[part 3 of 3: packages /AR_GEE_SWC to /AR_IHM_SWC]
AUTOSAR XML (schema 3.1.1)
package /AR_GEE_SWC
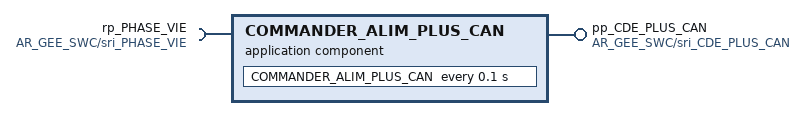
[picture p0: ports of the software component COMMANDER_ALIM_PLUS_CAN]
  application software component type COMMANDER_ALIM_PLUS_CAN
    require port rp_PHASE_VIE: unqueued-receiver-com-spec{data-element=sri_PHASE_VIE/PHASE_VIE, handle-invalid=KEEP, init-value=cst_UInt8_init/uint8_init, resync-time=0.0}, required-interface=AR_GEE_SWC/sri_PHASE_VIE
    provide port pp_CDE_PLUS_CAN: unqueued-sender-com-spec{data-element=sri_CDE_PLUS_CAN/CDE_PLUS_CAN, init-value=cst_Boolean_init/boolean_init}, provided-interface=AR_GEE_SWC/sri_CDE_PLUS_CAN
  composition type GEE_SEE
    require port rp_PHASE_VIE: unqueued-receiver-com-spec{data-element=sri_PHASE_VIE/PHASE_VIE, handle-invalid=KEEP, init-value=cst_UInt8_init/uint8_init, resync-time=0.0}, required-interface=AR_GEE_SWC/sri_PHASE_VIE
    provide port pp_CDE_PLUS_CAN: unqueued-sender-com-spec{data-element=sri_CDE_PLUS_CAN/CDE_PLUS_CAN, init-value=cst_Boolean_init/boolean_init}, provided-interface=AR_GEE_SWC/sri_CDE_PLUS_CAN
    require port rp_CAN_BACKBONE_ACTIVITY: unqueued-receiver-com-spec{data-element=sri_CAN_BACKBONE_ACTIVITY/CAN_BACKBONE_ACTIVITY, handle-invalid=KEEP, init-value=cst_Boolean_init/boolean_init, resync-time=0.0}, required-interface=AR_GEE_SWC/sri_CAN_BACKBONE_ACTIVITY
    provide port pp_CDE_LOGIC_ECM_FRONT: unqueued-sender-com-spec{data-element=sri_CDE_LOGIC_ECM_FRONT/CDE_LOGIC_ECM_FRONT, init-value=cst_Boolean_init/boolean_init}, provided-interface=AR_GEE_SWC/sri_CDE_LOGIC_ECM_FRONT
    require port rp_ETAT_MT: unqueued-receiver-com-spec{data-element=ETAT_MT, handle-invalid=KEEP, init-value=cst_UInt8_init/uint8_init, resync-time=0.0}, required-interface=sri_ETAT_MT
    provide port pp_INFO_GMP: unqueued-sender-com-spec{data-element=sri_INFO_GMP/INFO_GMP, init-value=cst_UInt8_init/uint8_init}, provided-interface=AR_GEE_SWC/sri_INFO_GMP
    provide port pp_ETAT_GMP: unqueued-sender-com-spec{data-element=ETAT_GMP, init-value=cst_UInt8_init/uint8_init}, provided-interface=sri_ETAT_GMP
    require port rp_E_APC: unqueued-receiver-com-spec{data-element=E_APC, handle-invalid=KEEP, init-value=cst_UInt8_init/uint8_init, resync-time=0.0}, required-interface=sri_E_APC
    require port rp_E_DEM: unqueued-receiver-com-spec{data-element=E_DEM, handle-invalid=KEEP, init-value=cst_UInt8_init/uint8_init, resync-time=0.0}, required-interface=sri_E_DEM
    provide port pp_ETAT_PRINCIP_SEV: unqueued-sender-com-spec{data-element=sri_ETAT_PRINCIP_SEV/ETAT_PRINCIP_SEV, init-value=cst_UInt8_init/uint8_init}, provided-interface=AR_GEE_SWC/sri_ETAT_PRINCIP_SEV
    provide port pp_CDE_APC: unqueued-sender-com-spec{data-element=sri_CDE_APC/CDE_APC, init-value=cst_Boolean_init/boolean_init}, provided-interface=AR_GEE_SWC/sri_CDE_APC
    require port rp_ETAT_RESEAU_ELECTRIQUE: unqueued-receiver-com-spec{data-element=sri_ETAT_RESEAU_ELECTRIQUE/ETAT_RESEAU_ELECTRIQUE, handle-invalid=KEEP, init-value=cst_UInt8_init/uint8_init, resync-time=0.0}, required-interface=AR_GEE_SWC/sri_ETAT_RESEAU_ELECTRIQUE
    provide port pp_CDE_ACC: unqueued-sender-com-spec{data-element=CDE_ACC, init-value=cst_Boolean_init/boolean_init}, provided-interface=sri_CDE_ACC
    6 x component:
      COMMANDER_ALIM_PLUS_CAN: type=COMMANDER_ALIM_PLUS_CAN
      COMMANDER_ALIM_LOGIC_ECM_FRONT: type=COMMANDER_ALIM_LOGIC_ECM_FRONT
      DETERMINER_INFO_GMP: type=DETERMINER_INFO_GMP
      DETERMINER_ETAT_PRINCIP_SEV: type=DETERMINER_ETAT_PRINCIP_SEV
      COMMANDER_ALIM_APC: type=COMMANDER_ALIM_APC
      COMMANDER_ALIM_ACC: type=COMMANDER_ALIM_ACC
    connect DETERMINER_ETAT_PRINCIP_SEV.pp_ETAT_PRINCIP_SEV -> COMMANDER_ALIM_APC.rp_ETAT_PRINCIP_SEV
    connect DETERMINER_ETAT_PRINCIP_SEV.pp_ETAT_PRINCIP_SEV -> COMMANDER_ALIM_ACC.rp_ETAT_PRINCIP_SEV
    delegate COMMANDER_ALIM_PLUS_CAN.rp_PHASE_VIE <-> outer port GEE_SEE/rp_PHASE_VIE
    delegate COMMANDER_ALIM_PLUS_CAN.pp_CDE_PLUS_CAN <-> outer port GEE_SEE/pp_CDE_PLUS_CAN
    delegate COMMANDER_ALIM_LOGIC_ECM_FRONT.rp_CAN_BACKBONE_ACTIVITY <-> outer port GEE_SEE/rp_CAN_BACKBONE_ACTIVITY
    delegate COMMANDER_ALIM_LOGIC_ECM_FRONT.pp_CDE_LOGIC_ECM_FRONT <-> outer port GEE_SEE/pp_CDE_LOGIC_ECM_FRONT
    delegate DETERMINER_INFO_GMP.rp_ETAT_MT <-> outer port GEE_SEE/rp_ETAT_MT
    delegate DETERMINER_INFO_GMP.pp_INFO_GMP <-> outer port GEE_SEE/pp_INFO_GMP
    delegate DETERMINER_INFO_GMP.pp_ETAT_GMP <-> outer port GEE_SEE/pp_ETAT_GMP
    delegate DETERMINER_ETAT_PRINCIP_SEV.rp_E_APC <-> outer port GEE_SEE/rp_E_APC
    delegate DETERMINER_ETAT_PRINCIP_SEV.rp_E_DEM <-> outer port GEE_SEE/rp_E_DEM
    delegate DETERMINER_ETAT_PRINCIP_SEV.pp_ETAT_PRINCIP_SEV <-> outer port GEE_SEE/pp_ETAT_PRINCIP_SEV
    delegate COMMANDER_ALIM_APC.pp_CDE_APC <-> outer port GEE_SEE/pp_CDE_APC
    delegate COMMANDER_ALIM_ACC.rp_ETAT_RESEAU_ELECTRIQUE <-> outer port GEE_SEE/rp_ETAT_RESEAU_ELECTRIQUE
    delegate COMMANDER_ALIM_ACC.pp_CDE_ACC <-> outer port GEE_SEE/pp_CDE_ACC
  composition type GEE
    provide port pp_ETAT_PRINCIP_SEV: unqueued-sender-com-spec{data-element=sri_ETAT_PRINCIP_SEV/ETAT_PRINCIP_SEV, init-value=cst_UInt8_init/uint8_init}, provided-interface=AR_GEE_SWC/sri_ETAT_PRINCIP_SEV
    provide port pp_ETAT_RESEAU_ELECTRIQUE: unqueued-sender-com-spec{data-element=sri_ETAT_RESEAU_ELECTRIQUE/ETAT_RESEAU_ELECTRIQUE, init-value=cst_UInt8_init/uint8_init}, provided-interface=AR_GEE_SWC/sri_ETAT_RESEAU_ELECTRIQUE
    provide port pp_CDE_APC: unqueued-sender-com-spec{data-element=sri_CDE_APC/CDE_APC, init-value=cst_Boolean_init/boolean_init}, provided-interface=AR_GEE_SWC/sri_CDE_APC
    require port rp_PHASE_VIE: unqueued-receiver-com-spec{data-element=sri_PHASE_VIE/PHASE_VIE, handle-invalid=KEEP, init-value=cst_UInt8_init/uint8_init, resync-time=0.0}, required-interface=AR_GEE_SWC/sri_PHASE_VIE
    provide port pp_CDE_PLUS_CAN: unqueued-sender-com-spec{data-element=sri_CDE_PLUS_CAN/CDE_PLUS_CAN, init-value=cst_Boolean_init/boolean_init}, provided-interface=AR_GEE_SWC/sri_CDE_PLUS_CAN
    require port rp_TENSION_BATTERIE_UCFREIN: unqueued-receiver-com-spec{data-element=TENSION_BATTERIE_UCFREIN, handle-invalid=KEEP, init-value=cst_UInt8_init/uint8_init, resync-time=0.0}, required-interface=sri_TENSION_BATTERIE_UCFREIN
    require port rp_CAN_BACKBONE_ACTIVITY: unqueued-receiver-com-spec{data-element=sri_CAN_BACKBONE_ACTIVITY/CAN_BACKBONE_ACTIVITY, handle-invalid=KEEP, init-value=cst_Boolean_init/boolean_init, resync-time=0.0}, required-interface=AR_GEE_SWC/sri_CAN_BACKBONE_ACTIVITY
    provide port pp_CDE_LOGIC_ECM_FRONT: unqueued-sender-com-spec{data-element=sri_CDE_LOGIC_ECM_FRONT/CDE_LOGIC_ECM_FRONT, init-value=cst_Boolean_init/boolean_init}, provided-interface=AR_GEE_SWC/sri_CDE_LOGIC_ECM_FRONT
    provide port pp_ETAT_GEN: unqueued-sender-com-spec{data-element=ETAT_GEN, init-value=cst_Boolean_init/boolean_init}, provided-interface=sri_ETAT_GEN
    require port rp_VITESSE_LONGITUDINALE: unqueued-receiver-com-spec{data-element=sri_VITESSE_LONGITUDINALE/VITESSE_LONGITUDINALE, handle-invalid=KEEP, init-value=cst_UInt16_init/uint16_init, resync-time=0.0}, required-interface=AR_GEE_SWC/sri_VITESSE_LONGITUDINALE
    provide port pp_MODE_ECO: unqueued-sender-com-spec{data-element=MODE_ECO, init-value=cst_Boolean_init/boolean_init}, provided-interface=sri_MODE_ECO
    require port rp_ETAT_MT: unqueued-receiver-com-spec{data-element=ETAT_MT, handle-invalid=KEEP, init-value=cst_UInt8_init/uint8_init, resync-time=0.0}, required-interface=sri_ETAT_MT
    provide port pp_ETAT_GMP: unqueued-sender-com-spec{data-element=ETAT_GMP, init-value=cst_UInt8_init/uint8_init}, provided-interface=sri_ETAT_GMP
    provide port pp_INFO_GMP: unqueued-sender-com-spec{data-element=sri_INFO_GMP/INFO_GMP, init-value=cst_UInt8_init/uint8_init}, provided-interface=AR_GEE_SWC/sri_INFO_GMP
    require port rp_E_APC: unqueued-receiver-com-spec{data-element=E_APC, handle-invalid=KEEP, init-value=cst_UInt8_init/uint8_init, resync-time=0.0}, required-interface=sri_E_APC
    require port rp_E_DEM: unqueued-receiver-com-spec{data-element=E_DEM, handle-invalid=KEEP, init-value=cst_UInt8_init/uint8_init, resync-time=0.0}, required-interface=sri_E_DEM
    provide port pp_CDE_ACC: unqueued-sender-com-spec{data-element=CDE_ACC, init-value=cst_Boolean_init/boolean_init}, provided-interface=sri_CDE_ACC
    require port rp_U_BAT: unqueued-receiver-com-spec{data-element=U_BAT, handle-invalid=KEEP, init-value=cst_UInt16_init/uint16_init, resync-time=0.0}, required-interface=sri_U_BAT
    component MDL_GEE: type=MDL_GEE
    delegate MDL_GEE.rp_PHASE_VIE <-> outer port GEE/rp_PHASE_VIE
    delegate MDL_GEE.pp_CDE_PLUS_CAN <-> outer port GEE/pp_CDE_PLUS_CAN
    delegate MDL_GEE.rp_TENSION_BATTERIE_UCFREIN <-> outer port GEE/rp_TENSION_BATTERIE_UCFREIN
    delegate MDL_GEE.rp_CAN_BACKBONE_ACTIVITY <-> outer port GEE/rp_CAN_BACKBONE_ACTIVITY
    delegate MDL_GEE.pp_CDE_LOGIC_ECM_FRONT <-> outer port GEE/pp_CDE_LOGIC_ECM_FRONT
    delegate MDL_GEE.pp_ETAT_GEN <-> outer port GEE/pp_ETAT_GEN
    delegate MDL_GEE.rp_VITESSE_LONGITUDINALE <-> outer port GEE/rp_VITESSE_LONGITUDINALE
    delegate MDL_GEE.pp_ETAT_RESEAU_ELECTRIQUE <-> outer port GEE/pp_ETAT_RESEAU_ELECTRIQUE
    delegate MDL_GEE.pp_MODE_ECO <-> outer port GEE/pp_MODE_ECO
    delegate MDL_GEE.rp_ETAT_MT <-> outer port GEE/rp_ETAT_MT
    delegate MDL_GEE.pp_ETAT_GMP <-> outer port GEE/pp_ETAT_GMP
    delegate MDL_GEE.pp_INFO_GMP <-> outer port GEE/pp_INFO_GMP
    delegate MDL_GEE.rp_E_APC <-> outer port GEE/rp_E_APC
    delegate MDL_GEE.rp_E_DEM <-> outer port GEE/rp_E_DEM
    delegate MDL_GEE.pp_ETAT_PRINCIP_SEV <-> outer port GEE/pp_ETAT_PRINCIP_SEV
    delegate MDL_GEE.pp_CDE_APC <-> outer port GEE/pp_CDE_APC
    delegate MDL_GEE.pp_CDE_ACC <-> outer port GEE/pp_CDE_ACC
    delegate MDL_GEE.rp_U_BAT <-> outer port GEE/rp_U_BAT
  composition type MDL_GEE
    require port rp_PHASE_VIE: unqueued-receiver-com-spec{data-element=sri_PHASE_VIE/PHASE_VIE, handle-invalid=KEEP, init-value=cst_UInt8_init/uint8_init, resync-time=0.0}, required-interface=AR_GEE_SWC/sri_PHASE_VIE
    provide port pp_CDE_PLUS_CAN: unqueued-sender-com-spec{data-element=sri_CDE_PLUS_CAN/CDE_PLUS_CAN, init-value=cst_Boolean_init/boolean_init}, provided-interface=AR_GEE_SWC/sri_CDE_PLUS_CAN
    require port rp_TENSION_BATTERIE_UCFREIN: unqueued-receiver-com-spec{data-element=TENSION_BATTERIE_UCFREIN, handle-invalid=KEEP, init-value=cst_UInt8_init/uint8_init, resync-time=0.0}, required-interface=sri_TENSION_BATTERIE_UCFREIN
    require port rp_CAN_BACKBONE_ACTIVITY: unqueued-receiver-com-spec{data-element=sri_CAN_BACKBONE_ACTIVITY/CAN_BACKBONE_ACTIVITY, handle-invalid=KEEP, init-value=cst_Boolean_init/boolean_init, resync-time=0.0}, required-interface=AR_GEE_SWC/sri_CAN_BACKBONE_ACTIVITY
    provide port pp_CDE_LOGIC_ECM_FRONT: unqueued-sender-com-spec{data-element=sri_CDE_LOGIC_ECM_FRONT/CDE_LOGIC_ECM_FRONT, init-value=cst_Boolean_init/boolean_init}, provided-interface=AR_GEE_SWC/sri_CDE_LOGIC_ECM_FRONT
    provide port pp_ETAT_GEN: unqueued-sender-com-spec{data-element=ETAT_GEN, init-value=cst_Boolean_init/boolean_init}, provided-interface=sri_ETAT_GEN
    require port rp_VITESSE_LONGITUDINALE: unqueued-receiver-com-spec{data-element=sri_VITESSE_LONGITUDINALE/VITESSE_LONGITUDINALE, handle-invalid=KEEP, init-value=cst_UInt16_init/uint16_init, resync-time=0.0}, required-interface=AR_GEE_SWC/sri_VITESSE_LONGITUDINALE
    provide port pp_ETAT_RESEAU_ELECTRIQUE: unqueued-sender-com-spec{data-element=sri_ETAT_RESEAU_ELECTRIQUE/ETAT_RESEAU_ELECTRIQUE, init-value=cst_UInt8_init/uint8_init}, provided-interface=AR_GEE_SWC/sri_ETAT_RESEAU_ELECTRIQUE
    provide port pp_MODE_ECO: unqueued-sender-com-spec{data-element=MODE_ECO, init-value=cst_Boolean_init/boolean_init}, provided-interface=sri_MODE_ECO
    require port rp_ETAT_MT: unqueued-receiver-com-spec{data-element=ETAT_MT, handle-invalid=KEEP, init-value=cst_UInt8_init/uint8_init, resync-time=0.0}, required-interface=sri_ETAT_MT
    provide port pp_ETAT_GMP: unqueued-sender-com-spec{data-element=ETAT_GMP, init-value=cst_UInt8_init/uint8_init}, provided-interface=sri_ETAT_GMP
    provide port pp_INFO_GMP: unqueued-sender-com-spec{data-element=sri_INFO_GMP/INFO_GMP, init-value=cst_UInt8_init/uint8_init}, provided-interface=AR_GEE_SWC/sri_INFO_GMP
    require port rp_E_APC: unqueued-receiver-com-spec{data-element=E_APC, handle-invalid=KEEP, init-value=cst_UInt8_init/uint8_init, resync-time=0.0}, required-interface=sri_E_APC
    require port rp_E_DEM: unqueued-receiver-com-spec{data-element=E_DEM, handle-invalid=KEEP, init-value=cst_UInt8_init/uint8_init, resync-time=0.0}, required-interface=sri_E_DEM
    provide port pp_ETAT_PRINCIP_SEV: unqueued-sender-com-spec{data-element=sri_ETAT_PRINCIP_SEV/ETAT_PRINCIP_SEV, init-value=cst_UInt8_init/uint8_init}, provided-interface=AR_GEE_SWC/sri_ETAT_PRINCIP_SEV
    provide port pp_CDE_APC: unqueued-sender-com-spec{data-element=sri_CDE_APC/CDE_APC, init-value=cst_Boolean_init/boolean_init}, provided-interface=AR_GEE_SWC/sri_CDE_APC
    provide port pp_CDE_ACC: unqueued-sender-com-spec{data-element=CDE_ACC, init-value=cst_Boolean_init/boolean_init}, provided-interface=sri_CDE_ACC
    require port rp_U_BAT: unqueued-receiver-com-spec{data-element=U_BAT, handle-invalid=KEEP, init-value=cst_UInt16_init/uint16_init, resync-time=0.0}, required-interface=sri_U_BAT
    component GEE_SEE: type=GEE_SEE
    component GEE_AQEB: type=GEE_AQEB
    component GEE_PEE: type=GEE_PEE
    delegate GEE_SEE.rp_PHASE_VIE <-> outer port MDL_GEE/rp_PHASE_VIE
    delegate GEE_SEE.pp_CDE_PLUS_CAN <-> outer port MDL_GEE/pp_CDE_PLUS_CAN
    delegate GEE_AQEB.rp_TENSION_BATTERIE_UCFREIN <-> outer port MDL_GEE/rp_TENSION_BATTERIE_UCFREIN
    delegate GEE_SEE.rp_CAN_BACKBONE_ACTIVITY <-> outer port MDL_GEE/rp_CAN_BACKBONE_ACTIVITY
    delegate GEE_SEE.pp_CDE_LOGIC_ECM_FRONT <-> outer port MDL_GEE/pp_CDE_LOGIC_ECM_FRONT
    delegate GEE_PEE.pp_ETAT_GEN <-> outer port MDL_GEE/pp_ETAT_GEN
    delegate GEE_AQEB.rp_VITESSE_LONGITUDINALE <-> outer port MDL_GEE/rp_VITESSE_LONGITUDINALE
    delegate GEE_AQEB.pp_ETAT_RESEAU_ELECTRIQUE <-> outer port MDL_GEE/pp_ETAT_RESEAU_ELECTRIQUE
    delegate GEE_AQEB.pp_MODE_ECO <-> outer port MDL_GEE/pp_MODE_ECO
    delegate GEE_SEE.rp_ETAT_MT <-> outer port MDL_GEE/rp_ETAT_MT
    delegate GEE_SEE.pp_ETAT_GMP <-> outer port MDL_GEE/pp_ETAT_GMP
    delegate GEE_SEE.pp_INFO_GMP <-> outer port MDL_GEE/pp_INFO_GMP
    delegate GEE_SEE.rp_E_APC <-> outer port MDL_GEE/rp_E_APC
    delegate GEE_SEE.rp_E_DEM <-> outer port MDL_GEE/rp_E_DEM
    delegate GEE_SEE.pp_ETAT_PRINCIP_SEV <-> outer port MDL_GEE/pp_ETAT_PRINCIP_SEV
    delegate GEE_SEE.pp_CDE_APC <-> outer port MDL_GEE/pp_CDE_APC
    delegate GEE_SEE.pp_CDE_ACC <-> outer port MDL_GEE/pp_CDE_ACC
    delegate GEE_AQEB.rp_U_BAT <-> outer port MDL_GEE/rp_U_BAT
    connect GEE_AQEB.pp_ETAT_RESEAU_ELECTRIQUE -> GEE_SEE.rp_ETAT_RESEAU_ELECTRIQUE
    connect GEE_SEE.pp_INFO_GMP -> GEE_AQEB.rp_INFO_GMP
    connect GEE_SEE.pp_INFO_GMP -> GEE_PEE.rp_INFO_GMP
    connect GEE_PEE.pp_ETAT_PRODUCTION -> GEE_AQEB.rp_ETAT_PRODUCTION
  internal behavior ib_COMMANDER_ALIM_PLUS_CAN: component=COMMANDER_ALIM_PLUS_CAN
    timing event evt_COMMANDER_ALIM_PLUS_CAN: start-on-event=COMMANDER_ALIM_PLUS_CAN, period=0.1
    runnable COMMANDER_ALIM_PLUS_CAN
      data read access dra_PHASE_VIE: data-element=rp_PHASE_VIE.PHASE_VIE
      data write access dwa_CDE_PLUS_CAN: data-element=pp_CDE_PLUS_CAN.CDE_PLUS_CAN
  sender receiver interface sri_PHASE_VIE
    data PHASE_VIE: type=AR_GEE_SWC/UInt8
  constant specification cst_UInt8_init
    value:
      integer literal uint8_init: type=AR_GEE_SWC/UInt8, value=0
  sender receiver interface sri_CDE_PLUS_CAN
    data CDE_PLUS_CAN: type=AR_GEE_SWC/Boolean
  constant specification cst_Boolean_init
    value:
      boolean literal boolean_init: type=AR_GEE_SWC/Boolean, value=false
  swc implementation implem_COMMANDER_ALIM_PLUS_CAN: programming-language=C, behavior=ib_COMMANDER_ALIM_PLUS_CAN
    code-descriptors:
      code implem_COMMANDER_ALIM_PLUS_CAN: type=SRC
        xfile COMMANDER_ALIM_PLUS_CAN.c: url=Src_C/COMMANDER_ALIM_PLUS_CAN.c
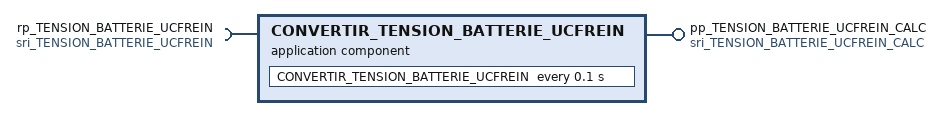
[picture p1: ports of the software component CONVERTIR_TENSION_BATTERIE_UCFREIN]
  application software component type CONVERTIR_TENSION_BATTERIE_UCFREIN
    require port rp_TENSION_BATTERIE_UCFREIN: unqueued-receiver-com-spec{data-element=TENSION_BATTERIE_UCFREIN, handle-invalid=KEEP, init-value=cst_UInt8_init/uint8_init, resync-time=0.0}, required-interface=sri_TENSION_BATTERIE_UCFREIN
    provide port pp_TENSION_BATTERIE_UCFREIN_CALC: unqueued-sender-com-spec{data-element=TENSION_BATTERIE_UCFREIN_CALC, init-value=double_init}, provided-interface=sri_TENSION_BATTERIE_UCFREIN_CALC
  composition type GEE_AQEB
    require port rp_TENSION_BATTERIE_UCFREIN: unqueued-receiver-com-spec{data-element=TENSION_BATTERIE_UCFREIN, handle-invalid=KEEP, init-value=cst_UInt8_init/uint8_init, resync-time=0.0}, required-interface=sri_TENSION_BATTERIE_UCFREIN
    require port rp_INFO_GMP: unqueued-receiver-com-spec{data-element=sri_INFO_GMP/INFO_GMP, handle-invalid=KEEP, init-value=cst_UInt8_init/uint8_init, resync-time=0.0}, required-interface=AR_GEE_SWC/sri_INFO_GMP
    require port rp_VITESSE_LONGITUDINALE: unqueued-receiver-com-spec{data-element=sri_VITESSE_LONGITUDINALE/VITESSE_LONGITUDINALE, handle-invalid=KEEP, init-value=cst_UInt16_init/uint16_init, resync-time=0.0}, required-interface=AR_GEE_SWC/sri_VITESSE_LONGITUDINALE
    provide port pp_ETAT_RESEAU_ELECTRIQUE: unqueued-sender-com-spec{data-element=sri_ETAT_RESEAU_ELECTRIQUE/ETAT_RESEAU_ELECTRIQUE, init-value=cst_UInt8_init/uint8_init}, provided-interface=AR_GEE_SWC/sri_ETAT_RESEAU_ELECTRIQUE
    provide port pp_MODE_ECO: unqueued-sender-com-spec{data-element=MODE_ECO, init-value=cst_Boolean_init/boolean_init}, provided-interface=sri_MODE_ECO
    require port rp_U_BAT: unqueued-receiver-com-spec{data-element=U_BAT, handle-invalid=KEEP, init-value=cst_UInt16_init/uint16_init, resync-time=0.0}, required-interface=sri_U_BAT
    require port rp_ETAT_PRODUCTION: unqueued-receiver-com-spec{data-element=ETAT_PRODUCTION, handle-invalid=KEEP, init-value=cst_Boolean_init/boolean_init, resync-time=0.0}, required-interface=sri_ETAT_PRODUCTION
    7 x component:
      CONVERTIR_TENSION_BATTERIE_UCFREIN: type=CONVERTIR_TENSION_BATTERIE_UCFREIN
      DETERMINER_ETAT_RESEAU_ELECTRIQUE_TA: type=DETERMINER_ETAT_RESEAU_ELECTRIQUE_TA
      DETERMINER_ETAT_RESEAU_ELECTRIQUE_TI: type=DETERMINER_ETAT_RESEAU_ELECTRIQUE_TI
      DETERMINER_ETAT_RESEAU_ELECTRIQUE_TI_TA: type=DETERMINER_ETAT_RESEAU_ELECTRIQUE_TI_TA
      DETERMINER_COHERENCE_TENSION_BATTERIE: type=DETERMINER_COHERENCE_TENSION_BATTERIE
      DETERMINER_CREDIT_TEMPS_TI_NOMINAL: type=DETERMINER_CREDIT_TEMPS_TI_NOMINAL
      DETERMINER_TENSION_BATTERIE_PAR_TENSION_BSI: type=DETERMINER_TENSION_BATTERIE_PAR_TENSION_BSI
    connect CONVERTIR_TENSION_BATTERIE_UCFREIN.pp_TENSION_BATTERIE_UCFREIN_CALC -> DETERMINER_COHERENCE_TENSION_BATTERIE.rp_TENSION_BATTERIE_UCFREIN_CALC
    connect DETERMINER_ETAT_RESEAU_ELECTRIQUE_TA.pp_ETAT_RESEAU_ELEC_TA -> DETERMINER_ETAT_RESEAU_ELECTRIQUE_TI_TA.rp_ETAT_RESEAU_ELEC_TA
    connect DETERMINER_COHERENCE_TENSION_BATTERIE.pp_U_BATT_SECU -> DETERMINER_ETAT_RESEAU_ELECTRIQUE_TA.rp_U_BATT_SECU
    connect DETERMINER_ETAT_RESEAU_ELECTRIQUE_TI.pp_ETAT_RESEAU_ELEC_TI -> DETERMINER_ETAT_RESEAU_ELECTRIQUE_TI_TA.rp_ETAT_RESEAU_ELEC_TI
    connect DETERMINER_CREDIT_TEMPS_TI_NOMINAL.pp_CREDIT_TPS_TI_NOMINAL_ON -> DETERMINER_ETAT_RESEAU_ELECTRIQUE_TI_TA.rp_CREDIT_TPS_TI_NOMINAL_ON
    connect DETERMINER_TENSION_BATTERIE_PAR_TENSION_BSI.pp_U_BSI_FILTREE -> DETERMINER_COHERENCE_TENSION_BATTERIE.rp_U_BSI_FILTREE
    delegate CONVERTIR_TENSION_BATTERIE_UCFREIN.rp_TENSION_BATTERIE_UCFREIN <-> outer port GEE_AQEB/rp_TENSION_BATTERIE_UCFREIN
    delegate DETERMINER_ETAT_RESEAU_ELECTRIQUE_TI_TA.rp_INFO_GMP <-> outer port GEE_AQEB/rp_INFO_GMP
    delegate DETERMINER_ETAT_RESEAU_ELECTRIQUE_TI_TA.rp_VITESSE_LONGITUDINALE <-> outer port GEE_AQEB/rp_VITESSE_LONGITUDINALE
    delegate DETERMINER_ETAT_RESEAU_ELECTRIQUE_TI_TA.pp_ETAT_RESEAU_ELECTRIQUE <-> outer port GEE_AQEB/pp_ETAT_RESEAU_ELECTRIQUE
    delegate DETERMINER_ETAT_RESEAU_ELECTRIQUE_TI_TA.pp_MODE_ECO <-> outer port GEE_AQEB/pp_MODE_ECO
    delegate DETERMINER_TENSION_BATTERIE_PAR_TENSION_BSI.rp_U_BAT <-> outer port GEE_AQEB/rp_U_BAT
    delegate DETERMINER_ETAT_RESEAU_ELECTRIQUE_TA.rp_ETAT_PRODUCTION <-> outer port GEE_AQEB/rp_ETAT_PRODUCTION
    delegate DETERMINER_COHERENCE_TENSION_BATTERIE.rp_INFO_GMP <-> outer port GEE_AQEB/rp_INFO_GMP
    delegate DETERMINER_CREDIT_TEMPS_TI_NOMINAL.rp_INFO_GMP <-> outer port GEE_AQEB/rp_INFO_GMP
  internal behavior ib_CONVERTIR_TENSION_BATTERIE_UCFREIN: component=CONVERTIR_TENSION_BATTERIE_UCFREIN
    timing event evt_CONVERTIR_TENSION_BATTERIE_UCFREIN: start-on-event=CONVERTIR_TENSION_BATTERIE_UCFREIN, period=0.1
    runnable CONVERTIR_TENSION_BATTERIE_UCFREIN
      data read access dra_TENSION_BATTERIE_UCFREIN: data-element=rp_TENSION_BATTERIE_UCFREIN.TENSION_BATTERIE_UCFREIN
      data write access dwa_TENSION_BATTERIE_UCFREIN_CALC: data-element=pp_TENSION_BATTERIE_UCFREIN_CALC.TENSION_BATTERIE_UCFREIN_CALC
  sender receiver interface sri_TENSION_BATTERIE_UCFREIN
    data TENSION_BATTERIE_UCFREIN: type=AR_GEE_SWC/UInt8
  sender receiver interface sri_TENSION_BATTERIE_UCFREIN_CALC
    data TENSION_BATTERIE_UCFREIN_CALC: type=double_type
  real type double_type: encoding=SINGLE
  constant specification cst_double_type_init
    value:
      real literal double_init: type=double_type, value=0.0
  swc implementation implem_CONVERTIR_TENSION_BATTERIE_UCFREIN: programming-language=C, behavior=ib_CONVERTIR_TENSION_BATTERIE_UCFREIN
    code-descriptors:
      code implem_CONVERTIR_TENSION_BATTERIE_UCFREIN: type=SRC
        xfile CONVERTIR_TENSION_BATTERIE_UCFREIN.c: url=Src_C/CONVERTIR_TENSION_BATTERIE_UCFREIN.c
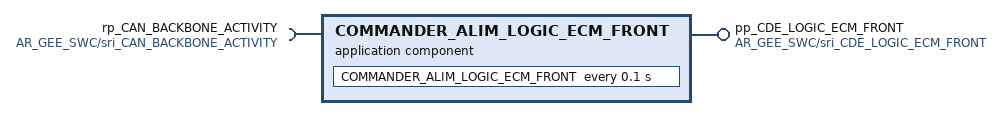
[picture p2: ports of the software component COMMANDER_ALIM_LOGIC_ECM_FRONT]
  application software component type COMMANDER_ALIM_LOGIC_ECM_FRONT
    require port rp_CAN_BACKBONE_ACTIVITY: unqueued-receiver-com-spec{data-element=sri_CAN_BACKBONE_ACTIVITY/CAN_BACKBONE_ACTIVITY, handle-invalid=KEEP, init-value=cst_Boolean_init/boolean_init, resync-time=0.0}, required-interface=AR_GEE_SWC/sri_CAN_BACKBONE_ACTIVITY
    provide port pp_CDE_LOGIC_ECM_FRONT: unqueued-sender-com-spec{data-element=sri_CDE_LOGIC_ECM_FRONT/CDE_LOGIC_ECM_FRONT, init-value=cst_Boolean_init/boolean_init}, provided-interface=AR_GEE_SWC/sri_CDE_LOGIC_ECM_FRONT
  internal behavior ib_COMMANDER_ALIM_LOGIC_ECM_FRONT: component=COMMANDER_ALIM_LOGIC_ECM_FRONT
    timing event evt_COMMANDER_ALIM_LOGIC_ECM_FRONT: start-on-event=COMMANDER_ALIM_LOGIC_ECM_FRONT, period=0.1
    runnable COMMANDER_ALIM_LOGIC_ECM_FRONT
      data read access dra_CAN_BACKBONE_ACTIVITY: data-element=rp_CAN_BACKBONE_ACTIVITY.CAN_BACKBONE_ACTIVITY
      data write access dwa_CDE_LOGIC_ECM_FRONT: data-element=pp_CDE_LOGIC_ECM_FRONT.CDE_LOGIC_ECM_FRONT
  sender receiver interface sri_CAN_BACKBONE_ACTIVITY
    data CAN_BACKBONE_ACTIVITY: type=AR_GEE_SWC/Boolean
  sender receiver interface sri_CDE_LOGIC_ECM_FRONT
    data CDE_LOGIC_ECM_FRONT: type=AR_GEE_SWC/Boolean
  swc implementation implem_COMMANDER_ALIM_LOGIC_ECM_FRONT: programming-language=C, behavior=ib_COMMANDER_ALIM_LOGIC_ECM_FRONT
    code-descriptors:
      code implem_COMMANDER_ALIM_LOGIC_ECM_FRONT: type=SRC
        xfile COMMANDER_ALIM_LOGIC_ECM_FRONT.c: url=Src_C/COMMANDER_ALIM_LOGIC_ECM_FRONT.c
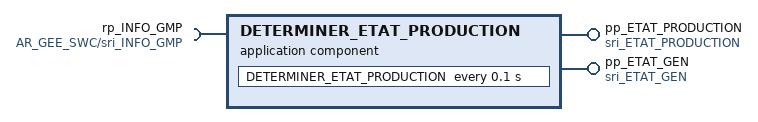
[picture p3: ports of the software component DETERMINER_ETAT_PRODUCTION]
  application software component type DETERMINER_ETAT_PRODUCTION
    require port rp_INFO_GMP: unqueued-receiver-com-spec{data-element=sri_INFO_GMP/INFO_GMP, handle-invalid=KEEP, init-value=cst_UInt8_init/uint8_init, resync-time=0.0}, required-interface=AR_GEE_SWC/sri_INFO_GMP
    provide port pp_ETAT_PRODUCTION: unqueued-sender-com-spec{data-element=ETAT_PRODUCTION, init-value=cst_Boolean_init/boolean_init}, provided-interface=sri_ETAT_PRODUCTION
    provide port pp_ETAT_GEN: unqueued-sender-com-spec{data-element=ETAT_GEN, init-value=cst_Boolean_init/boolean_init}, provided-interface=sri_ETAT_GEN
  composition type GEE_PEE
    require port rp_INFO_GMP: unqueued-receiver-com-spec{data-element=sri_INFO_GMP/INFO_GMP, handle-invalid=KEEP, init-value=cst_UInt8_init/uint8_init, resync-time=0.0}, required-interface=AR_GEE_SWC/sri_INFO_GMP
    provide port pp_ETAT_PRODUCTION: unqueued-sender-com-spec{data-element=ETAT_PRODUCTION, init-value=cst_Boolean_init/boolean_init}, provided-interface=sri_ETAT_PRODUCTION
    provide port pp_ETAT_GEN: unqueued-sender-com-spec{data-element=ETAT_GEN, init-value=cst_Boolean_init/boolean_init}, provided-interface=sri_ETAT_GEN
    component DETERMINER_ETAT_PRODUCTION: type=DETERMINER_ETAT_PRODUCTION
    delegate DETERMINER_ETAT_PRODUCTION.rp_INFO_GMP <-> outer port GEE_PEE/rp_INFO_GMP
    delegate DETERMINER_ETAT_PRODUCTION.pp_ETAT_PRODUCTION <-> outer port GEE_PEE/pp_ETAT_PRODUCTION
    delegate DETERMINER_ETAT_PRODUCTION.pp_ETAT_GEN <-> outer port GEE_PEE/pp_ETAT_GEN
  internal behavior ib_DETERMINER_ETAT_PRODUCTION: component=DETERMINER_ETAT_PRODUCTION
    timing event evt_DETERMINER_ETAT_PRODUCTION: start-on-event=DETERMINER_ETAT_PRODUCTION, period=0.1
    runnable DETERMINER_ETAT_PRODUCTION
      data read access dra_INFO_GMP: data-element=rp_INFO_GMP.INFO_GMP
      data write access dwa_ETAT_PRODUCTION: data-element=pp_ETAT_PRODUCTION.ETAT_PRODUCTION
      data write access dwa_ETAT_GEN: data-element=pp_ETAT_GEN.ETAT_GEN
  sender receiver interface sri_INFO_GMP
    data INFO_GMP: type=AR_GEE_SWC/UInt8
  sender receiver interface sri_ETAT_PRODUCTION
    data ETAT_PRODUCTION: type=AR_GEE_SWC/Boolean
  sender receiver interface sri_ETAT_GEN
    data ETAT_GEN: type=AR_GEE_SWC/Boolean
  swc implementation implem_DETERMINER_ETAT_PRODUCTION: programming-language=C, behavior=ib_DETERMINER_ETAT_PRODUCTION
    code-descriptors:
      code implem_DETERMINER_ETAT_PRODUCTION: type=SRC
        xfile DETERMINER_ETAT_PRODUCTION.c: url=Src_C/DETERMINER_ETAT_PRODUCTION.c
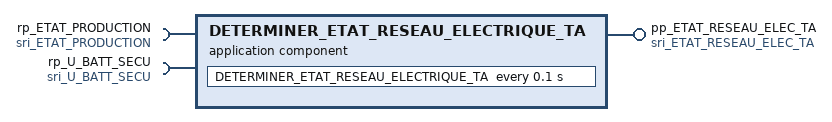
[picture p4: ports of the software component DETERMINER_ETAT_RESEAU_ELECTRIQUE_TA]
  application software component type DETERMINER_ETAT_RESEAU_ELECTRIQUE_TA
    require port rp_ETAT_PRODUCTION: unqueued-receiver-com-spec{data-element=ETAT_PRODUCTION, handle-invalid=KEEP, init-value=cst_Boolean_init/boolean_init, resync-time=0.0}, required-interface=sri_ETAT_PRODUCTION
    require port rp_U_BATT_SECU: unqueued-receiver-com-spec{data-element=U_BATT_SECU, handle-invalid=KEEP, init-value=double_init, resync-time=0.0}, required-interface=sri_U_BATT_SECU
    provide port pp_ETAT_RESEAU_ELEC_TA: unqueued-sender-com-spec{data-element=ETAT_RESEAU_ELEC_TA, init-value=cst_UInt8_init/uint8_init}, provided-interface=sri_ETAT_RESEAU_ELEC_TA
  internal behavior ib_DETERMINER_ETAT_RESEAU_ELECTRIQUE_TA: component=DETERMINER_ETAT_RESEAU_ELECTRIQUE_TA
    timing event evt_DETERMINER_ETAT_RESEAU_ELECTRIQUE_TA: start-on-event=DETERMINER_ETAT_RESEAU_ELECTRIQUE_TA, period=0.1
    runnable DETERMINER_ETAT_RESEAU_ELECTRIQUE_TA
      data read access dra_ETAT_PRODUCTION: data-element=rp_ETAT_PRODUCTION.ETAT_PRODUCTION
      data read access dra_U_BATT_SECU: data-element=rp_U_BATT_SECU.U_BATT_SECU
      data write access dwa_ETAT_RESEAU_ELEC_TA: data-element=pp_ETAT_RESEAU_ELEC_TA.ETAT_RESEAU_ELEC_TA
  sender receiver interface sri_U_BATT_SECU
    data U_BATT_SECU: type=double_type
  sender receiver interface sri_ETAT_RESEAU_ELEC_TA
    data ETAT_RESEAU_ELEC_TA: type=AR_GEE_SWC/UInt8
  swc implementation implem_DETERMINER_ETAT_RESEAU_ELECTRIQUE_TA: programming-language=C, behavior=ib_DETERMINER_ETAT_RESEAU_ELECTRIQUE_TA
    code-descriptors:
      code implem_DETERMINER_ETAT_RESEAU_ELECTRIQUE_TA: type=SRC
        xfile DETERMINER_ETAT_RESEAU_ELECTRIQUE_TA.c: url=Src_C/DETERMINER_ETAT_RESEAU_ELECTRIQUE_TA.c
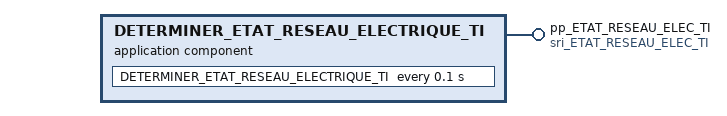
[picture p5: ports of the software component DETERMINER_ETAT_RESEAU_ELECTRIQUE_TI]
  application software component type DETERMINER_ETAT_RESEAU_ELECTRIQUE_TI
    provide port pp_ETAT_RESEAU_ELEC_TI: unqueued-sender-com-spec{data-element=ETAT_RESEAU_ELEC_TI, init-value=cst_UInt8_init/uint8_init}, provided-interface=sri_ETAT_RESEAU_ELEC_TI
  internal behavior ib_DETERMINER_ETAT_RESEAU_ELECTRIQUE_TI: component=DETERMINER_ETAT_RESEAU_ELECTRIQUE_TI
    timing event evt_DETERMINER_ETAT_RESEAU_ELECTRIQUE_TI: start-on-event=DETERMINER_ETAT_RESEAU_ELECTRIQUE_TI, period=0.1
    runnable DETERMINER_ETAT_RESEAU_ELECTRIQUE_TI
      data write access dwa_ETAT_RESEAU_ELEC_TI: data-element=pp_ETAT_RESEAU_ELEC_TI.ETAT_RESEAU_ELEC_TI
  sender receiver interface sri_ETAT_RESEAU_ELEC_TI
    data ETAT_RESEAU_ELEC_TI: type=AR_GEE_SWC/UInt8
  swc implementation implem_DETERMINER_ETAT_RESEAU_ELECTRIQUE_TI: programming-language=C, behavior=ib_DETERMINER_ETAT_RESEAU_ELECTRIQUE_TI
    code-descriptors:
      code implem_DETERMINER_ETAT_RESEAU_ELECTRIQUE_TI: type=SRC
        xfile DETERMINER_ETAT_RESEAU_ELECTRIQUE_TI.c: url=Src_C/DETERMINER_ETAT_RESEAU_ELECTRIQUE_TI.c
  sender receiver interface sri_E_APC
    data E_APC: type=AR_GEE_SWC/UInt8
  sender receiver interface sri_U_BAT
    data U_BAT: type=AR_GEE_SWC/UInt16
  constant specification cst_UInt16_init
    value:
      integer literal uint16_init: type=AR_GEE_SWC/UInt16, value=0
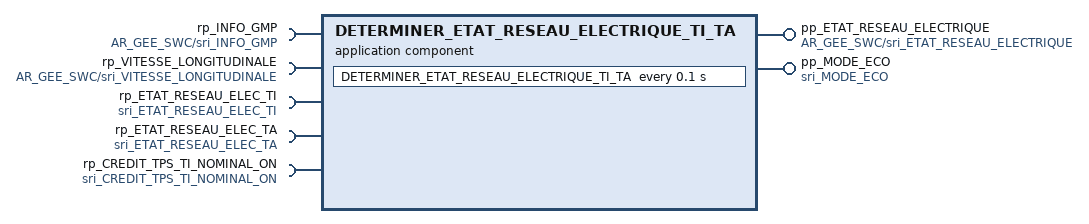
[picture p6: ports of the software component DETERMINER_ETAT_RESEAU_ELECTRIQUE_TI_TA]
  application software component type DETERMINER_ETAT_RESEAU_ELECTRIQUE_TI_TA
    5 x require port:
      rp_INFO_GMP: unqueued-receiver-com-spec{data-element=sri_INFO_GMP/INFO_GMP, handle-invalid=KEEP, init-value=cst_UInt8_init/uint8_init, resync-time=0.0}, required-interface=AR_GEE_SWC/sri_INFO_GMP
      rp_VITESSE_LONGITUDINALE: unqueued-receiver-com-spec{data-element=sri_VITESSE_LONGITUDINALE/VITESSE_LONGITUDINALE, handle-invalid=KEEP, init-value=cst_UInt16_init/uint16_init, resync-time=0.0}, required-interface=AR_GEE_SWC/sri_VITESSE_LONGITUDINALE
      rp_ETAT_RESEAU_ELEC_TI: unqueued-receiver-com-spec{data-element=ETAT_RESEAU_ELEC_TI, handle-invalid=KEEP, init-value=cst_UInt8_init/uint8_init, resync-time=0.0}, required-interface=sri_ETAT_RESEAU_ELEC_TI
      rp_ETAT_RESEAU_ELEC_TA: unqueued-receiver-com-spec{data-element=ETAT_RESEAU_ELEC_TA, handle-invalid=KEEP, init-value=cst_UInt8_init/uint8_init, resync-time=0.0}, required-interface=sri_ETAT_RESEAU_ELEC_TA
      rp_CREDIT_TPS_TI_NOMINAL_ON: unqueued-receiver-com-spec{data-element=ON, handle-invalid=KEEP, init-value=cst_Boolean_init/boolean_init, resync-time=0.0}, required-interface=sri_CREDIT_TPS_TI_NOMINAL_ON
    provide port pp_ETAT_RESEAU_ELECTRIQUE: unqueued-sender-com-spec{data-element=sri_ETAT_RESEAU_ELECTRIQUE/ETAT_RESEAU_ELECTRIQUE, init-value=cst_UInt8_init/uint8_init}, provided-interface=AR_GEE_SWC/sri_ETAT_RESEAU_ELECTRIQUE
    provide port pp_MODE_ECO: unqueued-sender-com-spec{data-element=MODE_ECO, init-value=cst_Boolean_init/boolean_init}, provided-interface=sri_MODE_ECO
  internal behavior ib_DETERMINER_ETAT_RESEAU_ELECTRIQUE_TI_TA: component=DETERMINER_ETAT_RESEAU_ELECTRIQUE_TI_TA
    timing event evt_DETERMINER_ETAT_RESEAU_ELECTRIQUE_TI_TA: start-on-event=DETERMINER_ETAT_RESEAU_ELECTRIQUE_TI_TA, period=0.1
    runnable DETERMINER_ETAT_RESEAU_ELECTRIQUE_TI_TA
      5 x data read access:
        dra_INFO_GMP: data-element=rp_INFO_GMP.INFO_GMP
        dra_VITESSE_LONGITUDINALE: data-element=rp_VITESSE_LONGITUDINALE.VITESSE_LONGITUDINALE
        dra_ETAT_RESEAU_ELEC_TI: data-element=rp_ETAT_RESEAU_ELEC_TI.ETAT_RESEAU_ELEC_TI
        dra_ETAT_RESEAU_ELEC_TA: data-element=rp_ETAT_RESEAU_ELEC_TA.ETAT_RESEAU_ELEC_TA
        dra_ON: data-element=rp_CREDIT_TPS_TI_NOMINAL_ON.ON
      data write access dwa_ETAT_RESEAU_ELECTRIQUE: data-element=pp_ETAT_RESEAU_ELECTRIQUE.ETAT_RESEAU_ELECTRIQUE
      data write access dwa_MODE_ECO: data-element=pp_MODE_ECO.MODE_ECO
  4 x sender receiver interface:
    sri_VITESSE_LONGITUDINALE
      data VITESSE_LONGITUDINALE: type=AR_GEE_SWC/UInt16
    sri_CREDIT_TPS_TI_NOMINAL_ON
      data ON: type=AR_GEE_SWC/Boolean
    sri_ETAT_RESEAU_ELECTRIQUE
      data ETAT_RESEAU_ELECTRIQUE: type=AR_GEE_SWC/UInt8
    sri_MODE_ECO
      data MODE_ECO: type=AR_GEE_SWC/Boolean
  swc implementation implem_DETERMINER_ETAT_RESEAU_ELECTRIQUE_TI_TA: programming-language=C, behavior=ib_DETERMINER_ETAT_RESEAU_ELECTRIQUE_TI_TA
    code-descriptors:
      code implem_DETERMINER_ETAT_RESEAU_ELECTRIQUE_TI_TA: type=SRC
        xfile DETERMINER_ETAT_RESEAU_ELECTRIQUE_TI_TA.c: url=Src_C/DETERMINER_ETAT_RESEAU_ELECTRIQUE_TI_TA.c
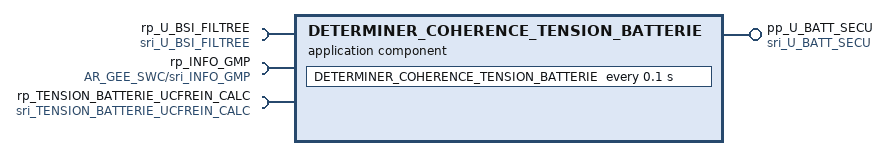
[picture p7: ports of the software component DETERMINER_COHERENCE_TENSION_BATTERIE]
  application software component type DETERMINER_COHERENCE_TENSION_BATTERIE
    require port rp_U_BSI_FILTREE: unqueued-receiver-com-spec{data-element=U_BSI_FILTREE, handle-invalid=KEEP, init-value=double_init, resync-time=0.0}, required-interface=sri_U_BSI_FILTREE
    require port rp_INFO_GMP: unqueued-receiver-com-spec{data-element=sri_INFO_GMP/INFO_GMP, handle-invalid=KEEP, init-value=cst_UInt8_init/uint8_init, resync-time=0.0}, required-interface=AR_GEE_SWC/sri_INFO_GMP
    require port rp_TENSION_BATTERIE_UCFREIN_CALC: unqueued-receiver-com-spec{data-element=TENSION_BATTERIE_UCFREIN_CALC, handle-invalid=KEEP, init-value=double_init, resync-time=0.0}, required-interface=sri_TENSION_BATTERIE_UCFREIN_CALC
    provide port pp_U_BATT_SECU: unqueued-sender-com-spec{data-element=U_BATT_SECU, init-value=double_init}, provided-interface=sri_U_BATT_SECU
  internal behavior ib_DETERMINER_COHERENCE_TENSION_BATTERIE: component=DETERMINER_COHERENCE_TENSION_BATTERIE
    timing event evt_DETERMINER_COHERENCE_TENSION_BATTERIE: start-on-event=DETERMINER_COHERENCE_TENSION_BATTERIE, period=0.1
    runnable DETERMINER_COHERENCE_TENSION_BATTERIE
      data read access dra_U_BSI_FILTREE: data-element=rp_U_BSI_FILTREE.U_BSI_FILTREE
      data read access dra_INFO_GMP: data-element=rp_INFO_GMP.INFO_GMP
      data read access dra_TENSION_BATTERIE_UCFREIN_CALC: data-element=rp_TENSION_BATTERIE_UCFREIN_CALC.TENSION_BATTERIE_UCFREIN_CALC
      data write access dwa_U_BATT_SECU: data-element=pp_U_BATT_SECU.U_BATT_SECU
  sender receiver interface sri_U_BSI_FILTREE
    data U_BSI_FILTREE: type=double_type
  swc implementation implem_DETERMINER_COHERENCE_TENSION_BATTERIE: programming-language=C, behavior=ib_DETERMINER_COHERENCE_TENSION_BATTERIE
    code-descriptors:
      code implem_DETERMINER_COHERENCE_TENSION_BATTERIE: type=SRC
        xfile DETERMINER_COHERENCE_TENSION_BATTERIE.c: url=Src_C/DETERMINER_COHERENCE_TENSION_BATTERIE.c
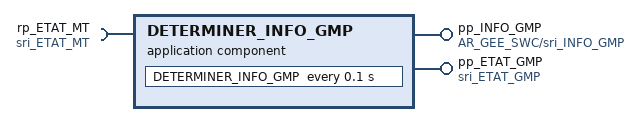
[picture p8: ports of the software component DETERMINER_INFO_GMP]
  application software component type DETERMINER_INFO_GMP
    require port rp_ETAT_MT: unqueued-receiver-com-spec{data-element=ETAT_MT, handle-invalid=KEEP, init-value=cst_UInt8_init/uint8_init, resync-time=0.0}, required-interface=sri_ETAT_MT
    provide port pp_INFO_GMP: unqueued-sender-com-spec{data-element=sri_INFO_GMP/INFO_GMP, init-value=cst_UInt8_init/uint8_init}, provided-interface=AR_GEE_SWC/sri_INFO_GMP
    provide port pp_ETAT_GMP: unqueued-sender-com-spec{data-element=ETAT_GMP, init-value=cst_UInt8_init/uint8_init}, provided-interface=sri_ETAT_GMP
  internal behavior ib_DETERMINER_INFO_GMP: component=DETERMINER_INFO_GMP
    timing event evt_DETERMINER_INFO_GMP: start-on-event=DETERMINER_INFO_GMP, period=0.1
    runnable DETERMINER_INFO_GMP
      data read access dra_ETAT_MT: data-element=rp_ETAT_MT.ETAT_MT
      data write access dwa_INFO_GMP: data-element=pp_INFO_GMP.INFO_GMP
      data write access dwa_ETAT_GMP: data-element=pp_ETAT_GMP.ETAT_GMP
  sender receiver interface sri_ETAT_MT
    data ETAT_MT: type=AR_GEE_SWC/UInt8
  sender receiver interface sri_ETAT_GMP
    data ETAT_GMP: type=AR_GEE_SWC/UInt8
  swc implementation implem_DETERMINER_INFO_GMP: programming-language=C, behavior=ib_DETERMINER_INFO_GMP
    code-descriptors:
      code implem_DETERMINER_INFO_GMP: type=SRC
        xfile DETERMINER_INFO_GMP.c: url=Src_C/DETERMINER_INFO_GMP.c
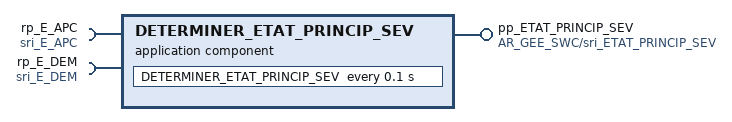
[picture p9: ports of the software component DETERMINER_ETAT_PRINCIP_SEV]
  application software component type DETERMINER_ETAT_PRINCIP_SEV
    require port rp_E_APC: unqueued-receiver-com-spec{data-element=E_APC, handle-invalid=KEEP, init-value=cst_UInt8_init/uint8_init, resync-time=0.0}, required-interface=sri_E_APC
    require port rp_E_DEM: unqueued-receiver-com-spec{data-element=E_DEM, handle-invalid=KEEP, init-value=cst_UInt8_init/uint8_init, resync-time=0.0}, required-interface=sri_E_DEM
    provide port pp_ETAT_PRINCIP_SEV: unqueued-sender-com-spec{data-element=sri_ETAT_PRINCIP_SEV/ETAT_PRINCIP_SEV, init-value=cst_UInt8_init/uint8_init}, provided-interface=AR_GEE_SWC/sri_ETAT_PRINCIP_SEV
  internal behavior ib_DETERMINER_ETAT_PRINCIP_SEV: component=DETERMINER_ETAT_PRINCIP_SEV
    timing event evt_DETERMINER_ETAT_PRINCIP_SEV: start-on-event=DETERMINER_ETAT_PRINCIP_SEV, period=0.1
    runnable DETERMINER_ETAT_PRINCIP_SEV
      data read access dra_E_APC: data-element=rp_E_APC.E_APC
      data read access dra_E_DEM: data-element=rp_E_DEM.E_DEM
      data write access dwa_ETAT_PRINCIP_SEV: data-element=pp_ETAT_PRINCIP_SEV.ETAT_PRINCIP_SEV
  sender receiver interface sri_E_DEM
    data E_DEM: type=AR_GEE_SWC/UInt8
  sender receiver interface sri_ETAT_PRINCIP_SEV
    data ETAT_PRINCIP_SEV: type=AR_GEE_SWC/UInt8
  swc implementation implem_DETERMINER_ETAT_PRINCIP_SEV: programming-language=C, behavior=ib_DETERMINER_ETAT_PRINCIP_SEV
    code-descriptors:
      code implem_DETERMINER_ETAT_PRINCIP_SEV: type=SRC
        xfile DETERMINER_ETAT_PRINCIP_SEV.c: url=Src_C/DETERMINER_ETAT_PRINCIP_SEV.c
  application software component type DETERMINER_CREDIT_TEMPS_TI_NOMINAL
    require port rp_INFO_GMP: unqueued-receiver-com-spec{data-element=sri_INFO_GMP/INFO_GMP, handle-invalid=KEEP, init-value=cst_UInt8_init/uint8_init, resync-time=0.0}, required-interface=AR_GEE_SWC/sri_INFO_GMP
    provide port pp_CREDIT_TPS_TI_NOMINAL: unqueued-sender-com-spec{data-element=Cpt_Time, init-value=cst_UInt32_init/uint32_init}, provided-interface=sri_CREDIT_TPS_TI_NOMINAL
    provide port pp_CREDIT_TPS_TI_NOMINAL_ON: unqueued-sender-com-spec{data-element=ON, init-value=cst_Boolean_init/boolean_init}, provided-interface=sri_CREDIT_TPS_TI_NOMINAL_ON
  internal behavior ib_DETERMINER_CREDIT_TEMPS_TI_NOMINAL: component=DETERMINER_CREDIT_TEMPS_TI_NOMINAL
    timing event evt_DETERMINER_CREDIT_TEMPS_TI_NOMINAL: start-on-event=DETERMINER_CREDIT_TEMPS_TI_NOMINAL, period=0.1
    runnable DETERMINER_CREDIT_TEMPS_TI_NOMINAL
      data read access dra_INFO_GMP: data-element=rp_INFO_GMP.INFO_GMP
      data write access dwa_Cpt_Time: data-element=pp_CREDIT_TPS_TI_NOMINAL.Cpt_Time
      data write access dwa_ON: data-element=pp_CREDIT_TPS_TI_NOMINAL_ON.ON
  sender receiver interface sri_CREDIT_TPS_TI_NOMINAL
    data Cpt_Time: type=AR_GEE_SWC/UInt32
  constant specification cst_UInt32_init
    value:
      integer literal uint32_init: type=AR_GEE_SWC/UInt32, value=0
  swc implementation implem_DETERMINER_CREDIT_TEMPS_TI_NOMINAL: programming-language=C, behavior=ib_DETERMINER_CREDIT_TEMPS_TI_NOMINAL
    code-descriptors:
      code implem_DETERMINER_CREDIT_TEMPS_TI_NOMINAL: type=SRC
        xfile DETERMINER_CREDIT_TEMPS_TI_NOMINAL.c: url=Src_C/DETERMINER_CREDIT_TEMPS_TI_NOMINAL.c
  application software component type COMMANDER_ALIM_APC
    require port rp_ETAT_PRINCIP_SEV: unqueued-receiver-com-spec{data-element=sri_ETAT_PRINCIP_SEV/ETAT_PRINCIP_SEV, handle-invalid=KEEP, init-value=cst_UInt8_init/uint8_init, resync-time=0.0}, required-interface=AR_GEE_SWC/sri_ETAT_PRINCIP_SEV
    provide port pp_CDE_APC: unqueued-sender-com-spec{data-element=sri_CDE_APC/CDE_APC, init-value=cst_Boolean_init/boolean_init}, provided-interface=AR_GEE_SWC/sri_CDE_APC
  internal behavior ib_COMMANDER_ALIM_APC: component=COMMANDER_ALIM_APC
    timing event evt_COMMANDER_ALIM_APC: start-on-event=COMMANDER_ALIM_APC, period=0.1
    runnable COMMANDER_ALIM_APC
      data read access dra_ETAT_PRINCIP_SEV: data-element=rp_ETAT_PRINCIP_SEV.ETAT_PRINCIP_SEV
      data write access dwa_CDE_APC: data-element=pp_CDE_APC.CDE_APC
  sender receiver interface sri_CDE_APC
    data CDE_APC: type=AR_GEE_SWC/Boolean
  swc implementation implem_COMMANDER_ALIM_APC: programming-language=C, behavior=ib_COMMANDER_ALIM_APC
    code-descriptors:
      code implem_COMMANDER_ALIM_APC: type=SRC
        xfile COMMANDER_ALIM_APC.c: url=Src_C/COMMANDER_ALIM_APC.c
  application software component type COMMANDER_ALIM_ACC
    require port rp_ETAT_PRINCIP_SEV: unqueued-receiver-com-spec{data-element=sri_ETAT_PRINCIP_SEV/ETAT_PRINCIP_SEV, handle-invalid=KEEP, init-value=cst_UInt8_init/uint8_init, resync-time=0.0}, required-interface=AR_GEE_SWC/sri_ETAT_PRINCIP_SEV
    require port rp_ETAT_RESEAU_ELECTRIQUE: unqueued-receiver-com-spec{data-element=sri_ETAT_RESEAU_ELECTRIQUE/ETAT_RESEAU_ELECTRIQUE, handle-invalid=KEEP, init-value=cst_UInt8_init/uint8_init, resync-time=0.0}, required-interface=AR_GEE_SWC/sri_ETAT_RESEAU_ELECTRIQUE
    provide port pp_CDE_ACC: unqueued-sender-com-spec{data-element=CDE_ACC, init-value=cst_Boolean_init/boolean_init}, provided-interface=sri_CDE_ACC
  internal behavior ib_COMMANDER_ALIM_ACC: component=COMMANDER_ALIM_ACC
    timing event evt_COMMANDER_ALIM_ACC: start-on-event=COMMANDER_ALIM_ACC, period=0.1
    runnable COMMANDER_ALIM_ACC
      data read access dra_ETAT_PRINCIP_SEV: data-element=rp_ETAT_PRINCIP_SEV.ETAT_PRINCIP_SEV
      data read access dra_ETAT_RESEAU_ELECTRIQUE: data-element=rp_ETAT_RESEAU_ELECTRIQUE.ETAT_RESEAU_ELECTRIQUE
      data write access dwa_CDE_ACC: data-element=pp_CDE_ACC.CDE_ACC
  sender receiver interface sri_CDE_ACC
    data CDE_ACC: type=AR_GEE_SWC/Boolean
  swc implementation implem_COMMANDER_ALIM_ACC: programming-language=C, behavior=ib_COMMANDER_ALIM_ACC
    code-descriptors:
      code implem_COMMANDER_ALIM_ACC: type=SRC
        xfile COMMANDER_ALIM_ACC.c: url=Src_C/COMMANDER_ALIM_ACC.c
  application software component type DETERMINER_TENSION_BATTERIE_PAR_TENSION_BSI
    require port rp_U_BAT: unqueued-receiver-com-spec{data-element=U_BAT, handle-invalid=KEEP, init-value=cst_UInt16_init/uint16_init, resync-time=0.0}, required-interface=sri_U_BAT
    provide port pp_U_BSI_FILTREE: unqueued-sender-com-spec{data-element=U_BSI_FILTREE, init-value=double_init}, provided-interface=sri_U_BSI_FILTREE
  internal behavior ib_DETERMINER_TENSION_BATTERIE_PAR_TENSION_BSI: component=DETERMINER_TENSION_BATTERIE_PAR_TENSION_BSI
    timing event evt_DETERMINER_TENSION_BATTERIE_PAR_TENSION_BSI: start-on-event=DETERMINER_TENSION_BATTERIE_PAR_TENSION_BSI, period=0.1
    runnable DETERMINER_TENSION_BATTERIE_PAR_TENSION_BSI
      data read access dra_U_BAT: data-element=rp_U_BAT.U_BAT
      data write access dwa_U_BSI_FILTREE: data-element=pp_U_BSI_FILTREE.U_BSI_FILTREE
  swc implementation implem_DETERMINER_TENSION_BATTERIE_PAR_TENSION_BSI: programming-language=C, behavior=ib_DETERMINER_TENSION_BATTERIE_PAR_TENSION_BSI
    code-descriptors:
      code implem_DETERMINER_TENSION_BATTERIE_PAR_TENSION_BSI: type=SRC
        xfile DETERMINER_TENSION_BATTERIE_PAR_TENSION_BSI.c: url=Src_C/DETERMINER_TENSION_BATTERIE_PAR_TENSION_BSI.c
package /AR_GAV_SWC
  application software component type SECU_ENF
    5 x require port:
      rp_DMD_PUSH_SECU_ENFANT: unqueued-receiver-com-spec{data-element=DMD_PUSH_SECU_ENFANT, handle-invalid=KEEP, init-value=cst_Boolean_init/boolean_init, resync-time=0.0}, required-interface=sri_DMD_PUSH_SECU_ENFANT
      rp_DMD_CHOC_DEVERROUILLAGE: unqueued-receiver-com-spec{data-element=DMD_CHOC_DEVERROUILLAGE, handle-invalid=KEEP, init-value=cst_Boolean_init/boolean_init, resync-time=0.0}, required-interface=sri_DMD_CHOC_DEVERROUILLAGE
      rp_ACTION_SERRURES_EN_COURS: unqueued-receiver-com-spec{data-element=sri_ACTION_SERRURES_EN_COURS/Y, handle-invalid=KEEP, init-value=cst_Boolean_init/boolean_init, resync-time=0.0}, required-interface=sri_ACTION_SERRURES_EN_COURS
      rp_ETAT_CONDA: unqueued-receiver-com-spec{data-element=sri_ETAT_CONDA/ETAT_CONDA, handle-invalid=KEEP, init-value=cst_UInt8_init/uint8_init, resync-time=0.0}, required-interface=AR_GAV_SWC/sri_ETAT_CONDA
      rp_ETAT_PRINCIP_SEV: unqueued-receiver-com-spec{data-element=sri_ETAT_PRINCIP_SEV/ETAT_PRINCIP_SEV, handle-invalid=KEEP, init-value=cst_UInt8_init/uint8_init, resync-time=0.0}, required-interface=AR_GAV_SWC/sri_ETAT_PRINCIP_SEV
    4 x provide port:
      pp_DMD_ACTIVE_SECU_ENFANT: unqueued-sender-com-spec{data-element=DMD_ACTIVE_SECU_ENFANT, init-value=cst_Boolean_init/boolean_init}, provided-interface=sri_DMD_ACTIVE_SECU_ENFANT
      pp_DMD_DESACTIVE_SECU_ENFANT: unqueued-sender-com-spec{data-element=DMD_DESACTIVE_SECU_ENFANT, init-value=cst_Boolean_init/boolean_init}, provided-interface=sri_DMD_DESACTIVE_SECU_ENFANT
      pp_ETAT_SECURITE_ENFANT: unqueued-sender-com-spec{data-element=sri_ETAT_SECURITE_ENFANT/Y, init-value=cst_Boolean_init/boolean_init}, provided-interface=sri_ETAT_SECURITE_ENFANT
      pp_CMD_ALLUME_LED_SECU_ENFANT: unqueued-sender-com-spec{data-element=CMD_ALLUME_LED_SECU_ENFANT, init-value=cst_Boolean_init/boolean_init}, provided-interface=sri_CMD_ALLUME_LED_SECU_ENFANT
  composition type MDL_GAV
    7 x require port:
      rp_ETAT_PRINCIP_SEV: unqueued-receiver-com-spec{data-element=sri_ETAT_PRINCIP_SEV/ETAT_PRINCIP_SEV, handle-invalid=KEEP, init-value=cst_UInt8_init/uint8_init, resync-time=0.0}, required-interface=AR_GAV_SWC/sri_ETAT_PRINCIP_SEV
      rp_INFO_CAV_AVG: unqueued-receiver-com-spec{data-element=INFO_CAV_AVG, handle-invalid=KEEP, init-value=cst_Boolean_init/boolean_init, resync-time=0.0}, required-interface=sri_INFO_CAV_AVG
      rp_INFO_CAV_AVD: unqueued-receiver-com-spec{data-element=INFO_CAV_AVD, handle-invalid=KEEP, init-value=cst_Boolean_init/boolean_init, resync-time=0.0}, required-interface=sri_INFO_CAV_AVD
      rp_INFO_CPO_ARD: unqueued-receiver-com-spec{data-element=INFO_CPO_ARD, handle-invalid=KEEP, init-value=cst_Boolean_init/boolean_init, resync-time=0.0}, required-interface=sri_INFO_CPO_ARD
      rp_INFO_CPO_ARG: unqueued-receiver-com-spec{data-element=INFO_CPO_ARG, handle-invalid=KEEP, init-value=cst_Boolean_init/boolean_init, resync-time=0.0}, required-interface=sri_INFO_CPO_ARG
      rp_INFO_CPO_AVD: unqueued-receiver-com-spec{data-element=INFO_CPO_AVD, handle-invalid=KEEP, init-value=cst_Boolean_init/boolean_init, resync-time=0.0}, required-interface=sri_INFO_CPO_AVD
      rp_INFO_CPO_AVG: unqueued-receiver-com-spec{data-element=INFO_CPO_AVG, handle-invalid=KEEP, init-value=cst_Boolean_init/boolean_init, resync-time=0.0}, required-interface=sri_INFO_CPO_AVG
    7 x provide port:
      pp_ETAT_CPO_PASS: unqueued-sender-com-spec{data-element=ETAT_CPO_PASS, init-value=cst_Boolean_init/boolean_init}, provided-interface=sri_ETAT_CPO_PASS
      pp_ETAT_CPO_COND: unqueued-sender-com-spec{data-element=sri_ETAT_CPO_COND/ETAT_CPO_COND, init-value=cst_Boolean_init/boolean_init}, provided-interface=AR_GAV_SWC/sri_ETAT_CPO_COND
      pp_ETAT_CPO_ARG: unqueued-sender-com-spec{data-element=ETAT_CPO_ARG, init-value=cst_Boolean_init/boolean_init}, provided-interface=sri_ETAT_CPO_ARG
      pp_ETAT_CPO_ARD: unqueued-sender-com-spec{data-element=ETAT_CPO_ARD, init-value=cst_Boolean_init/boolean_init}, provided-interface=sri_ETAT_CPO_ARD
      pp_P_LED_GAV_ETAT_VERR_CENT: unqueued-sender-com-spec{data-element=P_LED_GAV_ETAT_VERR_CENT, init-value=cst_Boolean_init/boolean_init}, provided-interface=sri_P_LED_GAV_ETAT_VERR_CENT
      pp_P_LED_GAV_ETAT_VERR_ZONE_CH: unqueued-sender-com-spec{data-element=P_LED_GAV_ETAT_VERR_ZONE_CH, init-value=cst_Boolean_init/boolean_init}, provided-interface=sri_P_LED_GAV_ETAT_VERR_ZONE_CH
      pp_P_LED_GAV_ETAT_SECU_ENF: unqueued-sender-com-spec{data-element=P_LED_GAV_ETAT_SECU_ENF, init-value=cst_Boolean_init/boolean_init}, provided-interface=sri_P_LED_GAV_ETAT_SECU_ENF
    require port rp_CHOC_DEVERROUILLAGE: unqueued-receiver-com-spec{data-element=CHOC_DEVERROUILLAGE, handle-invalid=KEEP, init-value=cst_Boolean_init/boolean_init, resync-time=0.0}, required-interface=sri_CHOC_DEVERROUILLAGE
    5 x provide port:
      pp_DECONDA_DESACTIVE_ALARME: unqueued-sender-com-spec{data-element=DECONDA_DESACTIVE_ALARME, init-value=cst_Boolean_init/boolean_init}, provided-interface=sri_DECONDA_DESACTIVE_ALARME
      pp_CONDA_ACTIVE_ALARME: unqueued-sender-com-spec{data-element=CONDA_ACTIVE_ALARME, init-value=cst_Boolean_init/boolean_init}, provided-interface=sri_CONDA_ACTIVE_ALARME
      pp_REBOND_ACTIVE_ALARME: unqueued-sender-com-spec{data-element=REBOND_ACTIVE_ALARME, init-value=cst_Boolean_init/boolean_init}, provided-interface=sri_REBOND_ACTIVE_ALARME
      pp_ETAT_CONDA: unqueued-sender-com-spec{data-element=sri_ETAT_CONDA/ETAT_CONDA, init-value=cst_UInt8_init/uint8_init}, provided-interface=AR_GAV_SWC/sri_ETAT_CONDA
      pp_TYPE_CONDA: unqueued-sender-com-spec{data-element=sri_TYPE_CONDA/TYPE_CONDA, init-value=cst_UInt8_init/uint8_init}, provided-interface=AR_GAV_SWC/sri_TYPE_CONDA
    require port rp_VITESSE_LONGITUDINALE: unqueued-receiver-com-spec{data-element=sri_VITESSE_LONGITUDINALE/VITESSE_LONGITUDINALE, handle-invalid=KEEP, init-value=cst_UInt16_init/uint16_init, resync-time=0.0}, required-interface=AR_GAV_SWC/sri_VITESSE_LONGITUDINALE
    require port rp_UTILISATEUR_DS_HAB: unqueued-receiver-com-spec{data-element=UTILISATEUR_DS_HAB, handle-invalid=KEEP, init-value=cst_Boolean_init/boolean_init, resync-time=0.0}, required-interface=sri_UTILISATEUR_DS_HAB
    require port rp_INFO_GMP: unqueued-receiver-com-spec{data-element=sri_INFO_GMP/INFO_GMP, handle-invalid=KEEP, init-value=cst_UInt8_init/uint8_init, resync-time=0.0}, required-interface=AR_GAV_SWC/sri_INFO_GMP
    7 x provide port:
      pp_ACTION_SERRURES_EN_COURS: unqueued-sender-com-spec{data-element=sri_ACTION_SERRURES_EN_COURS/Y, init-value=cst_Boolean_init/boolean_init}, provided-interface=sri_ACTION_SERRURES_EN_COURS
      pp_CMD_SERR_MOT_COMMUN: unqueued-sender-com-spec{data-element=CMD_SERR_MOT_COMMUN, init-value=cst_Boolean_init/boolean_init}, provided-interface=sri_CMD_SERR_MOT_COMMUN
      pp_CMD_SERR_MOT_EXT: unqueued-sender-com-spec{data-element=CMD_SERR_MOT_EXT, init-value=cst_Boolean_init/boolean_init}, provided-interface=sri_CMD_SERR_MOT_EXT
      pp_CMD_SERR_MOT_EXT_SELECT: unqueued-sender-com-spec{data-element=CMD_SERR_MOT_EXT_SELECT, init-value=cst_Boolean_init/boolean_init}, provided-interface=sri_CMD_SERR_MOT_EXT_SELECT
      pp_CMD_SERR_MOT_INT_AR: unqueued-sender-com-spec{data-element=CMD_SERR_MOT_INT_AR, init-value=cst_Boolean_init/boolean_init}, provided-interface=sri_CMD_SERR_MOT_INT_AR
      pp_CMD_SERR_MOT_INT_AV: unqueued-sender-com-spec{data-element=CMD_SERR_MOT_INT_AV, init-value=cst_Boolean_init/boolean_init}, provided-interface=sri_CMD_SERR_MOT_INT_AV
      pp_PROTECTION_THERMIQUE: unqueued-sender-com-spec{data-element=PROTECTION_THERMIQUE, init-value=cst_Boolean_init/boolean_init}, provided-interface=sri_PROTECTION_THERMIQUE
    require port rp_NUM_BOUTON_APPUI_TELECMD: unqueued-receiver-com-spec{data-element=NUM_BOUTON_APPUI_TELECMD, handle-invalid=KEEP, init-value=cst_UInt8_init/uint8_init, resync-time=0.0}, required-interface=sri_NUM_BOUTON_APPUI_TELECMD
    require port rp_TYPE_APPUI_BOUTON_TELECMD: unqueued-receiver-com-spec{data-element=TYPE_APPUI_BOUTON_TELECMD, handle-invalid=KEEP, init-value=cst_Boolean_init/boolean_init, resync-time=0.0}, required-interface=sri_TYPE_APPUI_BOUTON_TELECMD
    require port rp_NUM_IDENTIFIANT_HF_TELECMD: unqueued-receiver-com-spec{data-element=NUM_IDENTIFIANT_HF_TELECMD, handle-invalid=KEEP, init-value=cst_UInt32_init/uint32_init, resync-time=0.0}, required-interface=sri_NUM_IDENTIFIANT_HF_TELECMD
    provide port pp_AUTOR_FONCT_TELECMD: unqueued-sender-com-spec{data-element=AUTOR_FONCT_TELECMD, init-value=cst_Boolean_init/boolean_init}, provided-interface=sri_AUTOR_FONCT_TELECMD
    provide port pp_DMD_LOCAL_TELECMD: unqueued-sender-com-spec{data-element=sri_DMD_LOCAL_TELECMD/DMD_LOCAL_TELECMD, init-value=cst_Boolean_init/boolean_init}, provided-interface=AR_GAV_SWC/sri_DMD_LOCAL_TELECMD
    require port rp_DMDP_GAV_VERR_CENTRALISE: unqueued-receiver-com-spec{data-element=DMDP_GAV_VERR_CENTRALISE, handle-invalid=KEEP, init-value=cst_Boolean_init/boolean_init, resync-time=0.0}, required-interface=sri_DMDP_GAV_VERR_CENTRALISE
    require port rp_DMDP_GAV_SECU_ENFANT: unqueued-receiver-com-spec{data-element=DMDP_GAV_SECU_ENFANT, handle-invalid=KEEP, init-value=cst_Boolean_init/boolean_init, resync-time=0.0}, required-interface=sri_DMDP_GAV_SECU_ENFANT
    8 x component:
      SECU_ENF: type=SECU_ENF
      INFO_SER: type=INFO_SER
      LED: type=LED
      AUTO_VER_DEV: type=AUTO_VER_DEV
      VER_DEV_SPE: type=VER_DEV_SPE
      PILOTER_SER: type=PILOTER_SER
      TELECMD: type=TELECMD
      PUSH: type=PUSH
    connect SECU_ENF.pp_CMD_ALLUME_LED_SECU_ENFANT -> LED.rp_CMD_ALLUME_LED_SECU_ENFANT
    connect SECU_ENF.pp_DMD_ACTIVE_SECU_ENFANT -> AUTO_VER_DEV.rp_DMD_ACTIVE_SECU_ENFANT
    connect SECU_ENF.pp_DMD_DESACTIVE_SECU_ENFANT -> AUTO_VER_DEV.rp_DMD_DESACTIVE_SECU_ENFANT
    connect AUTO_VER_DEV.pp_ETAT_CONDA -> SECU_ENF.rp_ETAT_CONDA
    connect VER_DEV_SPE.pp_DMD_CHOC_DEVERROUILLAGE -> SECU_ENF.rp_DMD_CHOC_DEVERROUILLAGE
    connect SECU_ENF.pp_ETAT_SECURITE_ENFANT -> PILOTER_SER.rp_ETAT_SECURITE_ENFANT
    connect PILOTER_SER.pp_ACTION_SERRURES_EN_COURS -> SECU_ENF.rp_ACTION_SERRURES_EN_COURS
    connect PUSH.pp_DMD_PUSH_SECU_ENFANT -> SECU_ENF.rp_DMD_PUSH_SECU_ENFANT
    connect INFO_SER.pp_ETAT_CPO_PASS -> AUTO_VER_DEV.rp_ETAT_CPO_PASS
    connect INFO_SER.pp_ETAT_CPO_COND -> AUTO_VER_DEV.rp_ETAT_CPO_COND
    connect INFO_SER.pp_ETAT_CPO_ARG -> AUTO_VER_DEV.rp_ETAT_CPO_ARG
    connect INFO_SER.pp_ETAT_CPO_ARD -> AUTO_VER_DEV.rp_ETAT_CPO_ARD
    connect INFO_SER.pp_DMD_DECONDA_VERROU_COND -> AUTO_VER_DEV.rp_DMD_DECONDA_VERROU_COND
    connect INFO_SER.pp_DMD_OVERRIDE_COND -> AUTO_VER_DEV.rp_DMD_OVERRIDE_COND
    connect INFO_SER.pp_DMD_OVERRIDE_PASS -> AUTO_VER_DEV.rp_DMD_OVERRIDE_PASS
    connect INFO_SER.pp_DMD_OVERRIDE_ARG -> AUTO_VER_DEV.rp_DMD_OVERRIDE_ARG
    connect INFO_SER.pp_DMD_OVERRIDE_ARD -> AUTO_VER_DEV.rp_DMD_OVERRIDE_ARD
    connect INFO_SER.pp_DMD_CONDA_VERROU_COND -> AUTO_VER_DEV.rp_DMD_CONDA_VERROU_COND
    connect INFO_SER.pp_DMD_DECONDA_VERROU_COND -> VER_DEV_SPE.rp_DMD_DECONDA_VERROU_COND
    connect INFO_SER.pp_ETAT_CPO_PASS -> VER_DEV_SPE.rp_ETAT_CPO_PASS
    connect INFO_SER.pp_ETAT_CPO_COND -> VER_DEV_SPE.rp_ETAT_CPO_COND
    connect INFO_SER.pp_ETAT_CPO_ARG -> VER_DEV_SPE.rp_ETAT_CPO_ARG
    connect INFO_SER.pp_ETAT_CPO_ARD -> VER_DEV_SPE.rp_ETAT_CPO_ARD
    connect AUTO_VER_DEV.pp_ETAT_CONDA -> LED.rp_ETAT_CONDA
    connect VER_DEV_SPE.pp_DMD_CHOC_DEVERROUILLAGE -> AUTO_VER_DEV.rp_DMD_CHOC_DEVERROUILLAGE
    connect VER_DEV_SPE.pp_DMD_CONDA_AUTO_LATENCE -> AUTO_VER_DEV.rp_DMD_CONDA_AUTO_LATENCE
    connect VER_DEV_SPE.pp_DMD_CONDA_AUTO_ROULAGE -> AUTO_VER_DEV.rp_DMD_CONDA_AUTO_ROULAGE
    connect VER_DEV_SPE.pp_DMD_CONDA_COFFRE_ROULAGE -> AUTO_VER_DEV.rp_DMD_CONDA_COFFRE_ROULAGE
    connect VER_DEV_SPE.pp_DMD_DECONDA_AUTO_ROULAGE -> AUTO_VER_DEV.rp_DMD_DECONDA_AUTO_ROULAGE
    connect VER_DEV_SPE.pp_DMD_DECONDA_INVIOLABILITE -> AUTO_VER_DEV.rp_DMD_DECONDA_INVIOLABILITE
    connect VER_DEV_SPE.pp_DMD_DECONDA_MENU_PERSO -> AUTO_VER_DEV.rp_DMD_DECONDA_MENU_PERSO
    connect VER_DEV_SPE.pp_DMD_DESUPERCONDA_AUTHENT -> AUTO_VER_DEV.rp_DMD_DESUPERCONDA_AUTHENT
    connect AUTO_VER_DEV.pp_ETAT_CONDA -> VER_DEV_SPE.rp_ETAT_CONDA
    connect AUTO_VER_DEV.pp_ETAT_CONDA_AUTO_ROULAGE -> VER_DEV_SPE.rp_ETAT_CONDA_AUTO_ROULAGE
    connect AUTO_VER_DEV.pp_ETAT_CONDA -> PILOTER_SER.rp_ETAT_CONDA
    connect AUTO_VER_DEV.pp_CMD_ACTIVE_SECU_ENFANT -> PILOTER_SER.rp_CMD_ACTIVE_SECU_ENFANT
    connect AUTO_VER_DEV.pp_CMD_CONDA_PORTE_COND -> PILOTER_SER.rp_CMD_CONDA_PORTE_COND
    connect AUTO_VER_DEV.pp_CMD_CONDA_PORTES -> PILOTER_SER.rp_CMD_CONDA_PORTES
    connect AUTO_VER_DEV.pp_CMD_DECONDA_PORTE_COND -> PILOTER_SER.rp_CMD_DECONDA_PORTE_COND
    connect AUTO_VER_DEV.pp_CMD_DECONDA_PORTES -> PILOTER_SER.rp_CMD_DECONDA_PORTES
    connect AUTO_VER_DEV.pp_CMD_DECONDA_PORTES_CHOC -> PILOTER_SER.rp_CMD_DECONDA_PORTES_CHOC
    connect AUTO_VER_DEV.pp_CMD_DESACTIVE_SECU_ENFANT -> PILOTER_SER.rp_CMD_DESACTIVE_SECU_ENFANT
    connect AUTO_VER_DEV.pp_CMD_DESUPERCONDA_PORTES -> PILOTER_SER.rp_CMD_DESUPERCONDA_PORTES
    connect AUTO_VER_DEV.pp_CMD_REBOND_PORTE_COND -> PILOTER_SER.rp_CMD_REBOND_PORTE_COND
    connect AUTO_VER_DEV.pp_CMD_REBOND_PORTES -> PILOTER_SER.rp_CMD_REBOND_PORTES
    connect AUTO_VER_DEV.pp_CMD_SUPERCONDA_PORTES -> PILOTER_SER.rp_CMD_SUPERCONDA_PORTES
    connect PILOTER_SER.pp_ACTION_SERRURES_EN_COURS -> AUTO_VER_DEV.rp_ACTION_SERRURES_EN_COURS
    connect PILOTER_SER.pp_PROTECTION_THERMIQUE -> AUTO_VER_DEV.rp_PROTECTION_THERMIQUE
    connect TELECMD.pp_DMD_DECONDA_TELECMD -> AUTO_VER_DEV.rp_DMD_DECONDA_TELECMD
    connect TELECMD.pp_DMD_CONDA_TELECMD -> AUTO_VER_DEV.rp_DMD_CONDA_TELECMD
    connect TELECMD.pp_DMD_SUPERCONDA_TELECMD -> AUTO_VER_DEV.rp_DMD_SUPERCONDA_TELECMD
    connect AUTO_VER_DEV.pp_ETAT_CONDA -> TELECMD.rp_ETAT_CONDA
    connect PUSH.pp_DMD_PUSH_CONDA_APPUI_COURT -> AUTO_VER_DEV.rp_DMD_PUSH_CONDA_APPUI_COURT
    connect PUSH.pp_DMD_PUSH_CONDA_APPUI_LONG -> AUTO_VER_DEV.rp_DMD_PUSH_CONDA_APPUI_LONG
    connect TELECMD.pp_DMD_DECONDA_TELECMD -> VER_DEV_SPE.rp_DMD_DECONDA_TELECMD
    delegate SECU_ENF.rp_ETAT_PRINCIP_SEV <-> outer port MDL_GAV/rp_ETAT_PRINCIP_SEV
    delegate INFO_SER.rp_INFO_CAV_AVG <-> outer port MDL_GAV/rp_INFO_CAV_AVG
    delegate INFO_SER.rp_INFO_CAV_AVD <-> outer port MDL_GAV/rp_INFO_CAV_AVD
    delegate INFO_SER.rp_INFO_CPO_ARD <-> outer port MDL_GAV/rp_INFO_CPO_ARD
    delegate INFO_SER.rp_INFO_CPO_ARG <-> outer port MDL_GAV/rp_INFO_CPO_ARG
    delegate INFO_SER.rp_INFO_CPO_AVD <-> outer port MDL_GAV/rp_INFO_CPO_AVD
    delegate INFO_SER.rp_INFO_CPO_AVG <-> outer port MDL_GAV/rp_INFO_CPO_AVG
    delegate INFO_SER.pp_ETAT_CPO_PASS <-> outer port MDL_GAV/pp_ETAT_CPO_PASS
    delegate INFO_SER.pp_ETAT_CPO_COND <-> outer port MDL_GAV/pp_ETAT_CPO_COND
    delegate INFO_SER.pp_ETAT_CPO_ARG <-> outer port MDL_GAV/pp_ETAT_CPO_ARG
    delegate INFO_SER.pp_ETAT_CPO_ARD <-> outer port MDL_GAV/pp_ETAT_CPO_ARD
    delegate LED.rp_ETAT_PRINCIP_SEV <-> outer port MDL_GAV/rp_ETAT_PRINCIP_SEV
    delegate LED.pp_P_LED_GAV_ETAT_VERR_CENT <-> outer port MDL_GAV/pp_P_LED_GAV_ETAT_VERR_CENT
    delegate LED.pp_P_LED_GAV_ETAT_VERR_ZONE_CH <-> outer port MDL_GAV/pp_P_LED_GAV_ETAT_VERR_ZONE_CH
    delegate LED.pp_P_LED_GAV_ETAT_SECU_ENF <-> outer port MDL_GAV/pp_P_LED_GAV_ETAT_SECU_ENF
    delegate AUTO_VER_DEV.rp_ETAT_PRINCIP_SEV <-> outer port MDL_GAV/rp_ETAT_PRINCIP_SEV
    delegate AUTO_VER_DEV.rp_CHOC_DEVERROUILLAGE <-> outer port MDL_GAV/rp_CHOC_DEVERROUILLAGE
    delegate AUTO_VER_DEV.pp_DECONDA_DESACTIVE_ALARME <-> outer port MDL_GAV/pp_DECONDA_DESACTIVE_ALARME
    delegate AUTO_VER_DEV.pp_CONDA_ACTIVE_ALARME <-> outer port MDL_GAV/pp_CONDA_ACTIVE_ALARME
    delegate AUTO_VER_DEV.pp_REBOND_ACTIVE_ALARME <-> outer port MDL_GAV/pp_REBOND_ACTIVE_ALARME
    delegate AUTO_VER_DEV.pp_ETAT_CONDA <-> outer port MDL_GAV/pp_ETAT_CONDA
    delegate AUTO_VER_DEV.pp_TYPE_CONDA <-> outer port MDL_GAV/pp_TYPE_CONDA
    delegate VER_DEV_SPE.rp_ETAT_PRINCIP_SEV <-> outer port MDL_GAV/rp_ETAT_PRINCIP_SEV
    delegate VER_DEV_SPE.rp_VITESSE_LONGITUDINALE <-> outer port MDL_GAV/rp_VITESSE_LONGITUDINALE
    delegate VER_DEV_SPE.rp_UTILISATEUR_DS_HAB <-> outer port MDL_GAV/rp_UTILISATEUR_DS_HAB
    delegate VER_DEV_SPE.rp_CHOC_DEVERROUILLAGE <-> outer port MDL_GAV/rp_CHOC_DEVERROUILLAGE
    delegate VER_DEV_SPE.rp_INFO_GMP <-> outer port MDL_GAV/rp_INFO_GMP
    delegate PILOTER_SER.pp_ACTION_SERRURES_EN_COURS <-> outer port MDL_GAV/pp_ACTION_SERRURES_EN_COURS
    delegate PILOTER_SER.pp_CMD_SERR_MOT_COMMUN <-> outer port MDL_GAV/pp_CMD_SERR_MOT_COMMUN
    delegate PILOTER_SER.pp_CMD_SERR_MOT_EXT <-> outer port MDL_GAV/pp_CMD_SERR_MOT_EXT
    delegate PILOTER_SER.pp_CMD_SERR_MOT_EXT_SELECT <-> outer port MDL_GAV/pp_CMD_SERR_MOT_EXT_SELECT
    delegate PILOTER_SER.pp_CMD_SERR_MOT_INT_AR <-> outer port MDL_GAV/pp_CMD_SERR_MOT_INT_AR
    delegate PILOTER_SER.pp_CMD_SERR_MOT_INT_AV <-> outer port MDL_GAV/pp_CMD_SERR_MOT_INT_AV
    delegate PILOTER_SER.pp_PROTECTION_THERMIQUE <-> outer port MDL_GAV/pp_PROTECTION_THERMIQUE
    delegate TELECMD.rp_NUM_BOUTON_APPUI_TELECMD <-> outer port MDL_GAV/rp_NUM_BOUTON_APPUI_TELECMD
    delegate TELECMD.rp_TYPE_APPUI_BOUTON_TELECMD <-> outer port MDL_GAV/rp_TYPE_APPUI_BOUTON_TELECMD
    delegate TELECMD.rp_NUM_IDENTIFIANT_HF_TELECMD <-> outer port MDL_GAV/rp_NUM_IDENTIFIANT_HF_TELECMD
    delegate TELECMD.rp_ETAT_PRINCIP_SEV <-> outer port MDL_GAV/rp_ETAT_PRINCIP_SEV
    delegate TELECMD.rp_UTILISATEUR_DS_HAB <-> outer port MDL_GAV/rp_UTILISATEUR_DS_HAB
    delegate TELECMD.pp_AUTOR_FONCT_TELECMD <-> outer port MDL_GAV/pp_AUTOR_FONCT_TELECMD
    delegate TELECMD.pp_DMD_LOCAL_TELECMD <-> outer port MDL_GAV/pp_DMD_LOCAL_TELECMD
    delegate PUSH.rp_DMDP_GAV_VERR_CENTRALISE <-> outer port MDL_GAV/rp_DMDP_GAV_VERR_CENTRALISE
    delegate PUSH.rp_DMDP_GAV_SECU_ENFANT <-> outer port MDL_GAV/rp_DMDP_GAV_SECU_ENFANT
    delegate PUSH.rp_ETAT_PRINCIP_SEV <-> outer port MDL_GAV/rp_ETAT_PRINCIP_SEV
  composition type GAV
    4 x provide port:
      pp_DMD_LOCAL_TELECMD: unqueued-sender-com-spec{data-element=sri_DMD_LOCAL_TELECMD/DMD_LOCAL_TELECMD, init-value=cst_Boolean_init/boolean_init}, provided-interface=AR_GAV_SWC/sri_DMD_LOCAL_TELECMD
      pp_ETAT_CPO_COND: unqueued-sender-com-spec{data-element=sri_ETAT_CPO_COND/ETAT_CPO_COND, init-value=cst_Boolean_init/boolean_init}, provided-interface=AR_GAV_SWC/sri_ETAT_CPO_COND
      pp_ETAT_CONDA: unqueued-sender-com-spec{data-element=sri_ETAT_CONDA/ETAT_CONDA, init-value=cst_UInt8_init/uint8_init}, provided-interface=AR_GAV_SWC/sri_ETAT_CONDA
      pp_TYPE_CONDA: unqueued-sender-com-spec{data-element=sri_TYPE_CONDA/TYPE_CONDA, init-value=cst_UInt8_init/uint8_init}, provided-interface=AR_GAV_SWC/sri_TYPE_CONDA
    7 x require port:
      rp_ETAT_PRINCIP_SEV: unqueued-receiver-com-spec{data-element=sri_ETAT_PRINCIP_SEV/ETAT_PRINCIP_SEV, handle-invalid=KEEP, init-value=cst_UInt8_init/uint8_init, resync-time=0.0}, required-interface=AR_GAV_SWC/sri_ETAT_PRINCIP_SEV
      rp_INFO_CAV_AVG: unqueued-receiver-com-spec{data-element=INFO_CAV_AVG, handle-invalid=KEEP, init-value=cst_Boolean_init/boolean_init, resync-time=0.0}, required-interface=sri_INFO_CAV_AVG
      rp_INFO_CAV_AVD: unqueued-receiver-com-spec{data-element=INFO_CAV_AVD, handle-invalid=KEEP, init-value=cst_Boolean_init/boolean_init, resync-time=0.0}, required-interface=sri_INFO_CAV_AVD
      rp_INFO_CPO_ARD: unqueued-receiver-com-spec{data-element=INFO_CPO_ARD, handle-invalid=KEEP, init-value=cst_Boolean_init/boolean_init, resync-time=0.0}, required-interface=sri_INFO_CPO_ARD
      rp_INFO_CPO_ARG: unqueued-receiver-com-spec{data-element=INFO_CPO_ARG, handle-invalid=KEEP, init-value=cst_Boolean_init/boolean_init, resync-time=0.0}, required-interface=sri_INFO_CPO_ARG
      rp_INFO_CPO_AVD: unqueued-receiver-com-spec{data-element=INFO_CPO_AVD, handle-invalid=KEEP, init-value=cst_Boolean_init/boolean_init, resync-time=0.0}, required-interface=sri_INFO_CPO_AVD
      rp_INFO_CPO_AVG: unqueued-receiver-com-spec{data-element=INFO_CPO_AVG, handle-invalid=KEEP, init-value=cst_Boolean_init/boolean_init, resync-time=0.0}, required-interface=sri_INFO_CPO_AVG
    6 x provide port:
      pp_ETAT_CPO_PASS: unqueued-sender-com-spec{data-element=ETAT_CPO_PASS, init-value=cst_Boolean_init/boolean_init}, provided-interface=sri_ETAT_CPO_PASS
      pp_ETAT_CPO_ARG: unqueued-sender-com-spec{data-element=ETAT_CPO_ARG, init-value=cst_Boolean_init/boolean_init}, provided-interface=sri_ETAT_CPO_ARG
      pp_ETAT_CPO_ARD: unqueued-sender-com-spec{data-element=ETAT_CPO_ARD, init-value=cst_Boolean_init/boolean_init}, provided-interface=sri_ETAT_CPO_ARD
      pp_P_LED_GAV_ETAT_VERR_CENT: unqueued-sender-com-spec{data-element=P_LED_GAV_ETAT_VERR_CENT, init-value=cst_Boolean_init/boolean_init}, provided-interface=sri_P_LED_GAV_ETAT_VERR_CENT
      pp_P_LED_GAV_ETAT_VERR_ZONE_CH: unqueued-sender-com-spec{data-element=P_LED_GAV_ETAT_VERR_ZONE_CH, init-value=cst_Boolean_init/boolean_init}, provided-interface=sri_P_LED_GAV_ETAT_VERR_ZONE_CH
      pp_P_LED_GAV_ETAT_SECU_ENF: unqueued-sender-com-spec{data-element=P_LED_GAV_ETAT_SECU_ENF, init-value=cst_Boolean_init/boolean_init}, provided-interface=sri_P_LED_GAV_ETAT_SECU_ENF
    require port rp_CHOC_DEVERROUILLAGE: unqueued-receiver-com-spec{data-element=CHOC_DEVERROUILLAGE, handle-invalid=KEEP, init-value=cst_Boolean_init/boolean_init, resync-time=0.0}, required-interface=sri_CHOC_DEVERROUILLAGE
    provide port pp_DECONDA_DESACTIVE_ALARME: unqueued-sender-com-spec{data-element=DECONDA_DESACTIVE_ALARME, init-value=cst_Boolean_init/boolean_init}, provided-interface=sri_DECONDA_DESACTIVE_ALARME
    provide port pp_CONDA_ACTIVE_ALARME: unqueued-sender-com-spec{data-element=CONDA_ACTIVE_ALARME, init-value=cst_Boolean_init/boolean_init}, provided-interface=sri_CONDA_ACTIVE_ALARME
    provide port pp_REBOND_ACTIVE_ALARME: unqueued-sender-com-spec{data-element=REBOND_ACTIVE_ALARME, init-value=cst_Boolean_init/boolean_init}, provided-interface=sri_REBOND_ACTIVE_ALARME
    require port rp_VITESSE_LONGITUDINALE: unqueued-receiver-com-spec{data-element=sri_VITESSE_LONGITUDINALE/VITESSE_LONGITUDINALE, handle-invalid=KEEP, init-value=cst_UInt16_init/uint16_init, resync-time=0.0}, required-interface=AR_GAV_SWC/sri_VITESSE_LONGITUDINALE
    require port rp_UTILISATEUR_DS_HAB: unqueued-receiver-com-spec{data-element=UTILISATEUR_DS_HAB, handle-invalid=KEEP, init-value=cst_Boolean_init/boolean_init, resync-time=0.0}, required-interface=sri_UTILISATEUR_DS_HAB
    require port rp_INFO_GMP: unqueued-receiver-com-spec{data-element=sri_INFO_GMP/INFO_GMP, handle-invalid=KEEP, init-value=cst_UInt8_init/uint8_init, resync-time=0.0}, required-interface=AR_GAV_SWC/sri_INFO_GMP
    7 x provide port:
      pp_ACTION_SERRURES_EN_COURS: unqueued-sender-com-spec{data-element=sri_ACTION_SERRURES_EN_COURS/Y, init-value=cst_Boolean_init/boolean_init}, provided-interface=sri_ACTION_SERRURES_EN_COURS
      pp_CMD_SERR_MOT_COMMUN: unqueued-sender-com-spec{data-element=CMD_SERR_MOT_COMMUN, init-value=cst_Boolean_init/boolean_init}, provided-interface=sri_CMD_SERR_MOT_COMMUN
      pp_CMD_SERR_MOT_EXT: unqueued-sender-com-spec{data-element=CMD_SERR_MOT_EXT, init-value=cst_Boolean_init/boolean_init}, provided-interface=sri_CMD_SERR_MOT_EXT
      pp_CMD_SERR_MOT_EXT_SELECT: unqueued-sender-com-spec{data-element=CMD_SERR_MOT_EXT_SELECT, init-value=cst_Boolean_init/boolean_init}, provided-interface=sri_CMD_SERR_MOT_EXT_SELECT
      pp_CMD_SERR_MOT_INT_AR: unqueued-sender-com-spec{data-element=CMD_SERR_MOT_INT_AR, init-value=cst_Boolean_init/boolean_init}, provided-interface=sri_CMD_SERR_MOT_INT_AR
      pp_CMD_SERR_MOT_INT_AV: unqueued-sender-com-spec{data-element=CMD_SERR_MOT_INT_AV, init-value=cst_Boolean_init/boolean_init}, provided-interface=sri_CMD_SERR_MOT_INT_AV
      pp_PROTECTION_THERMIQUE: unqueued-sender-com-spec{data-element=PROTECTION_THERMIQUE, init-value=cst_Boolean_init/boolean_init}, provided-interface=sri_PROTECTION_THERMIQUE
    require port rp_NUM_BOUTON_APPUI_TELECMD: unqueued-receiver-com-spec{data-element=NUM_BOUTON_APPUI_TELECMD, handle-invalid=KEEP, init-value=cst_UInt8_init/uint8_init, resync-time=0.0}, required-interface=sri_NUM_BOUTON_APPUI_TELECMD
    require port rp_TYPE_APPUI_BOUTON_TELECMD: unqueued-receiver-com-spec{data-element=TYPE_APPUI_BOUTON_TELECMD, handle-invalid=KEEP, init-value=cst_Boolean_init/boolean_init, resync-time=0.0}, required-interface=sri_TYPE_APPUI_BOUTON_TELECMD
    require port rp_NUM_IDENTIFIANT_HF_TELECMD: unqueued-receiver-com-spec{data-element=NUM_IDENTIFIANT_HF_TELECMD, handle-invalid=KEEP, init-value=cst_UInt32_init/uint32_init, resync-time=0.0}, required-interface=sri_NUM_IDENTIFIANT_HF_TELECMD
    provide port pp_AUTOR_FONCT_TELECMD: unqueued-sender-com-spec{data-element=AUTOR_FONCT_TELECMD, init-value=cst_Boolean_init/boolean_init}, provided-interface=sri_AUTOR_FONCT_TELECMD
    require port rp_DMDP_GAV_VERR_CENTRALISE: unqueued-receiver-com-spec{data-element=DMDP_GAV_VERR_CENTRALISE, handle-invalid=KEEP, init-value=cst_Boolean_init/boolean_init, resync-time=0.0}, required-interface=sri_DMDP_GAV_VERR_CENTRALISE
    require port rp_DMDP_GAV_SECU_ENFANT: unqueued-receiver-com-spec{data-element=DMDP_GAV_SECU_ENFANT, handle-invalid=KEEP, init-value=cst_Boolean_init/boolean_init, resync-time=0.0}, required-interface=sri_DMDP_GAV_SECU_ENFANT
    component MDL_GAV: type=MDL_GAV
    delegate MDL_GAV.rp_ETAT_PRINCIP_SEV <-> outer port GAV/rp_ETAT_PRINCIP_SEV
    delegate MDL_GAV.rp_INFO_CAV_AVG <-> outer port GAV/rp_INFO_CAV_AVG
    delegate MDL_GAV.rp_INFO_CAV_AVD <-> outer port GAV/rp_INFO_CAV_AVD
    delegate MDL_GAV.rp_INFO_CPO_ARD <-> outer port GAV/rp_INFO_CPO_ARD
    delegate MDL_GAV.rp_INFO_CPO_ARG <-> outer port GAV/rp_INFO_CPO_ARG
    delegate MDL_GAV.rp_INFO_CPO_AVD <-> outer port GAV/rp_INFO_CPO_AVD
    delegate MDL_GAV.rp_INFO_CPO_AVG <-> outer port GAV/rp_INFO_CPO_AVG
    delegate MDL_GAV.pp_ETAT_CPO_PASS <-> outer port GAV/pp_ETAT_CPO_PASS
    delegate MDL_GAV.pp_ETAT_CPO_COND <-> outer port GAV/pp_ETAT_CPO_COND
    delegate MDL_GAV.pp_ETAT_CPO_ARG <-> outer port GAV/pp_ETAT_CPO_ARG
    delegate MDL_GAV.pp_ETAT_CPO_ARD <-> outer port GAV/pp_ETAT_CPO_ARD
    delegate MDL_GAV.pp_P_LED_GAV_ETAT_VERR_CENT <-> outer port GAV/pp_P_LED_GAV_ETAT_VERR_CENT
    delegate MDL_GAV.pp_P_LED_GAV_ETAT_VERR_ZONE_CH <-> outer port GAV/pp_P_LED_GAV_ETAT_VERR_ZONE_CH
    delegate MDL_GAV.pp_P_LED_GAV_ETAT_SECU_ENF <-> outer port GAV/pp_P_LED_GAV_ETAT_SECU_ENF
    delegate MDL_GAV.rp_CHOC_DEVERROUILLAGE <-> outer port GAV/rp_CHOC_DEVERROUILLAGE
    delegate MDL_GAV.pp_DECONDA_DESACTIVE_ALARME <-> outer port GAV/pp_DECONDA_DESACTIVE_ALARME
    delegate MDL_GAV.pp_CONDA_ACTIVE_ALARME <-> outer port GAV/pp_CONDA_ACTIVE_ALARME
    delegate MDL_GAV.pp_REBOND_ACTIVE_ALARME <-> outer port GAV/pp_REBOND_ACTIVE_ALARME
    delegate MDL_GAV.pp_ETAT_CONDA <-> outer port GAV/pp_ETAT_CONDA
    delegate MDL_GAV.pp_TYPE_CONDA <-> outer port GAV/pp_TYPE_CONDA
    delegate MDL_GAV.rp_VITESSE_LONGITUDINALE <-> outer port GAV/rp_VITESSE_LONGITUDINALE
    delegate MDL_GAV.rp_UTILISATEUR_DS_HAB <-> outer port GAV/rp_UTILISATEUR_DS_HAB
    delegate MDL_GAV.rp_INFO_GMP <-> outer port GAV/rp_INFO_GMP
    delegate MDL_GAV.pp_ACTION_SERRURES_EN_COURS <-> outer port GAV/pp_ACTION_SERRURES_EN_COURS
    delegate MDL_GAV.pp_CMD_SERR_MOT_COMMUN <-> outer port GAV/pp_CMD_SERR_MOT_COMMUN
    delegate MDL_GAV.pp_CMD_SERR_MOT_EXT <-> outer port GAV/pp_CMD_SERR_MOT_EXT
    delegate MDL_GAV.pp_CMD_SERR_MOT_EXT_SELECT <-> outer port GAV/pp_CMD_SERR_MOT_EXT_SELECT
    delegate MDL_GAV.pp_CMD_SERR_MOT_INT_AR <-> outer port GAV/pp_CMD_SERR_MOT_INT_AR
    delegate MDL_GAV.pp_CMD_SERR_MOT_INT_AV <-> outer port GAV/pp_CMD_SERR_MOT_INT_AV
    delegate MDL_GAV.pp_PROTECTION_THERMIQUE <-> outer port GAV/pp_PROTECTION_THERMIQUE
    delegate MDL_GAV.rp_NUM_BOUTON_APPUI_TELECMD <-> outer port GAV/rp_NUM_BOUTON_APPUI_TELECMD
    delegate MDL_GAV.rp_TYPE_APPUI_BOUTON_TELECMD <-> outer port GAV/rp_TYPE_APPUI_BOUTON_TELECMD
    delegate MDL_GAV.rp_NUM_IDENTIFIANT_HF_TELECMD <-> outer port GAV/rp_NUM_IDENTIFIANT_HF_TELECMD
    delegate MDL_GAV.pp_AUTOR_FONCT_TELECMD <-> outer port GAV/pp_AUTOR_FONCT_TELECMD
    delegate MDL_GAV.pp_DMD_LOCAL_TELECMD <-> outer port GAV/pp_DMD_LOCAL_TELECMD
    delegate MDL_GAV.rp_DMDP_GAV_VERR_CENTRALISE <-> outer port GAV/rp_DMDP_GAV_VERR_CENTRALISE
    delegate MDL_GAV.rp_DMDP_GAV_SECU_ENFANT <-> outer port GAV/rp_DMDP_GAV_SECU_ENFANT
  internal behavior ib_SECU_ENF: component=SECU_ENF
    timing event evt_SECU_ENF: start-on-event=SECU_ENF, period=0.1
    runnable SECU_ENF
      5 x data read access:
        dra_DMD_PUSH_SECU_ENFANT: data-element=rp_DMD_PUSH_SECU_ENFANT.DMD_PUSH_SECU_ENFANT
        dra_DMD_CHOC_DEVERROUILLAGE: data-element=rp_DMD_CHOC_DEVERROUILLAGE.DMD_CHOC_DEVERROUILLAGE
        dra_Y: data-element=rp_ACTION_SERRURES_EN_COURS.Y
        dra_ETAT_CONDA: data-element=rp_ETAT_CONDA.ETAT_CONDA
        dra_ETAT_PRINCIP_SEV: data-element=rp_ETAT_PRINCIP_SEV.ETAT_PRINCIP_SEV
      4 x data write access:
        dwa_DMD_ACTIVE_SECU_ENFANT: data-element=pp_DMD_ACTIVE_SECU_ENFANT.DMD_ACTIVE_SECU_ENFANT
        dwa_DMD_DESACTIVE_SECU_ENFANT: data-element=pp_DMD_DESACTIVE_SECU_ENFANT.DMD_DESACTIVE_SECU_ENFANT
        dwa_Y: data-element=pp_ETAT_SECURITE_ENFANT.Y
        dwa_CMD_ALLUME_LED_SECU_ENFANT: data-element=pp_CMD_ALLUME_LED_SECU_ENFANT.CMD_ALLUME_LED_SECU_ENFANT
  sender receiver interface sri_DMD_PUSH_SECU_ENFANT
    data DMD_PUSH_SECU_ENFANT: type=AR_GAV_SWC/Boolean
  constant specification cst_Boolean_init
    value:
      boolean literal boolean_init: type=AR_GAV_SWC/Boolean, value=false
  sender receiver interface sri_DMD_CHOC_DEVERROUILLAGE
    data DMD_CHOC_DEVERROUILLAGE: type=AR_GAV_SWC/Boolean
  sender receiver interface sri_ACTION_SERRURES_EN_COURS
    data Y: type=AR_GAV_SWC/Boolean
  sender receiver interface sri_ETAT_CONDA
    data ETAT_CONDA: type=AR_GAV_SWC/UInt8
  constant specification cst_UInt8_init
    value:
      integer literal uint8_init: type=AR_GAV_SWC/UInt8, value=0
  5 x sender receiver interface:
    sri_ETAT_PRINCIP_SEV
      data ETAT_PRINCIP_SEV: type=AR_GAV_SWC/UInt8
    sri_DMD_ACTIVE_SECU_ENFANT
      data DMD_ACTIVE_SECU_ENFANT: type=AR_GAV_SWC/Boolean
    sri_DMD_DESACTIVE_SECU_ENFANT
      data DMD_DESACTIVE_SECU_ENFANT: type=AR_GAV_SWC/Boolean
    sri_ETAT_SECURITE_ENFANT
      data Y: type=AR_GAV_SWC/Boolean
    sri_CMD_ALLUME_LED_SECU_ENFANT
      data CMD_ALLUME_LED_SECU_ENFANT: type=AR_GAV_SWC/Boolean
  swc implementation implem_SECU_ENF: programming-language=C, behavior=ib_SECU_ENF
    code-descriptors:
      code implem_SECU_ENF: type=SRC
        xfile SECU_ENF.c: url=Src_C/SECU_ENF.c
  8 x sender receiver interface:
    sri_CMD_SERR_MOT_COMMUN
      data CMD_SERR_MOT_COMMUN: type=AR_GAV_SWC/Boolean
    sri_P_LED_GAV_ETAT_SECU_ENF
      data P_LED_GAV_ETAT_SECU_ENF: type=AR_GAV_SWC/Boolean
    sri_P_LED_GAV_ETAT_VERR_CENT
      data P_LED_GAV_ETAT_VERR_CENT: type=AR_GAV_SWC/Boolean
    sri_INFO_CPO_ARG
      data INFO_CPO_ARG: type=AR_GAV_SWC/Boolean
    sri_INFO_CPO_AVG
      data INFO_CPO_AVG: type=AR_GAV_SWC/Boolean
    sri_INFO_CAV_AVG
      data INFO_CAV_AVG: type=AR_GAV_SWC/Boolean
    sri_DMDP_GAV_SECU_ENFANT
      data DMDP_GAV_SECU_ENFANT: type=AR_GAV_SWC/Boolean
    sri_DMDP_GAV_VERR_CENTRALISE
      data DMDP_GAV_VERR_CENTRALISE: type=AR_GAV_SWC/Boolean
  application software component type INFO_SER
    6 x require port:
      rp_INFO_CAV_AVG: unqueued-receiver-com-spec{data-element=INFO_CAV_AVG, handle-invalid=KEEP, init-value=cst_Boolean_init/boolean_init, resync-time=0.0}, required-interface=sri_INFO_CAV_AVG
      rp_INFO_CAV_AVD: unqueued-receiver-com-spec{data-element=INFO_CAV_AVD, handle-invalid=KEEP, init-value=cst_Boolean_init/boolean_init, resync-time=0.0}, required-interface=sri_INFO_CAV_AVD
      rp_INFO_CPO_ARD: unqueued-receiver-com-spec{data-element=INFO_CPO_ARD, handle-invalid=KEEP, init-value=cst_Boolean_init/boolean_init, resync-time=0.0}, required-interface=sri_INFO_CPO_ARD
      rp_INFO_CPO_ARG: unqueued-receiver-com-spec{data-element=INFO_CPO_ARG, handle-invalid=KEEP, init-value=cst_Boolean_init/boolean_init, resync-time=0.0}, required-interface=sri_INFO_CPO_ARG
      rp_INFO_CPO_AVD: unqueued-receiver-com-spec{data-element=INFO_CPO_AVD, handle-invalid=KEEP, init-value=cst_Boolean_init/boolean_init, resync-time=0.0}, required-interface=sri_INFO_CPO_AVD
      rp_INFO_CPO_AVG: unqueued-receiver-com-spec{data-element=INFO_CPO_AVG, handle-invalid=KEEP, init-value=cst_Boolean_init/boolean_init, resync-time=0.0}, required-interface=sri_INFO_CPO_AVG
    10 x provide port:
      pp_ETAT_CPO_PASS: unqueued-sender-com-spec{data-element=ETAT_CPO_PASS, init-value=cst_Boolean_init/boolean_init}, provided-interface=sri_ETAT_CPO_PASS
      pp_ETAT_CPO_COND: unqueued-sender-com-spec{data-element=sri_ETAT_CPO_COND/ETAT_CPO_COND, init-value=cst_Boolean_init/boolean_init}, provided-interface=AR_GAV_SWC/sri_ETAT_CPO_COND
      pp_ETAT_CPO_ARG: unqueued-sender-com-spec{data-element=ETAT_CPO_ARG, init-value=cst_Boolean_init/boolean_init}, provided-interface=sri_ETAT_CPO_ARG
      pp_ETAT_CPO_ARD: unqueued-sender-com-spec{data-element=ETAT_CPO_ARD, init-value=cst_Boolean_init/boolean_init}, provided-interface=sri_ETAT_CPO_ARD
      pp_DMD_OVERRIDE_COND: unqueued-sender-com-spec{data-element=DMD_OVERRIDE_COND, init-value=cst_Boolean_init/boolean_init}, provided-interface=sri_DMD_OVERRIDE_COND
      pp_DMD_OVERRIDE_PASS: unqueued-sender-com-spec{data-element=DMD_OVERRIDE_PASS, init-value=cst_Boolean_init/boolean_init}, provided-interface=sri_DMD_OVERRIDE_PASS
      pp_DMD_OVERRIDE_ARG: unqueued-sender-com-spec{data-element=DMD_OVERRIDE_ARG, init-value=cst_Boolean_init/boolean_init}, provided-interface=sri_DMD_OVERRIDE_ARG
      pp_DMD_OVERRIDE_ARD: unqueued-sender-com-spec{data-element=DMD_OVERRIDE_ARD, init-value=cst_Boolean_init/boolean_init}, provided-interface=sri_DMD_OVERRIDE_ARD
      pp_DMD_DECONDA_VERROU_COND: unqueued-sender-com-spec{data-element=DMD_DECONDA_VERROU_COND, init-value=cst_Boolean_init/boolean_init}, provided-interface=sri_DMD_DECONDA_VERROU_COND
      pp_DMD_CONDA_VERROU_COND: unqueued-sender-com-spec{data-element=CONDA_VERROU, init-value=cst_Boolean_init/boolean_init}, provided-interface=sri_DMD_CONDA_VERROU_COND
  internal behavior ib_INFO_SER: component=INFO_SER
    timing event evt_INFO_SER: start-on-event=INFO_SER, period=0.1
    runnable INFO_SER
      6 x data read access:
        dra_INFO_CAV_AVG: data-element=rp_INFO_CAV_AVG.INFO_CAV_AVG
        dra_INFO_CAV_AVD: data-element=rp_INFO_CAV_AVD.INFO_CAV_AVD
        dra_INFO_CPO_ARD: data-element=rp_INFO_CPO_ARD.INFO_CPO_ARD
        dra_INFO_CPO_ARG: data-element=rp_INFO_CPO_ARG.INFO_CPO_ARG
        dra_INFO_CPO_AVD: data-element=rp_INFO_CPO_AVD.INFO_CPO_AVD
        dra_INFO_CPO_AVG: data-element=rp_INFO_CPO_AVG.INFO_CPO_AVG
      10 x data write access:
        dwa_ETAT_CPO_PASS: data-element=pp_ETAT_CPO_PASS.ETAT_CPO_PASS
        dwa_ETAT_CPO_COND: data-element=pp_ETAT_CPO_COND.ETAT_CPO_COND
        dwa_ETAT_CPO_ARG: data-element=pp_ETAT_CPO_ARG.ETAT_CPO_ARG
        dwa_ETAT_CPO_ARD: data-element=pp_ETAT_CPO_ARD.ETAT_CPO_ARD
        dwa_DMD_OVERRIDE_COND: data-element=pp_DMD_OVERRIDE_COND.DMD_OVERRIDE_COND
        dwa_DMD_OVERRIDE_PASS: data-element=pp_DMD_OVERRIDE_PASS.DMD_OVERRIDE_PASS
        dwa_DMD_OVERRIDE_ARG: data-element=pp_DMD_OVERRIDE_ARG.DMD_OVERRIDE_ARG
        dwa_DMD_OVERRIDE_ARD: data-element=pp_DMD_OVERRIDE_ARD.DMD_OVERRIDE_ARD
        dwa_DMD_DECONDA_VERROU_COND: data-element=pp_DMD_DECONDA_VERROU_COND.DMD_DECONDA_VERROU_COND
        dwa_CONDA_VERROU: data-element=pp_DMD_CONDA_VERROU_COND.CONDA_VERROU
  13 x sender receiver interface:
    sri_INFO_CAV_AVD
      data INFO_CAV_AVD: type=AR_GAV_SWC/Boolean
    sri_INFO_CPO_ARD
      data INFO_CPO_ARD: type=AR_GAV_SWC/Boolean
    sri_INFO_CPO_AVD
      data INFO_CPO_AVD: type=AR_GAV_SWC/Boolean
    sri_ETAT_CPO_PASS
      data ETAT_CPO_PASS: type=AR_GAV_SWC/Boolean
    sri_ETAT_CPO_COND
      data ETAT_CPO_COND: type=AR_GAV_SWC/Boolean
    sri_ETAT_CPO_ARG
      data ETAT_CPO_ARG: type=AR_GAV_SWC/Boolean
    sri_ETAT_CPO_ARD
      data ETAT_CPO_ARD: type=AR_GAV_SWC/Boolean
    sri_DMD_OVERRIDE_COND
      data DMD_OVERRIDE_COND: type=AR_GAV_SWC/Boolean
    sri_DMD_OVERRIDE_PASS
      data DMD_OVERRIDE_PASS: type=AR_GAV_SWC/Boolean
    sri_DMD_OVERRIDE_ARG
      data DMD_OVERRIDE_ARG: type=AR_GAV_SWC/Boolean
    sri_DMD_OVERRIDE_ARD
      data DMD_OVERRIDE_ARD: type=AR_GAV_SWC/Boolean
    sri_DMD_DECONDA_VERROU_COND
      data DMD_DECONDA_VERROU_COND: type=AR_GAV_SWC/Boolean
    sri_DMD_CONDA_VERROU_COND
      data CONDA_VERROU: type=AR_GAV_SWC/Boolean
  swc implementation implem_INFO_SER: programming-language=C, behavior=ib_INFO_SER
    code-descriptors:
      code implem_INFO_SER: type=SRC
        xfile INFO_SER.c: url=Src_C/INFO_SER.c
  application software component type LED
    require port rp_CMD_ALLUME_LED_SECU_ENFANT: unqueued-receiver-com-spec{data-element=CMD_ALLUME_LED_SECU_ENFANT, handle-invalid=KEEP, init-value=cst_Boolean_init/boolean_init, resync-time=0.0}, required-interface=sri_CMD_ALLUME_LED_SECU_ENFANT
    require port rp_ETAT_CONDA: unqueued-receiver-com-spec{data-element=sri_ETAT_CONDA/ETAT_CONDA, handle-invalid=KEEP, init-value=cst_UInt8_init/uint8_init, resync-time=0.0}, required-interface=AR_GAV_SWC/sri_ETAT_CONDA
    require port rp_ETAT_PRINCIP_SEV: unqueued-receiver-com-spec{data-element=sri_ETAT_PRINCIP_SEV/ETAT_PRINCIP_SEV, handle-invalid=KEEP, init-value=cst_UInt8_init/uint8_init, resync-time=0.0}, required-interface=AR_GAV_SWC/sri_ETAT_PRINCIP_SEV
    provide port pp_P_LED_GAV_ETAT_VERR_CENT: unqueued-sender-com-spec{data-element=P_LED_GAV_ETAT_VERR_CENT, init-value=cst_Boolean_init/boolean_init}, provided-interface=sri_P_LED_GAV_ETAT_VERR_CENT
    provide port pp_P_LED_GAV_ETAT_VERR_ZONE_CH: unqueued-sender-com-spec{data-element=P_LED_GAV_ETAT_VERR_ZONE_CH, init-value=cst_Boolean_init/boolean_init}, provided-interface=sri_P_LED_GAV_ETAT_VERR_ZONE_CH
    provide port pp_P_LED_GAV_ETAT_SECU_ENF: unqueued-sender-com-spec{data-element=P_LED_GAV_ETAT_SECU_ENF, init-value=cst_Boolean_init/boolean_init}, provided-interface=sri_P_LED_GAV_ETAT_SECU_ENF
  internal behavior ib_LED: component=LED
    timing event evt_LED: start-on-event=LED, period=0.1
    runnable LED
      data read access dra_CMD_ALLUME_LED_SECU_ENFANT: data-element=rp_CMD_ALLUME_LED_SECU_ENFANT.CMD_ALLUME_LED_SECU_ENFANT
      data read access dra_ETAT_CONDA: data-element=rp_ETAT_CONDA.ETAT_CONDA
      data read access dra_ETAT_PRINCIP_SEV: data-element=rp_ETAT_PRINCIP_SEV.ETAT_PRINCIP_SEV
      data write access dwa_P_LED_GAV_ETAT_VERR_CENT: data-element=pp_P_LED_GAV_ETAT_VERR_CENT.P_LED_GAV_ETAT_VERR_CENT
      data write access dwa_P_LED_GAV_ETAT_VERR_ZONE_CH: data-element=pp_P_LED_GAV_ETAT_VERR_ZONE_CH.P_LED_GAV_ETAT_VERR_ZONE_CH
      data write access dwa_P_LED_GAV_ETAT_SECU_ENF: data-element=pp_P_LED_GAV_ETAT_SECU_ENF.P_LED_GAV_ETAT_SECU_ENF
  sender receiver interface sri_P_LED_GAV_ETAT_VERR_ZONE_CH
    data P_LED_GAV_ETAT_VERR_ZONE_CH: type=AR_GAV_SWC/Boolean
  swc implementation implem_LED: programming-language=C, behavior=ib_LED
    code-descriptors:
      code implem_LED: type=SRC
        xfile LED.c: url=Src_C/LED.c
  application software component type AUTO_VER_DEV
    29 x require port:
      rp_DMD_PUSH_CONDA_APPUI_COURT: unqueued-receiver-com-spec{data-element=DMD_PUSH_CONDA_APPUI_COURT, handle-invalid=KEEP, init-value=cst_Boolean_init/boolean_init, resync-time=0.0}, required-interface=sri_DMD_PUSH_CONDA_APPUI_COURT
      rp_DMD_PUSH_CONDA_APPUI_LONG: unqueued-receiver-com-spec{data-element=DMD_PUSH_CONDA_APPUI_LONG, handle-invalid=KEEP, init-value=cst_Boolean_init/boolean_init, resync-time=0.0}, required-interface=sri_DMD_PUSH_CONDA_APPUI_LONG
      rp_DMD_CHOC_DEVERROUILLAGE: unqueued-receiver-com-spec{data-element=DMD_CHOC_DEVERROUILLAGE, handle-invalid=KEEP, init-value=cst_Boolean_init/boolean_init, resync-time=0.0}, required-interface=sri_DMD_CHOC_DEVERROUILLAGE
      rp_DMD_CONDA_AUTO_LATENCE: unqueued-receiver-com-spec{data-element=DMD_CONDA_AUTO_LATENCE, handle-invalid=KEEP, init-value=cst_Boolean_init/boolean_init, resync-time=0.0}, required-interface=sri_DMD_CONDA_AUTO_LATENCE
      rp_DMD_CONDA_AUTO_ROULAGE: unqueued-receiver-com-spec{data-element=DMD_CONDA_AUTO_ROULAGE, handle-invalid=KEEP, init-value=cst_Boolean_init/boolean_init, resync-time=0.0}, required-interface=sri_DMD_CONDA_AUTO_ROULAGE
      rp_DMD_CONDA_COFFRE_ROULAGE: unqueued-receiver-com-spec{data-element=DMD_CONDA_COFFRE_ROULAGE, handle-invalid=KEEP, init-value=cst_Boolean_init/boolean_init, resync-time=0.0}, required-interface=sri_DMD_CONDA_COFFRE_ROULAGE
      rp_DMD_DECONDA_AUTO_ROULAGE: unqueued-receiver-com-spec{data-element=DMD_DECONDA_AUTO_ROULAGE, handle-invalid=KEEP, init-value=cst_Boolean_init/boolean_init, resync-time=0.0}, required-interface=sri_DMD_DECONDA_AUTO_ROULAGE
      rp_DMD_DECONDA_INVIOLABILITE: unqueued-receiver-com-spec{data-element=DMD_DECONDA_INVIOLABILITE, handle-invalid=KEEP, init-value=cst_Boolean_init/boolean_init, resync-time=0.0}, required-interface=sri_DMD_DECONDA_INVIOLABILITE
      rp_DMD_DECONDA_MENU_PERSO: unqueued-receiver-com-spec{data-element=DMD_DECONDA_MENU_PERSO, handle-invalid=KEEP, init-value=cst_Boolean_init/boolean_init, resync-time=0.0}, required-interface=sri_DMD_DECONDA_MENU_PERSO
      rp_DMD_DESUPERCONDA_AUTHENT: unqueued-receiver-com-spec{data-element=DMD_DESUPERCONDA_AUTHENT, handle-invalid=KEEP, init-value=cst_Boolean_init/boolean_init, resync-time=0.0}, required-interface=sri_DMD_DESUPERCONDA_AUTHENT
      rp_ETAT_PRINCIP_SEV: unqueued-receiver-com-spec{data-element=sri_ETAT_PRINCIP_SEV/ETAT_PRINCIP_SEV, handle-invalid=KEEP, init-value=cst_UInt8_init/uint8_init, resync-time=0.0}, required-interface=AR_GAV_SWC/sri_ETAT_PRINCIP_SEV
      rp_CHOC_DEVERROUILLAGE: unqueued-receiver-com-spec{data-element=CHOC_DEVERROUILLAGE, handle-invalid=KEEP, init-value=cst_Boolean_init/boolean_init, resync-time=0.0}, required-interface=sri_CHOC_DEVERROUILLAGE
      rp_ACTION_SERRURES_EN_COURS: unqueued-receiver-com-spec{data-element=sri_ACTION_SERRURES_EN_COURS/Y, handle-invalid=KEEP, init-value=cst_Boolean_init/boolean_init, resync-time=0.0}, required-interface=sri_ACTION_SERRURES_EN_COURS
      rp_DMD_DECONDA_TELECMD: unqueued-receiver-com-spec{data-element=DMD_DECONDA_TELECMD, handle-invalid=KEEP, init-value=cst_Boolean_init/boolean_init, resync-time=0.0}, required-interface=sri_DMD_DECONDA_TELECMD
      rp_DMD_CONDA_TELECMD: unqueued-receiver-com-spec{data-element=DMD_CONDA_TELECMD, handle-invalid=KEEP, init-value=cst_Boolean_init/boolean_init, resync-time=0.0}, required-interface=sri_DMD_CONDA_TELECMD
      rp_DMD_SUPERCONDA_TELECMD: unqueued-receiver-com-spec{data-element=DMD_SUPERCONDA_TELECMD, handle-invalid=KEEP, init-value=cst_Boolean_init/boolean_init, resync-time=0.0}, required-interface=sri_DMD_SUPERCONDA_TELECMD
      rp_ETAT_CPO_PASS: unqueued-receiver-com-spec{data-element=ETAT_CPO_PASS, handle-invalid=KEEP, init-value=cst_Boolean_init/boolean_init, resync-time=0.0}, required-interface=sri_ETAT_CPO_PASS
      rp_ETAT_CPO_COND: unqueued-receiver-com-spec{data-element=sri_ETAT_CPO_COND/ETAT_CPO_COND, handle-invalid=KEEP, init-value=cst_Boolean_init/boolean_init, resync-time=0.0}, required-interface=AR_GAV_SWC/sri_ETAT_CPO_COND
      rp_ETAT_CPO_ARG: unqueued-receiver-com-spec{data-element=ETAT_CPO_ARG, handle-invalid=KEEP, init-value=cst_Boolean_init/boolean_init, resync-time=0.0}, required-interface=sri_ETAT_CPO_ARG
      rp_ETAT_CPO_ARD: unqueued-receiver-com-spec{data-element=ETAT_CPO_ARD, handle-invalid=KEEP, init-value=cst_Boolean_init/boolean_init, resync-time=0.0}, required-interface=sri_ETAT_CPO_ARD
      rp_DMD_OVERRIDE_COND: unqueued-receiver-com-spec{data-element=DMD_OVERRIDE_COND, handle-invalid=KEEP, init-value=cst_Boolean_init/boolean_init, resync-time=0.0}, required-interface=sri_DMD_OVERRIDE_COND
      rp_DMD_OVERRIDE_PASS: unqueued-receiver-com-spec{data-element=DMD_OVERRIDE_PASS, handle-invalid=KEEP, init-value=cst_Boolean_init/boolean_init, resync-time=0.0}, required-interface=sri_DMD_OVERRIDE_PASS
      rp_DMD_OVERRIDE_ARG: unqueued-receiver-com-spec{data-element=DMD_OVERRIDE_ARG, handle-invalid=KEEP, init-value=cst_Boolean_init/boolean_init, resync-time=0.0}, required-interface=sri_DMD_OVERRIDE_ARG
      rp_DMD_OVERRIDE_ARD: unqueued-receiver-com-spec{data-element=DMD_OVERRIDE_ARD, handle-invalid=KEEP, init-value=cst_Boolean_init/boolean_init, resync-time=0.0}, required-interface=sri_DMD_OVERRIDE_ARD
      rp_DMD_DECONDA_VERROU_COND: unqueued-receiver-com-spec{data-element=DMD_DECONDA_VERROU_COND, handle-invalid=KEEP, init-value=cst_Boolean_init/boolean_init, resync-time=0.0}, required-interface=sri_DMD_DECONDA_VERROU_COND
      rp_DMD_CONDA_VERROU_COND: unqueued-receiver-com-spec{data-element=CONDA_VERROU, handle-invalid=KEEP, init-value=cst_Boolean_init/boolean_init, resync-time=0.0}, required-interface=sri_DMD_CONDA_VERROU_COND
      rp_DMD_ACTIVE_SECU_ENFANT: unqueued-receiver-com-spec{data-element=DMD_ACTIVE_SECU_ENFANT, handle-invalid=KEEP, init-value=cst_Boolean_init/boolean_init, resync-time=0.0}, required-interface=sri_DMD_ACTIVE_SECU_ENFANT
      rp_DMD_DESACTIVE_SECU_ENFANT: unqueued-receiver-com-spec{data-element=DMD_DESACTIVE_SECU_ENFANT, handle-invalid=KEEP, init-value=cst_Boolean_init/boolean_init, resync-time=0.0}, required-interface=sri_DMD_DESACTIVE_SECU_ENFANT
      rp_PROTECTION_THERMIQUE: unqueued-receiver-com-spec{data-element=PROTECTION_THERMIQUE, handle-invalid=KEEP, init-value=cst_Boolean_init/boolean_init, resync-time=0.0}, required-interface=sri_PROTECTION_THERMIQUE
    17 x provide port:
      pp_CMD_ACTIVE_SECU_ENFANT: unqueued-sender-com-spec{data-element=CMD_ACTIVE_SECU_ENFANT, init-value=cst_Boolean_init/boolean_init}, provided-interface=sri_CMD_ACTIVE_SECU_ENFANT
      pp_CMD_CONDA_PORTE_COND: unqueued-sender-com-spec{data-element=CMD_CONDA_PORTE_COND, init-value=cst_Boolean_init/boolean_init}, provided-interface=sri_CMD_CONDA_PORTE_COND
      pp_CMD_CONDA_PORTES: unqueued-sender-com-spec{data-element=CMD_CONDA_PORTES, init-value=cst_Boolean_init/boolean_init}, provided-interface=sri_CMD_CONDA_PORTES
      pp_CMD_DECONDA_PORTE_COND: unqueued-sender-com-spec{data-element=Out4, init-value=cst_Boolean_init/boolean_init}, provided-interface=sri_CMD_DECONDA_PORTE_COND
      pp_CMD_DECONDA_PORTES: unqueued-sender-com-spec{data-element=Out5, init-value=cst_Boolean_init/boolean_init}, provided-interface=sri_CMD_DECONDA_PORTES
      pp_CMD_DECONDA_PORTES_CHOC: unqueued-sender-com-spec{data-element=CMD_DECONDA_PORTES_CHOC, init-value=cst_Boolean_init/boolean_init}, provided-interface=sri_CMD_DECONDA_PORTES_CHOC
      pp_CMD_DESACTIVE_SECU_ENFANT: unqueued-sender-com-spec{data-element=CMD_DESACTIVE_SECU_ENFANT, init-value=cst_Boolean_init/boolean_init}, provided-interface=sri_CMD_DESACTIVE_SECU_ENFANT
      pp_CMD_DESUPERCONDA_PORTES: unqueued-sender-com-spec{data-element=CMD_DESUPERCONDA_PORTES, init-value=cst_Boolean_init/boolean_init}, provided-interface=sri_CMD_DESUPERCONDA_PORTES
      pp_CMD_REBOND_PORTE_COND: unqueued-sender-com-spec{data-element=CMD_REBOND_PORTE_COND, init-value=cst_Boolean_init/boolean_init}, provided-interface=sri_CMD_REBOND_PORTE_COND
      pp_CMD_REBOND_PORTES: unqueued-sender-com-spec{data-element=CMD_REBOND_PORTES, init-value=cst_Boolean_init/boolean_init}, provided-interface=sri_CMD_REBOND_PORTES
      pp_CMD_SUPERCONDA_PORTES: unqueued-sender-com-spec{data-element=Out14, init-value=cst_Boolean_init/boolean_init}, provided-interface=sri_CMD_SUPERCONDA_PORTES
      pp_CONDA_ACTIVE_ALARME: unqueued-sender-com-spec{data-element=CONDA_ACTIVE_ALARME, init-value=cst_Boolean_init/boolean_init}, provided-interface=sri_CONDA_ACTIVE_ALARME
      pp_DECONDA_DESACTIVE_ALARME: unqueued-sender-com-spec{data-element=DECONDA_DESACTIVE_ALARME, init-value=cst_Boolean_init/boolean_init}, provided-interface=sri_DECONDA_DESACTIVE_ALARME
      pp_ETAT_CONDA_AUTO_ROULAGE: unqueued-sender-com-spec{data-element=ETAT_CONDA_AUTO_ROULAGE, init-value=cst_Boolean_init/boolean_init}, provided-interface=sri_ETAT_CONDA_AUTO_ROULAGE
      pp_REBOND_ACTIVE_ALARME: unqueued-sender-com-spec{data-element=REBOND_ACTIVE_ALARME, init-value=cst_Boolean_init/boolean_init}, provided-interface=sri_REBOND_ACTIVE_ALARME
      pp_TYPE_CONDA: unqueued-sender-com-spec{data-element=sri_TYPE_CONDA/TYPE_CONDA, init-value=cst_UInt8_init/uint8_init}, provided-interface=AR_GAV_SWC/sri_TYPE_CONDA
      pp_ETAT_CONDA: unqueued-sender-com-spec{data-element=sri_ETAT_CONDA/ETAT_CONDA, init-value=cst_UInt8_init/uint8_init}, provided-interface=AR_GAV_SWC/sri_ETAT_CONDA
  internal behavior ib_AUTO_VER_DEV: component=AUTO_VER_DEV
    timing event evt_AUTO_VER_DEV: start-on-event=AUTO_VER_DEV, period=0.1
    runnable AUTO_VER_DEV
      29 x data read access:
        dra_DMD_PUSH_CONDA_APPUI_COURT: data-element=rp_DMD_PUSH_CONDA_APPUI_COURT.DMD_PUSH_CONDA_APPUI_COURT
        dra_DMD_PUSH_CONDA_APPUI_LONG: data-element=rp_DMD_PUSH_CONDA_APPUI_LONG.DMD_PUSH_CONDA_APPUI_LONG
        dra_DMD_CHOC_DEVERROUILLAGE: data-element=rp_DMD_CHOC_DEVERROUILLAGE.DMD_CHOC_DEVERROUILLAGE
        dra_DMD_CONDA_AUTO_LATENCE: data-element=rp_DMD_CONDA_AUTO_LATENCE.DMD_CONDA_AUTO_LATENCE
        dra_DMD_CONDA_AUTO_ROULAGE: data-element=rp_DMD_CONDA_AUTO_ROULAGE.DMD_CONDA_AUTO_ROULAGE
        dra_DMD_CONDA_COFFRE_ROULAGE: data-element=rp_DMD_CONDA_COFFRE_ROULAGE.DMD_CONDA_COFFRE_ROULAGE
        dra_DMD_DECONDA_AUTO_ROULAGE: data-element=rp_DMD_DECONDA_AUTO_ROULAGE.DMD_DECONDA_AUTO_ROULAGE
        dra_DMD_DECONDA_INVIOLABILITE: data-element=rp_DMD_DECONDA_INVIOLABILITE.DMD_DECONDA_INVIOLABILITE
        dra_DMD_DECONDA_MENU_PERSO: data-element=rp_DMD_DECONDA_MENU_PERSO.DMD_DECONDA_MENU_PERSO
        dra_DMD_DESUPERCONDA_AUTHENT: data-element=rp_DMD_DESUPERCONDA_AUTHENT.DMD_DESUPERCONDA_AUTHENT
        dra_ETAT_PRINCIP_SEV: data-element=rp_ETAT_PRINCIP_SEV.ETAT_PRINCIP_SEV
        dra_CHOC_DEVERROUILLAGE: data-element=rp_CHOC_DEVERROUILLAGE.CHOC_DEVERROUILLAGE
        dra_Y: data-element=rp_ACTION_SERRURES_EN_COURS.Y
        dra_DMD_DECONDA_TELECMD: data-element=rp_DMD_DECONDA_TELECMD.DMD_DECONDA_TELECMD
        dra_DMD_CONDA_TELECMD: data-element=rp_DMD_CONDA_TELECMD.DMD_CONDA_TELECMD
        dra_DMD_SUPERCONDA_TELECMD: data-element=rp_DMD_SUPERCONDA_TELECMD.DMD_SUPERCONDA_TELECMD
        dra_ETAT_CPO_PASS: data-element=rp_ETAT_CPO_PASS.ETAT_CPO_PASS
        dra_ETAT_CPO_COND: data-element=rp_ETAT_CPO_COND.ETAT_CPO_COND
        dra_ETAT_CPO_ARG: data-element=rp_ETAT_CPO_ARG.ETAT_CPO_ARG
        dra_ETAT_CPO_ARD: data-element=rp_ETAT_CPO_ARD.ETAT_CPO_ARD
        dra_DMD_OVERRIDE_COND: data-element=rp_DMD_OVERRIDE_COND.DMD_OVERRIDE_COND
        dra_DMD_OVERRIDE_PASS: data-element=rp_DMD_OVERRIDE_PASS.DMD_OVERRIDE_PASS
        dra_DMD_OVERRIDE_ARG: data-element=rp_DMD_OVERRIDE_ARG.DMD_OVERRIDE_ARG
        dra_DMD_OVERRIDE_ARD: data-element=rp_DMD_OVERRIDE_ARD.DMD_OVERRIDE_ARD
        dra_DMD_DECONDA_VERROU_COND: data-element=rp_DMD_DECONDA_VERROU_COND.DMD_DECONDA_VERROU_COND
        dra_CONDA_VERROU: data-element=rp_DMD_CONDA_VERROU_COND.CONDA_VERROU
        dra_DMD_ACTIVE_SECU_ENFANT: data-element=rp_DMD_ACTIVE_SECU_ENFANT.DMD_ACTIVE_SECU_ENFANT
        dra_DMD_DESACTIVE_SECU_ENFANT: data-element=rp_DMD_DESACTIVE_SECU_ENFANT.DMD_DESACTIVE_SECU_ENFANT
        dra_PROTECTION_THERMIQUE: data-element=rp_PROTECTION_THERMIQUE.PROTECTION_THERMIQUE
      17 x data write access:
        dwa_CMD_ACTIVE_SECU_ENFANT: data-element=pp_CMD_ACTIVE_SECU_ENFANT.CMD_ACTIVE_SECU_ENFANT
        dwa_CMD_CONDA_PORTE_COND: data-element=pp_CMD_CONDA_PORTE_COND.CMD_CONDA_PORTE_COND
        dwa_CMD_CONDA_PORTES: data-element=pp_CMD_CONDA_PORTES.CMD_CONDA_PORTES
        dwa_Out4: data-element=pp_CMD_DECONDA_PORTE_COND.Out4
        dwa_Out5: data-element=pp_CMD_DECONDA_PORTES.Out5
        dwa_CMD_DECONDA_PORTES_CHOC: data-element=pp_CMD_DECONDA_PORTES_CHOC.CMD_DECONDA_PORTES_CHOC
        dwa_CMD_DESACTIVE_SECU_ENFANT: data-element=pp_CMD_DESACTIVE_SECU_ENFANT.CMD_DESACTIVE_SECU_ENFANT
        dwa_CMD_DESUPERCONDA_PORTES: data-element=pp_CMD_DESUPERCONDA_PORTES.CMD_DESUPERCONDA_PORTES
        dwa_CMD_REBOND_PORTE_COND: data-element=pp_CMD_REBOND_PORTE_COND.CMD_REBOND_PORTE_COND
        dwa_CMD_REBOND_PORTES: data-element=pp_CMD_REBOND_PORTES.CMD_REBOND_PORTES
        dwa_Out14: data-element=pp_CMD_SUPERCONDA_PORTES.Out14
        dwa_CONDA_ACTIVE_ALARME: data-element=pp_CONDA_ACTIVE_ALARME.CONDA_ACTIVE_ALARME
        dwa_DECONDA_DESACTIVE_ALARME: data-element=pp_DECONDA_DESACTIVE_ALARME.DECONDA_DESACTIVE_ALARME
        dwa_ETAT_CONDA_AUTO_ROULAGE: data-element=pp_ETAT_CONDA_AUTO_ROULAGE.ETAT_CONDA_AUTO_ROULAGE
        dwa_REBOND_ACTIVE_ALARME: data-element=pp_REBOND_ACTIVE_ALARME.REBOND_ACTIVE_ALARME
        dwa_TYPE_CONDA: data-element=pp_TYPE_CONDA.TYPE_CONDA
        dwa_ETAT_CONDA: data-element=pp_ETAT_CONDA.ETAT_CONDA
  30 x sender receiver interface:
    sri_DMD_PUSH_CONDA_APPUI_COURT
      data DMD_PUSH_CONDA_APPUI_COURT: type=AR_GAV_SWC/Boolean
    sri_DMD_PUSH_CONDA_APPUI_LONG
      data DMD_PUSH_CONDA_APPUI_LONG: type=AR_GAV_SWC/Boolean
    sri_DMD_CONDA_AUTO_LATENCE
      data DMD_CONDA_AUTO_LATENCE: type=AR_GAV_SWC/Boolean
    sri_DMD_CONDA_AUTO_ROULAGE
      data DMD_CONDA_AUTO_ROULAGE: type=AR_GAV_SWC/Boolean
    sri_DMD_CONDA_COFFRE_ROULAGE
      data DMD_CONDA_COFFRE_ROULAGE: type=AR_GAV_SWC/Boolean
    sri_DMD_DECONDA_AUTO_ROULAGE
      data DMD_DECONDA_AUTO_ROULAGE: type=AR_GAV_SWC/Boolean
    sri_DMD_DECONDA_INVIOLABILITE
      data DMD_DECONDA_INVIOLABILITE: type=AR_GAV_SWC/Boolean
    sri_DMD_DECONDA_MENU_PERSO
      data DMD_DECONDA_MENU_PERSO: type=AR_GAV_SWC/Boolean
    sri_DMD_DESUPERCONDA_AUTHENT
      data DMD_DESUPERCONDA_AUTHENT: type=AR_GAV_SWC/Boolean
    sri_CHOC_DEVERROUILLAGE
      data CHOC_DEVERROUILLAGE: type=AR_GAV_SWC/Boolean
    sri_DMD_DECONDA_TELECMD
      data DMD_DECONDA_TELECMD: type=AR_GAV_SWC/Boolean
    sri_DMD_CONDA_TELECMD
      data DMD_CONDA_TELECMD: type=AR_GAV_SWC/Boolean
    sri_DMD_SUPERCONDA_TELECMD
      data DMD_SUPERCONDA_TELECMD: type=AR_GAV_SWC/Boolean
    sri_PROTECTION_THERMIQUE
      data PROTECTION_THERMIQUE: type=AR_GAV_SWC/Boolean
    sri_CMD_ACTIVE_SECU_ENFANT
      data CMD_ACTIVE_SECU_ENFANT: type=AR_GAV_SWC/Boolean
    sri_CMD_CONDA_PORTE_COND
      data CMD_CONDA_PORTE_COND: type=AR_GAV_SWC/Boolean
    sri_CMD_CONDA_PORTES
      data CMD_CONDA_PORTES: type=AR_GAV_SWC/Boolean
    sri_CMD_DECONDA_PORTE_COND
      data Out4: type=AR_GAV_SWC/Boolean
    sri_CMD_DECONDA_PORTES
      data Out5: type=AR_GAV_SWC/Boolean
    sri_CMD_DECONDA_PORTES_CHOC
      data CMD_DECONDA_PORTES_CHOC: type=AR_GAV_SWC/Boolean
    sri_CMD_DESACTIVE_SECU_ENFANT
      data CMD_DESACTIVE_SECU_ENFANT: type=AR_GAV_SWC/Boolean
    sri_CMD_DESUPERCONDA_PORTES
      data CMD_DESUPERCONDA_PORTES: type=AR_GAV_SWC/Boolean
    sri_CMD_REBOND_PORTE_COND
      data CMD_REBOND_PORTE_COND: type=AR_GAV_SWC/Boolean
    sri_CMD_REBOND_PORTES
      data CMD_REBOND_PORTES: type=AR_GAV_SWC/Boolean
    sri_CMD_SUPERCONDA_PORTES
      data Out14: type=AR_GAV_SWC/Boolean
    sri_CONDA_ACTIVE_ALARME
      data CONDA_ACTIVE_ALARME: type=AR_GAV_SWC/Boolean
    sri_DECONDA_DESACTIVE_ALARME
      data DECONDA_DESACTIVE_ALARME: type=AR_GAV_SWC/Boolean
    sri_ETAT_CONDA_AUTO_ROULAGE
      data ETAT_CONDA_AUTO_ROULAGE: type=AR_GAV_SWC/Boolean
    sri_REBOND_ACTIVE_ALARME
      data REBOND_ACTIVE_ALARME: type=AR_GAV_SWC/Boolean
    sri_TYPE_CONDA
      data TYPE_CONDA: type=AR_GAV_SWC/UInt8
  swc implementation implem_AUTO_VER_DEV: programming-language=C, behavior=ib_AUTO_VER_DEV
    code-descriptors:
      code implem_AUTO_VER_DEV: type=SRC
        xfile AUTO_VER_DEV.c: url=Src_C/AUTO_VER_DEV.c
  application software component type VER_DEV_SPE
    13 x require port:
      rp_ETAT_PRINCIP_SEV: unqueued-receiver-com-spec{data-element=sri_ETAT_PRINCIP_SEV/ETAT_PRINCIP_SEV, handle-invalid=KEEP, init-value=cst_UInt8_init/uint8_init, resync-time=0.0}, required-interface=AR_GAV_SWC/sri_ETAT_PRINCIP_SEV
      rp_CHOC_DEVERROUILLAGE: unqueued-receiver-com-spec{data-element=CHOC_DEVERROUILLAGE, handle-invalid=KEEP, init-value=cst_Boolean_init/boolean_init, resync-time=0.0}, required-interface=sri_CHOC_DEVERROUILLAGE
      rp_UTILISATEUR_DS_HAB: unqueued-receiver-com-spec{data-element=UTILISATEUR_DS_HAB, handle-invalid=KEEP, init-value=cst_Boolean_init/boolean_init, resync-time=0.0}, required-interface=sri_UTILISATEUR_DS_HAB
      rp_ETAT_CONDA: unqueued-receiver-com-spec{data-element=sri_ETAT_CONDA/ETAT_CONDA, handle-invalid=KEEP, init-value=cst_UInt8_init/uint8_init, resync-time=0.0}, required-interface=AR_GAV_SWC/sri_ETAT_CONDA
      rp_DMD_DECONDA_VERROU_COND: unqueued-receiver-com-spec{data-element=DMD_DECONDA_VERROU_COND, handle-invalid=KEEP, init-value=cst_Boolean_init/boolean_init, resync-time=0.0}, required-interface=sri_DMD_DECONDA_VERROU_COND
      rp_ETAT_CPO_PASS: unqueued-receiver-com-spec{data-element=ETAT_CPO_PASS, handle-invalid=KEEP, init-value=cst_Boolean_init/boolean_init, resync-time=0.0}, required-interface=sri_ETAT_CPO_PASS
      rp_ETAT_CPO_COND: unqueued-receiver-com-spec{data-element=sri_ETAT_CPO_COND/ETAT_CPO_COND, handle-invalid=KEEP, init-value=cst_Boolean_init/boolean_init, resync-time=0.0}, required-interface=AR_GAV_SWC/sri_ETAT_CPO_COND
      rp_ETAT_CPO_ARG: unqueued-receiver-com-spec{data-element=ETAT_CPO_ARG, handle-invalid=KEEP, init-value=cst_Boolean_init/boolean_init, resync-time=0.0}, required-interface=sri_ETAT_CPO_ARG
      rp_ETAT_CPO_ARD: unqueued-receiver-com-spec{data-element=ETAT_CPO_ARD, handle-invalid=KEEP, init-value=cst_Boolean_init/boolean_init, resync-time=0.0}, required-interface=sri_ETAT_CPO_ARD
      rp_DMD_DECONDA_TELECMD: unqueued-receiver-com-spec{data-element=DMD_DECONDA_TELECMD, handle-invalid=KEEP, init-value=cst_Boolean_init/boolean_init, resync-time=0.0}, required-interface=sri_DMD_DECONDA_TELECMD
      rp_ETAT_CONDA_AUTO_ROULAGE: unqueued-receiver-com-spec{data-element=ETAT_CONDA_AUTO_ROULAGE, handle-invalid=KEEP, init-value=cst_Boolean_init/boolean_init, resync-time=0.0}, required-interface=sri_ETAT_CONDA_AUTO_ROULAGE
      rp_VITESSE_LONGITUDINALE: unqueued-receiver-com-spec{data-element=sri_VITESSE_LONGITUDINALE/VITESSE_LONGITUDINALE, handle-invalid=KEEP, init-value=cst_UInt16_init/uint16_init, resync-time=0.0}, required-interface=AR_GAV_SWC/sri_VITESSE_LONGITUDINALE
      rp_INFO_GMP: unqueued-receiver-com-spec{data-element=sri_INFO_GMP/INFO_GMP, handle-invalid=KEEP, init-value=cst_UInt8_init/uint8_init, resync-time=0.0}, required-interface=AR_GAV_SWC/sri_INFO_GMP
    8 x provide port:
      pp_DMD_CHOC_DEVERROUILLAGE: unqueued-sender-com-spec{data-element=DMD_CHOC_DEVERROUILLAGE, init-value=cst_Boolean_init/boolean_init}, provided-interface=sri_DMD_CHOC_DEVERROUILLAGE
      pp_DMD_CONDA_AUTO_LATENCE: unqueued-sender-com-spec{data-element=DMD_CONDA_AUTO_LATENCE, init-value=cst_Boolean_init/boolean_init}, provided-interface=sri_DMD_CONDA_AUTO_LATENCE
      pp_DMD_CONDA_AUTO_ROULAGE: unqueued-sender-com-spec{data-element=DMD_CONDA_AUTO_ROULAGE, init-value=cst_Boolean_init/boolean_init}, provided-interface=sri_DMD_CONDA_AUTO_ROULAGE
      pp_DMD_CONDA_COFFRE_ROULAGE: unqueued-sender-com-spec{data-element=DMD_CONDA_COFFRE_ROULAGE, init-value=cst_Boolean_init/boolean_init}, provided-interface=sri_DMD_CONDA_COFFRE_ROULAGE
      pp_DMD_DECONDA_AUTO_ROULAGE: unqueued-sender-com-spec{data-element=DMD_DECONDA_AUTO_ROULAGE, init-value=cst_Boolean_init/boolean_init}, provided-interface=sri_DMD_DECONDA_AUTO_ROULAGE
      pp_DMD_DECONDA_INVIOLABILITE: unqueued-sender-com-spec{data-element=DMD_DECONDA_INVIOLABILITE, init-value=cst_Boolean_init/boolean_init}, provided-interface=sri_DMD_DECONDA_INVIOLABILITE
      pp_DMD_DECONDA_MENU_PERSO: unqueued-sender-com-spec{data-element=DMD_DECONDA_MENU_PERSO, init-value=cst_Boolean_init/boolean_init}, provided-interface=sri_DMD_DECONDA_MENU_PERSO
      pp_DMD_DESUPERCONDA_AUTHENT: unqueued-sender-com-spec{data-element=DMD_DESUPERCONDA_AUTHENT, init-value=cst_Boolean_init/boolean_init}, provided-interface=sri_DMD_DESUPERCONDA_AUTHENT
  internal behavior ib_VER_DEV_SPE: component=VER_DEV_SPE
    timing event evt_VER_DEV_SPE: start-on-event=VER_DEV_SPE, period=0.1
    runnable VER_DEV_SPE
      13 x data read access:
        dra_ETAT_PRINCIP_SEV: data-element=rp_ETAT_PRINCIP_SEV.ETAT_PRINCIP_SEV
        dra_CHOC_DEVERROUILLAGE: data-element=rp_CHOC_DEVERROUILLAGE.CHOC_DEVERROUILLAGE
        dra_UTILISATEUR_DS_HAB: data-element=rp_UTILISATEUR_DS_HAB.UTILISATEUR_DS_HAB
        dra_ETAT_CONDA: data-element=rp_ETAT_CONDA.ETAT_CONDA
        dra_DMD_DECONDA_VERROU_COND: data-element=rp_DMD_DECONDA_VERROU_COND.DMD_DECONDA_VERROU_COND
        dra_ETAT_CPO_PASS: data-element=rp_ETAT_CPO_PASS.ETAT_CPO_PASS
        dra_ETAT_CPO_COND: data-element=rp_ETAT_CPO_COND.ETAT_CPO_COND
        dra_ETAT_CPO_ARG: data-element=rp_ETAT_CPO_ARG.ETAT_CPO_ARG
        dra_ETAT_CPO_ARD: data-element=rp_ETAT_CPO_ARD.ETAT_CPO_ARD
        dra_DMD_DECONDA_TELECMD: data-element=rp_DMD_DECONDA_TELECMD.DMD_DECONDA_TELECMD
        dra_ETAT_CONDA_AUTO_ROULAGE: data-element=rp_ETAT_CONDA_AUTO_ROULAGE.ETAT_CONDA_AUTO_ROULAGE
        dra_VITESSE_LONGITUDINALE: data-element=rp_VITESSE_LONGITUDINALE.VITESSE_LONGITUDINALE
        dra_INFO_GMP: data-element=rp_INFO_GMP.INFO_GMP
      8 x data write access:
        dwa_DMD_CHOC_DEVERROUILLAGE: data-element=pp_DMD_CHOC_DEVERROUILLAGE.DMD_CHOC_DEVERROUILLAGE
        dwa_DMD_CONDA_AUTO_LATENCE: data-element=pp_DMD_CONDA_AUTO_LATENCE.DMD_CONDA_AUTO_LATENCE
        dwa_DMD_CONDA_AUTO_ROULAGE: data-element=pp_DMD_CONDA_AUTO_ROULAGE.DMD_CONDA_AUTO_ROULAGE
        dwa_DMD_CONDA_COFFRE_ROULAGE: data-element=pp_DMD_CONDA_COFFRE_ROULAGE.DMD_CONDA_COFFRE_ROULAGE
        dwa_DMD_DECONDA_AUTO_ROULAGE: data-element=pp_DMD_DECONDA_AUTO_ROULAGE.DMD_DECONDA_AUTO_ROULAGE
        dwa_DMD_DECONDA_INVIOLABILITE: data-element=pp_DMD_DECONDA_INVIOLABILITE.DMD_DECONDA_INVIOLABILITE
        dwa_DMD_DECONDA_MENU_PERSO: data-element=pp_DMD_DECONDA_MENU_PERSO.DMD_DECONDA_MENU_PERSO
        dwa_DMD_DESUPERCONDA_AUTHENT: data-element=pp_DMD_DESUPERCONDA_AUTHENT.DMD_DESUPERCONDA_AUTHENT
  sender receiver interface sri_UTILISATEUR_DS_HAB
    data UTILISATEUR_DS_HAB: type=AR_GAV_SWC/Boolean
  sender receiver interface sri_VITESSE_LONGITUDINALE
    data VITESSE_LONGITUDINALE: type=AR_GAV_SWC/UInt16
  constant specification cst_UInt16_init
    value:
      integer literal uint16_init: type=AR_GAV_SWC/UInt16, value=0
  sender receiver interface sri_INFO_GMP
    data INFO_GMP: type=AR_GAV_SWC/UInt8
  swc implementation implem_VER_DEV_SPE: programming-language=C, behavior=ib_VER_DEV_SPE
    code-descriptors:
      code implem_VER_DEV_SPE: type=SRC
        xfile VER_DEV_SPE.c: url=Src_C/VER_DEV_SPE.c
  application software component type PILOTER_SER
    13 x require port:
      rp_CMD_ACTIVE_SECU_ENFANT: unqueued-receiver-com-spec{data-element=CMD_ACTIVE_SECU_ENFANT, handle-invalid=KEEP, init-value=cst_Boolean_init/boolean_init, resync-time=0.0}, required-interface=sri_CMD_ACTIVE_SECU_ENFANT
      rp_CMD_CONDA_PORTE_COND: unqueued-receiver-com-spec{data-element=CMD_CONDA_PORTE_COND, handle-invalid=KEEP, init-value=cst_Boolean_init/boolean_init, resync-time=0.0}, required-interface=sri_CMD_CONDA_PORTE_COND
      rp_CMD_CONDA_PORTES: unqueued-receiver-com-spec{data-element=CMD_CONDA_PORTES, handle-invalid=KEEP, init-value=cst_Boolean_init/boolean_init, resync-time=0.0}, required-interface=sri_CMD_CONDA_PORTES
      rp_CMD_DECONDA_PORTE_COND: unqueued-receiver-com-spec{data-element=Out4, handle-invalid=KEEP, init-value=cst_Boolean_init/boolean_init, resync-time=0.0}, required-interface=sri_CMD_DECONDA_PORTE_COND
      rp_CMD_DECONDA_PORTES: unqueued-receiver-com-spec{data-element=Out5, handle-invalid=KEEP, init-value=cst_Boolean_init/boolean_init, resync-time=0.0}, required-interface=sri_CMD_DECONDA_PORTES
      rp_CMD_DECONDA_PORTES_CHOC: unqueued-receiver-com-spec{data-element=CMD_DECONDA_PORTES_CHOC, handle-invalid=KEEP, init-value=cst_Boolean_init/boolean_init, resync-time=0.0}, required-interface=sri_CMD_DECONDA_PORTES_CHOC
      rp_CMD_DESACTIVE_SECU_ENFANT: unqueued-receiver-com-spec{data-element=CMD_DESACTIVE_SECU_ENFANT, handle-invalid=KEEP, init-value=cst_Boolean_init/boolean_init, resync-time=0.0}, required-interface=sri_CMD_DESACTIVE_SECU_ENFANT
      rp_CMD_DESUPERCONDA_PORTES: unqueued-receiver-com-spec{data-element=CMD_DESUPERCONDA_PORTES, handle-invalid=KEEP, init-value=cst_Boolean_init/boolean_init, resync-time=0.0}, required-interface=sri_CMD_DESUPERCONDA_PORTES
      rp_CMD_REBOND_PORTE_COND: unqueued-receiver-com-spec{data-element=CMD_REBOND_PORTE_COND, handle-invalid=KEEP, init-value=cst_Boolean_init/boolean_init, resync-time=0.0}, required-interface=sri_CMD_REBOND_PORTE_COND
      rp_CMD_REBOND_PORTES: unqueued-receiver-com-spec{data-element=CMD_REBOND_PORTES, handle-invalid=KEEP, init-value=cst_Boolean_init/boolean_init, resync-time=0.0}, required-interface=sri_CMD_REBOND_PORTES
      rp_CMD_SUPERCONDA_PORTES: unqueued-receiver-com-spec{data-element=Out14, handle-invalid=KEEP, init-value=cst_Boolean_init/boolean_init, resync-time=0.0}, required-interface=sri_CMD_SUPERCONDA_PORTES
      rp_ETAT_CONDA: unqueued-receiver-com-spec{data-element=sri_ETAT_CONDA/ETAT_CONDA, handle-invalid=KEEP, init-value=cst_UInt8_init/uint8_init, resync-time=0.0}, required-interface=AR_GAV_SWC/sri_ETAT_CONDA
      rp_ETAT_SECURITE_ENFANT: unqueued-receiver-com-spec{data-element=sri_ETAT_SECURITE_ENFANT/Y, handle-invalid=KEEP, init-value=cst_Boolean_init/boolean_init, resync-time=0.0}, required-interface=sri_ETAT_SECURITE_ENFANT
    7 x provide port:
      pp_ACTION_SERRURES_EN_COURS: unqueued-sender-com-spec{data-element=sri_ACTION_SERRURES_EN_COURS/Y, init-value=cst_Boolean_init/boolean_init}, provided-interface=sri_ACTION_SERRURES_EN_COURS
      pp_CMD_SERR_MOT_COMMUN: unqueued-sender-com-spec{data-element=CMD_SERR_MOT_COMMUN, init-value=cst_Boolean_init/boolean_init}, provided-interface=sri_CMD_SERR_MOT_COMMUN
      pp_CMD_SERR_MOT_EXT: unqueued-sender-com-spec{data-element=CMD_SERR_MOT_EXT, init-value=cst_Boolean_init/boolean_init}, provided-interface=sri_CMD_SERR_MOT_EXT
      pp_CMD_SERR_MOT_EXT_SELECT: unqueued-sender-com-spec{data-element=CMD_SERR_MOT_EXT_SELECT, init-value=cst_Boolean_init/boolean_init}, provided-interface=sri_CMD_SERR_MOT_EXT_SELECT
      pp_CMD_SERR_MOT_INT_AR: unqueued-sender-com-spec{data-element=CMD_SERR_MOT_INT_AR, init-value=cst_Boolean_init/boolean_init}, provided-interface=sri_CMD_SERR_MOT_INT_AR
      pp_CMD_SERR_MOT_INT_AV: unqueued-sender-com-spec{data-element=CMD_SERR_MOT_INT_AV, init-value=cst_Boolean_init/boolean_init}, provided-interface=sri_CMD_SERR_MOT_INT_AV
      pp_PROTECTION_THERMIQUE: unqueued-sender-com-spec{data-element=PROTECTION_THERMIQUE, init-value=cst_Boolean_init/boolean_init}, provided-interface=sri_PROTECTION_THERMIQUE
  internal behavior ib_PILOTER_SER: component=PILOTER_SER
    timing event evt_PILOTER_SER: start-on-event=PILOTER_SER, period=0.1
    runnable PILOTER_SER
      13 x data read access:
        dra_CMD_ACTIVE_SECU_ENFANT: data-element=rp_CMD_ACTIVE_SECU_ENFANT.CMD_ACTIVE_SECU_ENFANT
        dra_CMD_CONDA_PORTE_COND: data-element=rp_CMD_CONDA_PORTE_COND.CMD_CONDA_PORTE_COND
        dra_CMD_CONDA_PORTES: data-element=rp_CMD_CONDA_PORTES.CMD_CONDA_PORTES
        dra_Out4: data-element=rp_CMD_DECONDA_PORTE_COND.Out4
        dra_Out5: data-element=rp_CMD_DECONDA_PORTES.Out5
        dra_CMD_DECONDA_PORTES_CHOC: data-element=rp_CMD_DECONDA_PORTES_CHOC.CMD_DECONDA_PORTES_CHOC
        dra_CMD_DESACTIVE_SECU_ENFANT: data-element=rp_CMD_DESACTIVE_SECU_ENFANT.CMD_DESACTIVE_SECU_ENFANT
        dra_CMD_DESUPERCONDA_PORTES: data-element=rp_CMD_DESUPERCONDA_PORTES.CMD_DESUPERCONDA_PORTES
        dra_CMD_REBOND_PORTE_COND: data-element=rp_CMD_REBOND_PORTE_COND.CMD_REBOND_PORTE_COND
        dra_CMD_REBOND_PORTES: data-element=rp_CMD_REBOND_PORTES.CMD_REBOND_PORTES
        dra_Out14: data-element=rp_CMD_SUPERCONDA_PORTES.Out14
        dra_ETAT_CONDA: data-element=rp_ETAT_CONDA.ETAT_CONDA
        dra_Y: data-element=rp_ETAT_SECURITE_ENFANT.Y
      7 x data write access:
        dwa_Y: data-element=pp_ACTION_SERRURES_EN_COURS.Y
        dwa_CMD_SERR_MOT_COMMUN: data-element=pp_CMD_SERR_MOT_COMMUN.CMD_SERR_MOT_COMMUN
        dwa_CMD_SERR_MOT_EXT: data-element=pp_CMD_SERR_MOT_EXT.CMD_SERR_MOT_EXT
        dwa_CMD_SERR_MOT_EXT_SELECT: data-element=pp_CMD_SERR_MOT_EXT_SELECT.CMD_SERR_MOT_EXT_SELECT
        dwa_CMD_SERR_MOT_INT_AR: data-element=pp_CMD_SERR_MOT_INT_AR.CMD_SERR_MOT_INT_AR
        dwa_CMD_SERR_MOT_INT_AV: data-element=pp_CMD_SERR_MOT_INT_AV.CMD_SERR_MOT_INT_AV
        dwa_PROTECTION_THERMIQUE: data-element=pp_PROTECTION_THERMIQUE.PROTECTION_THERMIQUE
  4 x sender receiver interface:
    sri_CMD_SERR_MOT_EXT
      data CMD_SERR_MOT_EXT: type=AR_GAV_SWC/Boolean
    sri_CMD_SERR_MOT_EXT_SELECT
      data CMD_SERR_MOT_EXT_SELECT: type=AR_GAV_SWC/Boolean
    sri_CMD_SERR_MOT_INT_AR
      data CMD_SERR_MOT_INT_AR: type=AR_GAV_SWC/Boolean
    sri_CMD_SERR_MOT_INT_AV
      data CMD_SERR_MOT_INT_AV: type=AR_GAV_SWC/Boolean
  swc implementation implem_PILOTER_SER: programming-language=C, behavior=ib_PILOTER_SER
    code-descriptors:
      code implem_PILOTER_SER: type=SRC
        xfile PILOTER_SER.c: url=Src_C/PILOTER_SER.c
  application software component type TELECMD
    6 x require port:
      rp_ETAT_PRINCIP_SEV: unqueued-receiver-com-spec{data-element=sri_ETAT_PRINCIP_SEV/ETAT_PRINCIP_SEV, handle-invalid=KEEP, init-value=cst_UInt8_init/uint8_init, resync-time=0.0}, required-interface=AR_GAV_SWC/sri_ETAT_PRINCIP_SEV
      rp_UTILISATEUR_DS_HAB: unqueued-receiver-com-spec{data-element=UTILISATEUR_DS_HAB, handle-invalid=KEEP, init-value=cst_Boolean_init/boolean_init, resync-time=0.0}, required-interface=sri_UTILISATEUR_DS_HAB
      rp_NUM_IDENTIFIANT_HF_TELECMD: unqueued-receiver-com-spec{data-element=NUM_IDENTIFIANT_HF_TELECMD, handle-invalid=KEEP, init-value=cst_UInt32_init/uint32_init, resync-time=0.0}, required-interface=sri_NUM_IDENTIFIANT_HF_TELECMD
      rp_NUM_BOUTON_APPUI_TELECMD: unqueued-receiver-com-spec{data-element=NUM_BOUTON_APPUI_TELECMD, handle-invalid=KEEP, init-value=cst_UInt8_init/uint8_init, resync-time=0.0}, required-interface=sri_NUM_BOUTON_APPUI_TELECMD
      rp_TYPE_APPUI_BOUTON_TELECMD: unqueued-receiver-com-spec{data-element=TYPE_APPUI_BOUTON_TELECMD, handle-invalid=KEEP, init-value=cst_Boolean_init/boolean_init, resync-time=0.0}, required-interface=sri_TYPE_APPUI_BOUTON_TELECMD
      rp_ETAT_CONDA: unqueued-receiver-com-spec{data-element=sri_ETAT_CONDA/ETAT_CONDA, handle-invalid=KEEP, init-value=cst_UInt8_init/uint8_init, resync-time=0.0}, required-interface=AR_GAV_SWC/sri_ETAT_CONDA
    5 x provide port:
      pp_AUTOR_FONCT_TELECMD: unqueued-sender-com-spec{data-element=AUTOR_FONCT_TELECMD, init-value=cst_Boolean_init/boolean_init}, provided-interface=sri_AUTOR_FONCT_TELECMD
      pp_DMD_LOCAL_TELECMD: unqueued-sender-com-spec{data-element=sri_DMD_LOCAL_TELECMD/DMD_LOCAL_TELECMD, init-value=cst_Boolean_init/boolean_init}, provided-interface=AR_GAV_SWC/sri_DMD_LOCAL_TELECMD
      pp_DMD_DECONDA_TELECMD: unqueued-sender-com-spec{data-element=DMD_DECONDA_TELECMD, init-value=cst_Boolean_init/boolean_init}, provided-interface=sri_DMD_DECONDA_TELECMD
      pp_DMD_CONDA_TELECMD: unqueued-sender-com-spec{data-element=DMD_CONDA_TELECMD, init-value=cst_Boolean_init/boolean_init}, provided-interface=sri_DMD_CONDA_TELECMD
      pp_DMD_SUPERCONDA_TELECMD: unqueued-sender-com-spec{data-element=DMD_SUPERCONDA_TELECMD, init-value=cst_Boolean_init/boolean_init}, provided-interface=sri_DMD_SUPERCONDA_TELECMD
  internal behavior ib_TELECMD: component=TELECMD
    timing event evt_TELECMD: start-on-event=TELECMD, period=0.1
    runnable TELECMD
      6 x data read access:
        dra_ETAT_PRINCIP_SEV: data-element=rp_ETAT_PRINCIP_SEV.ETAT_PRINCIP_SEV
        dra_UTILISATEUR_DS_HAB: data-element=rp_UTILISATEUR_DS_HAB.UTILISATEUR_DS_HAB
        dra_NUM_IDENTIFIANT_HF_TELECMD: data-element=rp_NUM_IDENTIFIANT_HF_TELECMD.NUM_IDENTIFIANT_HF_TELECMD
        dra_NUM_BOUTON_APPUI_TELECMD: data-element=rp_NUM_BOUTON_APPUI_TELECMD.NUM_BOUTON_APPUI_TELECMD
        dra_TYPE_APPUI_BOUTON_TELECMD: data-element=rp_TYPE_APPUI_BOUTON_TELECMD.TYPE_APPUI_BOUTON_TELECMD
        dra_ETAT_CONDA: data-element=rp_ETAT_CONDA.ETAT_CONDA
      5 x data write access:
        dwa_AUTOR_FONCT_TELECMD: data-element=pp_AUTOR_FONCT_TELECMD.AUTOR_FONCT_TELECMD
        dwa_DMD_LOCAL_TELECMD: data-element=pp_DMD_LOCAL_TELECMD.DMD_LOCAL_TELECMD
        dwa_DMD_DECONDA_TELECMD: data-element=pp_DMD_DECONDA_TELECMD.DMD_DECONDA_TELECMD
        dwa_DMD_CONDA_TELECMD: data-element=pp_DMD_CONDA_TELECMD.DMD_CONDA_TELECMD
        dwa_DMD_SUPERCONDA_TELECMD: data-element=pp_DMD_SUPERCONDA_TELECMD.DMD_SUPERCONDA_TELECMD
  sender receiver interface sri_NUM_IDENTIFIANT_HF_TELECMD
    data NUM_IDENTIFIANT_HF_TELECMD: type=AR_GAV_SWC/UInt32
  constant specification cst_UInt32_init
    value:
      integer literal uint32_init: type=AR_GAV_SWC/UInt32, value=0
  4 x sender receiver interface:
    sri_NUM_BOUTON_APPUI_TELECMD
      data NUM_BOUTON_APPUI_TELECMD: type=AR_GAV_SWC/UInt8
    sri_TYPE_APPUI_BOUTON_TELECMD
      data TYPE_APPUI_BOUTON_TELECMD: type=AR_GAV_SWC/Boolean
    sri_AUTOR_FONCT_TELECMD
      data AUTOR_FONCT_TELECMD: type=AR_GAV_SWC/Boolean
    sri_DMD_LOCAL_TELECMD
      data DMD_LOCAL_TELECMD: type=AR_GAV_SWC/Boolean
  swc implementation implem_TELECMD: programming-language=C, behavior=ib_TELECMD
    code-descriptors:
      code implem_TELECMD: type=SRC
        xfile TELECMD.c: url=Src_C/TELECMD.c
  application software component type PUSH
    require port rp_ETAT_PRINCIP_SEV: unqueued-receiver-com-spec{data-element=sri_ETAT_PRINCIP_SEV/ETAT_PRINCIP_SEV, handle-invalid=KEEP, init-value=cst_UInt8_init/uint8_init, resync-time=0.0}, required-interface=AR_GAV_SWC/sri_ETAT_PRINCIP_SEV
    require port rp_DMDP_GAV_VERR_CENTRALISE: unqueued-receiver-com-spec{data-element=DMDP_GAV_VERR_CENTRALISE, handle-invalid=KEEP, init-value=cst_Boolean_init/boolean_init, resync-time=0.0}, required-interface=sri_DMDP_GAV_VERR_CENTRALISE
    require port rp_DMDP_GAV_SECU_ENFANT: unqueued-receiver-com-spec{data-element=DMDP_GAV_SECU_ENFANT, handle-invalid=KEEP, init-value=cst_Boolean_init/boolean_init, resync-time=0.0}, required-interface=sri_DMDP_GAV_SECU_ENFANT
    provide port pp_DMD_PUSH_SECU_ENFANT: unqueued-sender-com-spec{data-element=DMD_PUSH_SECU_ENFANT, init-value=cst_Boolean_init/boolean_init}, provided-interface=sri_DMD_PUSH_SECU_ENFANT
    provide port pp_DMD_PUSH_CONDA_APPUI_COURT: unqueued-sender-com-spec{data-element=DMD_PUSH_CONDA_APPUI_COURT, init-value=cst_Boolean_init/boolean_init}, provided-interface=sri_DMD_PUSH_CONDA_APPUI_COURT
    provide port pp_DMD_PUSH_CONDA_APPUI_LONG: unqueued-sender-com-spec{data-element=DMD_PUSH_CONDA_APPUI_LONG, init-value=cst_Boolean_init/boolean_init}, provided-interface=sri_DMD_PUSH_CONDA_APPUI_LONG
  internal behavior ib_PUSH: component=PUSH
    timing event evt_PUSH: start-on-event=PUSH, period=0.1
    runnable PUSH
      data read access dra_ETAT_PRINCIP_SEV: data-element=rp_ETAT_PRINCIP_SEV.ETAT_PRINCIP_SEV
      data read access dra_DMDP_GAV_VERR_CENTRALISE: data-element=rp_DMDP_GAV_VERR_CENTRALISE.DMDP_GAV_VERR_CENTRALISE
      data read access dra_DMDP_GAV_SECU_ENFANT: data-element=rp_DMDP_GAV_SECU_ENFANT.DMDP_GAV_SECU_ENFANT
      data write access dwa_DMD_PUSH_SECU_ENFANT: data-element=pp_DMD_PUSH_SECU_ENFANT.DMD_PUSH_SECU_ENFANT
      data write access dwa_DMD_PUSH_CONDA_APPUI_COURT: data-element=pp_DMD_PUSH_CONDA_APPUI_COURT.DMD_PUSH_CONDA_APPUI_COURT
      data write access dwa_DMD_PUSH_CONDA_APPUI_LONG: data-element=pp_DMD_PUSH_CONDA_APPUI_LONG.DMD_PUSH_CONDA_APPUI_LONG
  swc implementation implem_PUSH: programming-language=C, behavior=ib_PUSH
    code-descriptors:
      code implem_PUSH: type=SRC
        xfile PUSH.c: url=Src_C/PUSH.c
package /AR_LPM_SWC
  application software component type GERER_PHASE_VIE_CAN_IS
    require port rp_ETAT_PRINCIP_SEV: unqueued-receiver-com-spec{data-element=sri_ETAT_PRINCIP_SEV/ETAT_PRINCIP_SEV, handle-invalid=KEEP, init-value=cst_UInt8_init/uint8_init, resync-time=0.0}, required-interface=AR_LPM_SWC/sri_ETAT_PRINCIP_SEV
    provide port pp_REVEIL_PRINCIPAL: unqueued-sender-com-spec{data-element=REVEIL_PRINCIPAL, init-value=cst_UInt8_init/uint8_init}, provided-interface=sri_REVEIL_PRINCIPAL
    provide port pp_CAN_IS_ACTIVITY: unqueued-sender-com-spec{data-element=CAN_IS_ACTIVITY, init-value=cst_Boolean_init/boolean_init}, provided-interface=sri_CAN_IS_ACTIVITY
  composition type MDL_LPM_BODY
    require port rp_ETAT_PRINCIP_SEV: unqueued-receiver-com-spec{data-element=sri_ETAT_PRINCIP_SEV/ETAT_PRINCIP_SEV, handle-invalid=KEEP, init-value=cst_UInt8_init/uint8_init, resync-time=0.0}, required-interface=AR_LPM_SWC/sri_ETAT_PRINCIP_SEV
    provide port pp_REVEIL_PRINCIPAL: unqueued-sender-com-spec{data-element=REVEIL_PRINCIPAL, init-value=cst_UInt8_init/uint8_init}, provided-interface=sri_REVEIL_PRINCIPAL
    provide port pp_CAN_IS_ACTIVITY: unqueued-sender-com-spec{data-element=CAN_IS_ACTIVITY, init-value=cst_Boolean_init/boolean_init}, provided-interface=sri_CAN_IS_ACTIVITY
    require port rp_ETAT_FEUX_DETRESSE: unqueued-receiver-com-spec{data-element=sri_ETAT_FEUX_DETRESSE/ETAT_FEUX_DETRESSE, handle-invalid=KEEP, init-value=cst_Boolean_init/boolean_init, resync-time=0.0}, required-interface=AR_LPM_SWC/sri_ETAT_FEUX_DETRESSE
    require port rp_ETAT_FEUX_POSITION: unqueued-receiver-com-spec{data-element=sri_ETAT_FEUX_POSITION/ETAT_FEUX_POSITION, handle-invalid=KEEP, init-value=cst_Boolean_init/boolean_init, resync-time=0.0}, required-interface=AR_LPM_SWC/sri_ETAT_FEUX_POSITION
    provide port pp_CAN_BODY_ACTIVITY: unqueued-sender-com-spec{data-element=CAN_BODY_ACTIVITY, init-value=cst_Boolean_init/boolean_init}, provided-interface=sri_CAN_BODY_ACTIVITY
    provide port pp_PHASE_VIE: unqueued-sender-com-spec{data-element=sri_PHASE_VIE/PHASE_VIE, init-value=cst_UInt8_init/uint8_init}, provided-interface=AR_LPM_SWC/sri_PHASE_VIE
    provide port pp_ON_CMB: unqueued-sender-com-spec{data-element=ON_CMB, init-value=cst_Boolean_init/boolean_init}, provided-interface=sri_ON_CMB
    require port rp_CDE_APC: unqueued-receiver-com-spec{data-element=sri_CDE_APC/CDE_APC, handle-invalid=KEEP, init-value=cst_Boolean_init/boolean_init, resync-time=0.0}, required-interface=AR_LPM_SWC/sri_CDE_APC
    require port rp_ETAT_FEUX_DIURNES: unqueued-receiver-com-spec{data-element=sri_ETAT_FEUX_DIURNES/ETAT_FEUX_DIURNES, handle-invalid=KEEP, init-value=cst_Boolean_init/boolean_init, resync-time=0.0}, required-interface=AR_LPM_SWC/sri_ETAT_FEUX_DIURNES
    require port rp_CMD_AVER_SONORE: unqueued-receiver-com-spec{data-element=sri_CMD_AVER_SONORE/CMD_AVER_SONORE, handle-invalid=KEEP, init-value=cst_Boolean_init/boolean_init, resync-time=0.0}, required-interface=AR_LPM_SWC/sri_CMD_AVER_SONORE
    provide port pp_CAN_BACKBONE_ACTIVITY: unqueued-sender-com-spec{data-element=sri_CAN_BACKBONE_ACTIVITY/CAN_BACKBONE_ACTIVITY, init-value=cst_Boolean_init/boolean_init}, provided-interface=AR_LPM_SWC/sri_CAN_BACKBONE_ACTIVITY
    4 x require port:
      rp_E_HF: unqueued-receiver-com-spec{data-element=E_HF, handle-invalid=KEEP, init-value=cst_Boolean_init/boolean_init, resync-time=0.0}, required-interface=sri_E_HF
      rp_E_FEUX_POS: unqueued-receiver-com-spec{data-element=E_FEUX_POS, handle-invalid=KEEP, init-value=cst_Boolean_init/boolean_init, resync-time=0.0}, required-interface=sri_E_FEUX_POS
      rp_E_AVERTISSEUR: unqueued-receiver-com-spec{data-element=E_AVERTISSEUR, handle-invalid=KEEP, init-value=cst_Boolean_init/boolean_init, resync-time=0.0}, required-interface=sri_E_AVERTISSEUR
      rp_E_PHARE: unqueued-receiver-com-spec{data-element=E_PHARE, handle-invalid=KEEP, init-value=cst_Boolean_init/boolean_init, resync-time=0.0}, required-interface=sri_E_PHARE
    provide port pp_ECU_ACTIVITY: unqueued-sender-com-spec{data-element=ECU_ACTIVITY, init-value=cst_Boolean_init/boolean_init}, provided-interface=sri_ECU_ACTIVITY
    4 x component:
      GERER_PHASE_VIE_CAN_IS: type=GERER_PHASE_VIE_CAN_IS
      GERER_PHASE_VIE_CAN_BODY: type=GERER_PHASE_VIE_CAN_BODY
      GERER_PHASE_VIE_CAN_BACKBONE: type=GERER_PHASE_VIE_CAN_BACKBONE
      GERER_MAINTIEN_ECU: type=GERER_MAINTIEN_ECU
    connect GERER_PHASE_VIE_CAN_IS.pp_CAN_IS_ACTIVITY -> GERER_MAINTIEN_ECU.rp_CAN_IS_ACTIVITY
    connect GERER_PHASE_VIE_CAN_BODY.pp_CAN_BODY_ACTIVITY -> GERER_MAINTIEN_ECU.rp_CAN_BODY_ACTIVITY
    connect GERER_PHASE_VIE_CAN_BACKBONE.pp_CAN_BACKBONE_ACTIVITY -> GERER_MAINTIEN_ECU.rp_CAN_BACKBONE_ACTIVITY
    delegate GERER_PHASE_VIE_CAN_IS.rp_ETAT_PRINCIP_SEV <-> outer port MDL_LPM_BODY/rp_ETAT_PRINCIP_SEV
    delegate GERER_PHASE_VIE_CAN_IS.pp_REVEIL_PRINCIPAL <-> outer port MDL_LPM_BODY/pp_REVEIL_PRINCIPAL
    delegate GERER_PHASE_VIE_CAN_IS.pp_CAN_IS_ACTIVITY <-> outer port MDL_LPM_BODY/pp_CAN_IS_ACTIVITY
    delegate GERER_PHASE_VIE_CAN_BODY.rp_ETAT_PRINCIP_SEV <-> outer port MDL_LPM_BODY/rp_ETAT_PRINCIP_SEV
    delegate GERER_PHASE_VIE_CAN_BODY.rp_ETAT_FEUX_DETRESSE <-> outer port MDL_LPM_BODY/rp_ETAT_FEUX_DETRESSE
    delegate GERER_PHASE_VIE_CAN_BODY.rp_ETAT_FEUX_POSITION <-> outer port MDL_LPM_BODY/rp_ETAT_FEUX_POSITION
    delegate GERER_PHASE_VIE_CAN_BODY.pp_CAN_BODY_ACTIVITY <-> outer port MDL_LPM_BODY/pp_CAN_BODY_ACTIVITY
    delegate GERER_PHASE_VIE_CAN_BODY.pp_PHASE_VIE <-> outer port MDL_LPM_BODY/pp_PHASE_VIE
    delegate GERER_PHASE_VIE_CAN_BODY.pp_ON_CMB <-> outer port MDL_LPM_BODY/pp_ON_CMB
    delegate GERER_PHASE_VIE_CAN_BACKBONE.rp_ETAT_PRINCIP_SEV <-> outer port MDL_LPM_BODY/rp_ETAT_PRINCIP_SEV
    delegate GERER_PHASE_VIE_CAN_BACKBONE.rp_ETAT_FEUX_POSITION <-> outer port MDL_LPM_BODY/rp_ETAT_FEUX_POSITION
    delegate GERER_PHASE_VIE_CAN_BACKBONE.rp_CDE_APC <-> outer port MDL_LPM_BODY/rp_CDE_APC
    delegate GERER_PHASE_VIE_CAN_BACKBONE.rp_ETAT_FEUX_DIURNES <-> outer port MDL_LPM_BODY/rp_ETAT_FEUX_DIURNES
    delegate GERER_PHASE_VIE_CAN_BACKBONE.rp_CMD_AVER_SONORE <-> outer port MDL_LPM_BODY/rp_CMD_AVER_SONORE
    delegate GERER_PHASE_VIE_CAN_BACKBONE.pp_CAN_BACKBONE_ACTIVITY <-> outer port MDL_LPM_BODY/pp_CAN_BACKBONE_ACTIVITY
    delegate GERER_MAINTIEN_ECU.rp_MAINTIEN_ECU <-> outer port MDL_LPM_BODY/rp_ETAT_FEUX_DETRESSE
    delegate GERER_MAINTIEN_ECU.rp_E_HF <-> outer port MDL_LPM_BODY/rp_E_HF
    delegate GERER_MAINTIEN_ECU.rp_E_FEUX_POS <-> outer port MDL_LPM_BODY/rp_E_FEUX_POS
    delegate GERER_MAINTIEN_ECU.rp_E_AVERTISSEUR <-> outer port MDL_LPM_BODY/rp_E_AVERTISSEUR
    delegate GERER_MAINTIEN_ECU.rp_E_PHARE <-> outer port MDL_LPM_BODY/rp_E_PHARE
    delegate GERER_MAINTIEN_ECU.pp_ECU_ACTIVITY <-> outer port MDL_LPM_BODY/pp_ECU_ACTIVITY
  composition type LPM
    5 x require port:
      rp_ETAT_FEUX_DETRESSE: unqueued-receiver-com-spec{data-element=sri_ETAT_FEUX_DETRESSE/ETAT_FEUX_DETRESSE, handle-invalid=KEEP, init-value=cst_Boolean_init/boolean_init, resync-time=0.0}, required-interface=AR_LPM_SWC/sri_ETAT_FEUX_DETRESSE
      rp_ETAT_FEUX_DIURNES: unqueued-receiver-com-spec{data-element=sri_ETAT_FEUX_DIURNES/ETAT_FEUX_DIURNES, handle-invalid=KEEP, init-value=cst_Boolean_init/boolean_init, resync-time=0.0}, required-interface=AR_LPM_SWC/sri_ETAT_FEUX_DIURNES
      rp_ETAT_FEUX_POSITION: unqueued-receiver-com-spec{data-element=sri_ETAT_FEUX_POSITION/ETAT_FEUX_POSITION, handle-invalid=KEEP, init-value=cst_Boolean_init/boolean_init, resync-time=0.0}, required-interface=AR_LPM_SWC/sri_ETAT_FEUX_POSITION
      rp_CMD_AVER_SONORE: unqueued-receiver-com-spec{data-element=sri_CMD_AVER_SONORE/CMD_AVER_SONORE, handle-invalid=KEEP, init-value=cst_Boolean_init/boolean_init, resync-time=0.0}, required-interface=AR_LPM_SWC/sri_CMD_AVER_SONORE
      rp_ETAT_PRINCIP_SEV: unqueued-receiver-com-spec{data-element=sri_ETAT_PRINCIP_SEV/ETAT_PRINCIP_SEV, handle-invalid=KEEP, init-value=cst_UInt8_init/uint8_init, resync-time=0.0}, required-interface=AR_LPM_SWC/sri_ETAT_PRINCIP_SEV
    5 x provide port:
      pp_REVEIL_PRINCIPAL: unqueued-sender-com-spec{data-element=REVEIL_PRINCIPAL, init-value=cst_UInt8_init/uint8_init}, provided-interface=sri_REVEIL_PRINCIPAL
      pp_CAN_IS_ACTIVITY: unqueued-sender-com-spec{data-element=CAN_IS_ACTIVITY, init-value=cst_Boolean_init/boolean_init}, provided-interface=sri_CAN_IS_ACTIVITY
      pp_CAN_BODY_ACTIVITY: unqueued-sender-com-spec{data-element=CAN_BODY_ACTIVITY, init-value=cst_Boolean_init/boolean_init}, provided-interface=sri_CAN_BODY_ACTIVITY
      pp_PHASE_VIE: unqueued-sender-com-spec{data-element=sri_PHASE_VIE/PHASE_VIE, init-value=cst_UInt8_init/uint8_init}, provided-interface=AR_LPM_SWC/sri_PHASE_VIE
      pp_ON_CMB: unqueued-sender-com-spec{data-element=ON_CMB, init-value=cst_Boolean_init/boolean_init}, provided-interface=sri_ON_CMB
    require port rp_CDE_APC: unqueued-receiver-com-spec{data-element=sri_CDE_APC/CDE_APC, handle-invalid=KEEP, init-value=cst_Boolean_init/boolean_init, resync-time=0.0}, required-interface=AR_LPM_SWC/sri_CDE_APC
    provide port pp_CAN_BACKBONE_ACTIVITY: unqueued-sender-com-spec{data-element=sri_CAN_BACKBONE_ACTIVITY/CAN_BACKBONE_ACTIVITY, init-value=cst_Boolean_init/boolean_init}, provided-interface=AR_LPM_SWC/sri_CAN_BACKBONE_ACTIVITY
    4 x require port:
      rp_E_HF: unqueued-receiver-com-spec{data-element=E_HF, handle-invalid=KEEP, init-value=cst_Boolean_init/boolean_init, resync-time=0.0}, required-interface=sri_E_HF
      rp_E_FEUX_POS: unqueued-receiver-com-spec{data-element=E_FEUX_POS, handle-invalid=KEEP, init-value=cst_Boolean_init/boolean_init, resync-time=0.0}, required-interface=sri_E_FEUX_POS
      rp_E_AVERTISSEUR: unqueued-receiver-com-spec{data-element=E_AVERTISSEUR, handle-invalid=KEEP, init-value=cst_Boolean_init/boolean_init, resync-time=0.0}, required-interface=sri_E_AVERTISSEUR
      rp_E_PHARE: unqueued-receiver-com-spec{data-element=E_PHARE, handle-invalid=KEEP, init-value=cst_Boolean_init/boolean_init, resync-time=0.0}, required-interface=sri_E_PHARE
    provide port pp_ECU_ACTIVITY: unqueued-sender-com-spec{data-element=ECU_ACTIVITY, init-value=cst_Boolean_init/boolean_init}, provided-interface=sri_ECU_ACTIVITY
    component MDL_LPM_BODY: type=MDL_LPM_BODY
    delegate MDL_LPM_BODY.rp_ETAT_PRINCIP_SEV <-> outer port LPM/rp_ETAT_PRINCIP_SEV
    delegate MDL_LPM_BODY.pp_REVEIL_PRINCIPAL <-> outer port LPM/pp_REVEIL_PRINCIPAL
    delegate MDL_LPM_BODY.pp_CAN_IS_ACTIVITY <-> outer port LPM/pp_CAN_IS_ACTIVITY
    delegate MDL_LPM_BODY.rp_ETAT_FEUX_DETRESSE <-> outer port LPM/rp_ETAT_FEUX_DETRESSE
    delegate MDL_LPM_BODY.rp_ETAT_FEUX_POSITION <-> outer port LPM/rp_ETAT_FEUX_POSITION
    delegate MDL_LPM_BODY.pp_CAN_BODY_ACTIVITY <-> outer port LPM/pp_CAN_BODY_ACTIVITY
    delegate MDL_LPM_BODY.pp_PHASE_VIE <-> outer port LPM/pp_PHASE_VIE
    delegate MDL_LPM_BODY.pp_ON_CMB <-> outer port LPM/pp_ON_CMB
    delegate MDL_LPM_BODY.rp_CDE_APC <-> outer port LPM/rp_CDE_APC
    delegate MDL_LPM_BODY.rp_ETAT_FEUX_DIURNES <-> outer port LPM/rp_ETAT_FEUX_DIURNES
    delegate MDL_LPM_BODY.rp_CMD_AVER_SONORE <-> outer port LPM/rp_CMD_AVER_SONORE
    delegate MDL_LPM_BODY.pp_CAN_BACKBONE_ACTIVITY <-> outer port LPM/pp_CAN_BACKBONE_ACTIVITY
    delegate MDL_LPM_BODY.rp_E_HF <-> outer port LPM/rp_E_HF
    delegate MDL_LPM_BODY.rp_E_FEUX_POS <-> outer port LPM/rp_E_FEUX_POS
    delegate MDL_LPM_BODY.rp_E_AVERTISSEUR <-> outer port LPM/rp_E_AVERTISSEUR
    delegate MDL_LPM_BODY.rp_E_PHARE <-> outer port LPM/rp_E_PHARE
    delegate MDL_LPM_BODY.pp_ECU_ACTIVITY <-> outer port LPM/pp_ECU_ACTIVITY
  internal behavior ib_GERER_PHASE_VIE_CAN_IS: component=GERER_PHASE_VIE_CAN_IS
    timing event evt_GERER_PHASE_VIE_CAN_IS: start-on-event=GERER_PHASE_VIE_CAN_IS, period=0.1
    runnable GERER_PHASE_VIE_CAN_IS
      data read access dra_ETAT_PRINCIP_SEV: data-element=rp_ETAT_PRINCIP_SEV.ETAT_PRINCIP_SEV
      data write access dwa_REVEIL_PRINCIPAL: data-element=pp_REVEIL_PRINCIPAL.REVEIL_PRINCIPAL
      data write access dwa_CAN_IS_ACTIVITY: data-element=pp_CAN_IS_ACTIVITY.CAN_IS_ACTIVITY
  sender receiver interface sri_ETAT_PRINCIP_SEV
    data ETAT_PRINCIP_SEV: type=AR_LPM_SWC/UInt8
  constant specification cst_UInt8_init
    value:
      integer literal uint8_init: type=AR_LPM_SWC/UInt8, value=0
  sender receiver interface sri_REVEIL_PRINCIPAL
    data REVEIL_PRINCIPAL: type=AR_LPM_SWC/UInt8
  sender receiver interface sri_CAN_IS_ACTIVITY
    data CAN_IS_ACTIVITY: type=AR_LPM_SWC/Boolean
  constant specification cst_Boolean_init
    value:
      boolean literal boolean_init: type=AR_LPM_SWC/Boolean, value=false
  swc implementation implem_GERER_PHASE_VIE_CAN_IS: programming-language=C, behavior=ib_GERER_PHASE_VIE_CAN_IS
    code-descriptors:
      code implem_GERER_PHASE_VIE_CAN_IS: type=SRC
        xfile GERER_PHASE_VIE_CAN_IS.c: url=Src_C/GERER_PHASE_VIE_CAN_IS.c
  application software component type GERER_PHASE_VIE_CAN_BODY
    require port rp_ETAT_PRINCIP_SEV: unqueued-receiver-com-spec{data-element=sri_ETAT_PRINCIP_SEV/ETAT_PRINCIP_SEV, handle-invalid=KEEP, init-value=cst_UInt8_init/uint8_init, resync-time=0.0}, required-interface=AR_LPM_SWC/sri_ETAT_PRINCIP_SEV
    require port rp_ETAT_FEUX_DETRESSE: unqueued-receiver-com-spec{data-element=sri_ETAT_FEUX_DETRESSE/ETAT_FEUX_DETRESSE, handle-invalid=KEEP, init-value=cst_Boolean_init/boolean_init, resync-time=0.0}, required-interface=AR_LPM_SWC/sri_ETAT_FEUX_DETRESSE
    require port rp_ETAT_FEUX_POSITION: unqueued-receiver-com-spec{data-element=sri_ETAT_FEUX_POSITION/ETAT_FEUX_POSITION, handle-invalid=KEEP, init-value=cst_Boolean_init/boolean_init, resync-time=0.0}, required-interface=AR_LPM_SWC/sri_ETAT_FEUX_POSITION
    provide port pp_CAN_BODY_ACTIVITY: unqueued-sender-com-spec{data-element=CAN_BODY_ACTIVITY, init-value=cst_Boolean_init/boolean_init}, provided-interface=sri_CAN_BODY_ACTIVITY
    provide port pp_PHASE_VIE: unqueued-sender-com-spec{data-element=sri_PHASE_VIE/PHASE_VIE, init-value=cst_UInt8_init/uint8_init}, provided-interface=AR_LPM_SWC/sri_PHASE_VIE
    provide port pp_ON_CMB: unqueued-sender-com-spec{data-element=ON_CMB, init-value=cst_Boolean_init/boolean_init}, provided-interface=sri_ON_CMB
  internal behavior ib_GERER_PHASE_VIE_CAN_BODY: component=GERER_PHASE_VIE_CAN_BODY
    timing event evt_GERER_PHASE_VIE_CAN_BODY: start-on-event=GERER_PHASE_VIE_CAN_BODY, period=0.1
    runnable GERER_PHASE_VIE_CAN_BODY
      data read access dra_ETAT_PRINCIP_SEV: data-element=rp_ETAT_PRINCIP_SEV.ETAT_PRINCIP_SEV
      data read access dra_ETAT_FEUX_DETRESSE: data-element=rp_ETAT_FEUX_DETRESSE.ETAT_FEUX_DETRESSE
      data read access dra_ETAT_FEUX_POSITION: data-element=rp_ETAT_FEUX_POSITION.ETAT_FEUX_POSITION
      data write access dwa_CAN_BODY_ACTIVITY: data-element=pp_CAN_BODY_ACTIVITY.CAN_BODY_ACTIVITY
      data write access dwa_PHASE_VIE: data-element=pp_PHASE_VIE.PHASE_VIE
      data write access dwa_ON_CMB: data-element=pp_ON_CMB.ON_CMB
  5 x sender receiver interface:
    sri_ETAT_FEUX_DETRESSE
      data ETAT_FEUX_DETRESSE: type=AR_LPM_SWC/Boolean
    sri_ETAT_FEUX_POSITION
      data ETAT_FEUX_POSITION: type=AR_LPM_SWC/Boolean
    sri_CAN_BODY_ACTIVITY
      data CAN_BODY_ACTIVITY: type=AR_LPM_SWC/Boolean
    sri_PHASE_VIE
      data PHASE_VIE: type=AR_LPM_SWC/UInt8
    sri_ON_CMB
      data ON_CMB: type=AR_LPM_SWC/Boolean
  swc implementation implem_GERER_PHASE_VIE_CAN_BODY: programming-language=C, behavior=ib_GERER_PHASE_VIE_CAN_BODY
    code-descriptors:
      code implem_GERER_PHASE_VIE_CAN_BODY: type=SRC
        xfile GERER_PHASE_VIE_CAN_BODY.c: url=Src_C/GERER_PHASE_VIE_CAN_BODY.c
  sender receiver interface sri_CAN_BACKBONE_ACTIVITY
    data CAN_BACKBONE_ACTIVITY: type=AR_LPM_SWC/Boolean
  sender receiver interface sri_ECU_ACTIVITY
    data ECU_ACTIVITY: type=AR_LPM_SWC/Boolean
  application software component type GERER_PHASE_VIE_CAN_BACKBONE
    5 x require port:
      rp_ETAT_PRINCIP_SEV: unqueued-receiver-com-spec{data-element=sri_ETAT_PRINCIP_SEV/ETAT_PRINCIP_SEV, handle-invalid=KEEP, init-value=cst_UInt8_init/uint8_init, resync-time=0.0}, required-interface=AR_LPM_SWC/sri_ETAT_PRINCIP_SEV
      rp_ETAT_FEUX_POSITION: unqueued-receiver-com-spec{data-element=sri_ETAT_FEUX_POSITION/ETAT_FEUX_POSITION, handle-invalid=KEEP, init-value=cst_Boolean_init/boolean_init, resync-time=0.0}, required-interface=AR_LPM_SWC/sri_ETAT_FEUX_POSITION
      rp_ETAT_FEUX_DIURNES: unqueued-receiver-com-spec{data-element=sri_ETAT_FEUX_DIURNES/ETAT_FEUX_DIURNES, handle-invalid=KEEP, init-value=cst_Boolean_init/boolean_init, resync-time=0.0}, required-interface=AR_LPM_SWC/sri_ETAT_FEUX_DIURNES
      rp_CMD_AVER_SONORE: unqueued-receiver-com-spec{data-element=sri_CMD_AVER_SONORE/CMD_AVER_SONORE, handle-invalid=KEEP, init-value=cst_Boolean_init/boolean_init, resync-time=0.0}, required-interface=AR_LPM_SWC/sri_CMD_AVER_SONORE
      rp_CDE_APC: unqueued-receiver-com-spec{data-element=sri_CDE_APC/CDE_APC, handle-invalid=KEEP, init-value=cst_Boolean_init/boolean_init, resync-time=0.0}, required-interface=AR_LPM_SWC/sri_CDE_APC
    provide port pp_CAN_BACKBONE_ACTIVITY: unqueued-sender-com-spec{data-element=sri_CAN_BACKBONE_ACTIVITY/CAN_BACKBONE_ACTIVITY, init-value=cst_Boolean_init/boolean_init}, provided-interface=AR_LPM_SWC/sri_CAN_BACKBONE_ACTIVITY
  internal behavior ib_GERER_PHASE_VIE_CAN_BACKBONE: component=GERER_PHASE_VIE_CAN_BACKBONE
    timing event evt_GERER_PHASE_VIE_CAN_BACKBONE: start-on-event=GERER_PHASE_VIE_CAN_BACKBONE, period=0.1
    runnable GERER_PHASE_VIE_CAN_BACKBONE
      5 x data read access:
        dra_ETAT_PRINCIP_SEV: data-element=rp_ETAT_PRINCIP_SEV.ETAT_PRINCIP_SEV
        dra_ETAT_FEUX_POSITION: data-element=rp_ETAT_FEUX_POSITION.ETAT_FEUX_POSITION
        dra_ETAT_FEUX_DIURNES: data-element=rp_ETAT_FEUX_DIURNES.ETAT_FEUX_DIURNES
        dra_CMD_AVER_SONORE: data-element=rp_CMD_AVER_SONORE.CMD_AVER_SONORE
        dra_CDE_APC: data-element=rp_CDE_APC.CDE_APC
      data write access dwa_CAN_BACKBONE_ACTIVITY: data-element=pp_CAN_BACKBONE_ACTIVITY.CAN_BACKBONE_ACTIVITY
  sender receiver interface sri_ETAT_FEUX_DIURNES
    data ETAT_FEUX_DIURNES: type=AR_LPM_SWC/Boolean
  sender receiver interface sri_CMD_AVER_SONORE
    data CMD_AVER_SONORE: type=AR_LPM_SWC/Boolean
  sender receiver interface sri_CDE_APC
    data CDE_APC: type=AR_LPM_SWC/Boolean
  swc implementation implem_GERER_PHASE_VIE_CAN_BACK: programming-language=C, behavior=ib_GERER_PHASE_VIE_CAN_BACKBONE
    code-descriptors:
      code implem_GERER_PHASE_VIE_CAN_BACK: type=SRC
        xfile GERER_PHASE_VIE_CAN_BACKBONE.c: url=Src_C/GERER_PHASE_VIE_CAN_BACKBONE.c
  application software component type GERER_MAINTIEN_ECU
    8 x require port:
      rp_MAINTIEN_ECU: unqueued-receiver-com-spec{data-element=sri_ETAT_FEUX_DETRESSE/ETAT_FEUX_DETRESSE, handle-invalid=KEEP, init-value=cst_Boolean_init/boolean_init, resync-time=0.0}, required-interface=AR_LPM_SWC/sri_ETAT_FEUX_DETRESSE
      rp_CAN_BACKBONE_ACTIVITY: unqueued-receiver-com-spec{data-element=sri_CAN_BACKBONE_ACTIVITY/CAN_BACKBONE_ACTIVITY, handle-invalid=KEEP, init-value=cst_Boolean_init/boolean_init, resync-time=0.0}, required-interface=AR_LPM_SWC/sri_CAN_BACKBONE_ACTIVITY
      rp_CAN_BODY_ACTIVITY: unqueued-receiver-com-spec{data-element=CAN_BODY_ACTIVITY, handle-invalid=KEEP, init-value=cst_Boolean_init/boolean_init, resync-time=0.0}, required-interface=sri_CAN_BODY_ACTIVITY
      rp_CAN_IS_ACTIVITY: unqueued-receiver-com-spec{data-element=CAN_IS_ACTIVITY, handle-invalid=KEEP, init-value=cst_Boolean_init/boolean_init, resync-time=0.0}, required-interface=sri_CAN_IS_ACTIVITY
      rp_E_HF: unqueued-receiver-com-spec{data-element=E_HF, handle-invalid=KEEP, init-value=cst_Boolean_init/boolean_init, resync-time=0.0}, required-interface=sri_E_HF
      rp_E_FEUX_POS: unqueued-receiver-com-spec{data-element=E_FEUX_POS, handle-invalid=KEEP, init-value=cst_Boolean_init/boolean_init, resync-time=0.0}, required-interface=sri_E_FEUX_POS
      rp_E_AVERTISSEUR: unqueued-receiver-com-spec{data-element=E_AVERTISSEUR, handle-invalid=KEEP, init-value=cst_Boolean_init/boolean_init, resync-time=0.0}, required-interface=sri_E_AVERTISSEUR
      rp_E_PHARE: unqueued-receiver-com-spec{data-element=E_PHARE, handle-invalid=KEEP, init-value=cst_Boolean_init/boolean_init, resync-time=0.0}, required-interface=sri_E_PHARE
    provide port pp_ECU_ACTIVITY: unqueued-sender-com-spec{data-element=ECU_ACTIVITY, init-value=cst_Boolean_init/boolean_init}, provided-interface=sri_ECU_ACTIVITY
  internal behavior ib_GERER_MAINTIEN_ECU: component=GERER_MAINTIEN_ECU
    timing event evt_GERER_MAINTIEN_ECU: start-on-event=GERER_MAINTIEN_ECU, period=0.1
    runnable GERER_MAINTIEN_ECU
      8 x data read access:
        dra_ETAT_FEUX_DETRESSE: data-element=rp_MAINTIEN_ECU.ETAT_FEUX_DETRESSE
        dra_CAN_BACKBONE_ACTIVITY: data-element=rp_CAN_BACKBONE_ACTIVITY.CAN_BACKBONE_ACTIVITY
        dra_CAN_BODY_ACTIVITY: data-element=rp_CAN_BODY_ACTIVITY.CAN_BODY_ACTIVITY
        dra_CAN_IS_ACTIVITY: data-element=rp_CAN_IS_ACTIVITY.CAN_IS_ACTIVITY
        dra_E_HF: data-element=rp_E_HF.E_HF
        dra_E_FEUX_POS: data-element=rp_E_FEUX_POS.E_FEUX_POS
        dra_E_AVERTISSEUR: data-element=rp_E_AVERTISSEUR.E_AVERTISSEUR
        dra_E_PHARE: data-element=rp_E_PHARE.E_PHARE
      data write access dwa_ECU_ACTIVITY: data-element=pp_ECU_ACTIVITY.ECU_ACTIVITY
  4 x sender receiver interface:
    sri_E_HF
      data E_HF: type=AR_LPM_SWC/Boolean
    sri_E_FEUX_POS
      data E_FEUX_POS: type=AR_LPM_SWC/Boolean
    sri_E_AVERTISSEUR
      data E_AVERTISSEUR: type=AR_LPM_SWC/Boolean
    sri_E_PHARE
      data E_PHARE: type=AR_LPM_SWC/Boolean
  swc implementation implem_GERER_MAINTIEN_ECU: programming-language=C, behavior=ib_GERER_MAINTIEN_ECU
    code-descriptors:
      code implem_GERER_MAINTIEN_ECU: type=SRC
        xfile GERER_MAINTIEN_ECU.c: url=Src_C/GERER_MAINTIEN_ECU.c
package /AUTOSAR_LIB  # AUTOSAR_LIBRARIES
  service component type EcuM
    5 x provide port:
      SR000: provided-interface=EcuM_StateRequest
        provided-com-specs:
          operation=RequestRUN, queue-length=1
          operation=ReleaseRUN, queue-length=1
          operation=RequestPOSTRUN, queue-length=1
          operation=ReleasePOSTRUN, queue-length=1
      shutdownTarget: provided-interface=EcuM_ShutdownTarget
        provided-com-specs:
          operation=SelectShutdownTerget, queue-length=1
          operation=GetShutdownTarget, queue-length=1
          operation=GetlastShutdownTarget, queue-length=1
      applicationMode: provided-com-specs=[{operation=SelectApplicationMode, queue-length=1}, {operation=GetApplicationMode, queue-length=1}], provided-interface=EcuM_ApplicationMode
      bootTarget: provided-com-specs=[{operation=SelectBootTarget, queue-length=1}, {operation=GetBootTarget, queue-length=1}], provided-interface=EcuM_BootTarget
      currentMode: provided-interface=EcuM_CurrentMode
  internal behavior EcuStateManager_IB: component=EcuM
    11 x operation invoked event:
      RequestRUNoie: start-on-event=RequestRUN, operation=SR000.RequestRUN
      ReleaseRUNoie: start-on-event=ReleaseRUN, operation=SR000.ReleaseRUN
      RequestPOSTRUNoie: start-on-event=RequestPOSTRUN, operation=SR000.RequestPOSTRUN
      ReleasePOSTRUNoie: start-on-event=ReleasePOSTRUN, operation=SR000.ReleasePOSTRUN
      SelectShutdownTergetoie: start-on-event=SelectShutdownTarget, operation=shutdownTarget.SelectShutdownTerget
      GetShutdownTargetoie: start-on-event=GetShutdownTarget, operation=shutdownTarget.GetShutdownTarget
      GetlastShutdownTargetoie: start-on-event=GetLastShutdownTarget, operation=shutdownTarget.GetlastShutdownTarget
      SelectApplicationModeoie: start-on-event=SelectApplicationMode, operation=applicationMode.SelectApplicationMode
      GetApplicationModeoie: start-on-event=GetApplicationMode, operation=applicationMode.GetApplicationMode
      SelectBootTargetoie: start-on-event=SelectBootTarget, operation=bootTarget.SelectBootTarget
      GetBootTargetoie: start-on-event=GetBootTarget, operation=bootTarget.GetBootTarget
    11 x runnable, all with can-be-invoked-concurrently=true:
      RequestRUN: symbol=EcuM_RequestRUN
      ReleaseRUN: symbol=EcuM_ReleaseRUN
      RequestPOSTRUN: symbol=EcuM_RequestPOST_RUN
      ReleasePOSTRUN: symbol=EcuM_ReleasePOST_RUN
      SelectShutdownTarget: symbol=EcuM_SelectShutdownTarget
      GetShutdownTarget: symbol=EcuM_GetShutdownTarget
      GetLastShutdownTarget: symbol=EcuM_GetLastShutdownTarget
      SelectApplicationMode: symbol=EcuM_SelectApplicationMode
      GetApplicationMode: symbol=EcuM_GetApplicationMode
      SelectBootTarget: symbol=EcuM_SelectBootTarget
      GetBootTarget: symbol=EcuM_GetBootTarget
  client server interface EcuM_StateRequest: is-service=true
    4 x operation, all with possible-error=EcuM_StateRequest/E_NOT_OK:
      RequestRUN
        arg UserId: type=EcuM_UserType, direction=IN
      ReleaseRUN
        arg UserId: type=EcuM_UserType, direction=IN
      RequestPOSTRUN
        arg UserId: type=EcuM_UserType, direction=IN
      ReleasePOSTRUN
        arg UserId: type=EcuM_UserType, direction=IN
    error E_NOT_OK: error-code=1
  integer type EcuM_UserType: lower-limit=0, upper-limit=255
  client server interface EcuM_ShutdownTarget: is-service=true
    operation SelectShutdownTerget: possible-error=EcuM_ShutdownTarget/E_NOT_OK
      arg target: type=EcuM_StateType, direction=IN
      arg mode: type=AUTOSAR_LIB/UInt8, direction=IN
    operation GetShutdownTarget
      arg target: type=EcuM_StateType, direction=OUT
      arg mode: type=AUTOSAR_LIB/UInt8, direction=OUT
    operation GetlastShutdownTarget
      arg target: type=EcuM_StateType, direction=OUT
      arg mode: type=AUTOSAR_LIB/UInt8, direction=OUT
    error E_NOT_OK: error-code=1
  integer type EcuM_StateType: lower-limit=16, upper-limit=144
  client server interface EcuM_ApplicationMode: is-service=true
    operation SelectApplicationMode: possible-error=EcuM_ApplicationMode/E_NOT_OK
      arg appMode: type=AppModeType, direction=IN
    operation GetApplicationMode
      arg appMode: type=AppModeType, direction=OUT
    error E_NOT_OK: error-code=1
  integer type AppModeType: lower-limit=0, upper-limit=255
  client server interface EcuM_BootTarget: is-service=true
    operation SelectBootTarget: possible-error=EcuM_BootTarget/E_NOT_OK
      arg target: type=EcuM_BootTargetType, direction=IN
    operation GetBootTarget
      arg target: type=EcuM_BootTargetType, direction=OUT
    error E_NOT_OK: error-code=1
  integer type EcuM_BootTargetType: lower-limit=0, upper-limit=1
  swc implementation EcuStateManager_Impl: programming-language=C, behavior=EcuStateManager_IB
  service component type ComM
    6 x provide port:
      modeLimitation: provided-interface=ComM_ECUModeLimitation
        provided-com-specs:
          operation=LimitECUToNoComMode, queue-length=1
          operation=ReadInhibitCounter, queue-length=1
          operation=ResetUnhibitCounter, queue-length=1
          operation=SetECUGroupClassification, queue-length=1
      CL000: provided-com-specs=[{operation=LimitChannelToNoComMode, queue-length=1}, {operation=GetInhibitionStatus, queue-length=1}], provided-interface=ComM_ChannelLimitation
      CW000: server-com-spec{operation=PreventWakeUp, queue-length=1}, provided-interface=ComM_ChannelWakeup
      UR000: provided-interface=ComM_UserRequest
        provided-com-specs:
          operation=RequestComMode, queue-length=1
          operation=GetCurrentComMode, queue-length=1
          operation=GetRequestedMode, queue-length=1
          operation=GetMaxComMode, queue-length=1
      UM000: provided-interface=ComM_CurrentMode
      UR001: provided-interface=ComM_UserRequest
        provided-com-specs:
          operation=RequestComMode, queue-length=1
          operation=GetCurrentComMode, queue-length=1
          operation=GetRequestedMode, queue-length=1
          operation=GetMaxComMode, queue-length=1
  internal behavior ComManager_IB: component=ComM
    11 x operation invoked event:
      LimitECUToNoComModeoie: start-on-event=LimitECUToNoComMode, operation=modeLimitation.LimitECUToNoComMode
      ReadInhibitCounteroie: start-on-event=ReadInhibitCounter, operation=modeLimitation.ReadInhibitCounter
      ResetInhibitCounteroie: start-on-event=ResetInhibitCounter, operation=modeLimitation.ResetUnhibitCounter
      SetECUGroupClassificationoie: start-on-event=SetECUGroupClassification, operation=modeLimitation.SetECUGroupClassification
      LimitChannelToNoComModeoie: start-on-event=LimitChannelToNoComMode, operation=CL000.LimitChannelToNoComMode
      GetInhibitionStatusoie: start-on-event=GetInhibitionStatus, operation=CL000.GetInhibitionStatus
      PreventWakeupoie: start-on-event=PreventWakeup, operation=CW000.PreventWakeUp
      RequestComModeoie: start-on-event=RequestComMode, operation=UR000.RequestComMode
      GetMaxComModeoie: start-on-event=GetMaxComMode, operation=UR000.GetMaxComMode
      GetRequestedModeoie: start-on-event=GetRequestedMode, operation=UR000.GetRequestedMode
      GetCurrentComModeoie: start-on-event=GetCurrentComMode, operation=UR000.GetCurrentComMode
    port-api-options port-api-option={indirect-api=true, port=UM000}:
      port-api-option indirect-api=false, port=UR000:
        port-arg-values:
          integer literal user: type=AUTOSAR_LIB/UInt8, value=0
      port-api-option indirect-api=false, port=UR001:
        port-arg-values:
          integer literal user: type=uint8, value=1
    11 x runnable:
      LimitECUToNoComMode: symbol=ComM_LimitECUToNoComMode
      ReadInhibitCounter: symbol=ComM_ReadInhibitCounter
      ResetInhibitCounter: symbol=ComM_ResetInhibitCounter
      SetECUGroupClassification: symbol=ComM_SetECUGroupClassification
      LimitChannelToNoComMode: symbol=ComM_LimitChannelToNoComMode
      GetInhibitionStatus: symbol=ComM_GetInhibitionStatus
      PreventWakeup: symbol=ComM_PreventWakeup
      RequestComMode: can-be-invoked-concurrently=true, symbol=ComM_RequestComMode
      GetMaxComMode: can-be-invoked-concurrently=true, symbol=ComM_GetMaxComMode
      GetRequestedMode: can-be-invoked-concurrently=true, symbol=ComM_GetRequestedMode
      GetCurrentComMode: can-be-invoked-concurrently=true, symbol=ComM_GetCurrentComMode
  client server interface ComM_ECUModeLimitation: is-service=true
    4 x operation, all with possible-error=ComM_ECUModeLimitation/E_NOT_OK:
      LimitECUToNoComMode
        arg Status: type=AUTOSAR_LIB/Boolean, direction=IN
      ReadInhibitCounter
        arg CounterValue: type=AUTOSAR_LIB/UInt16, direction=OUT
      ResetUnhibitCounter
      SetECUGroupClassification
        arg Status: type=InhibitionStatusType, direction=IN
    error E_NOT_OK: error-code=1
  opaque type InhibitionStatusType: number-of-bits=3
  client server interface ComM_ChannelLimitation: is-service=true
    operation LimitChannelToNoComMode: possible-error=ComM_ChannelLimitation/E_NOT_OK
      arg Status: type=AUTOSAR_LIB/Boolean, direction=IN
    operation GetInhibitionStatus: possible-error=ComM_ChannelLimitation/E_NOT_OK
      arg Status: type=InhibitionStatusType, direction=OUT
    error E_NOT_OK: error-code=1
  client server interface ComM_ChannelWakeup: is-service=true
    operation PreventWakeUp: possible-error=ComM_ChannelWakeup/E_NOT_OK
      arg Status: type=AUTOSAR_LIB/Boolean, direction=IN
    error E_NOT_OK: error-code=1
  client server interface ComM_UserRequest: is-service=true
    4 x operation:
      RequestComMode: possible-error=[ComM_UserRequest/E_NOT_OK, E_MODE_LIMITATION]
        arg ComMode: type=ComM_ModeType, direction=IN
      GetCurrentComMode: possible-error=ComM_UserRequest/E_NOT_OK
        arg ComMode: type=ComM_ModeType, direction=OUT
      GetRequestedMode: possible-error=ComM_UserRequest/E_NOT_OK
        arg ComMode: type=ComM_ModeType, direction=OUT
      GetMaxComMode
        arg ComMode: type=ComM_ModeType, direction=OUT
    error E_NOT_OK: error-code=1
    error E_MODE_LIMITATION: error-code=2
  integer type ComM_ModeType: lower-limit=0, upper-limit=2
  sender receiver interface ComM_CurrentMode: is-service=true
    mode declaration group prototype currentMode: type=ComMMode
  mode declaration group ComMMode: initial-mode=NO_COMMUNICATION
    mode NO_COMMUNICATION
    mode SILENT_COMMUNICATION
    mode FULL_COMMUNICATION
  swc implementation ComManager_Impl: programming-language=C, behavior=ComManager_IB
  mode declaration group EcuM_Mode: initial-mode=STARTUP
    6 x mode:
      STARTUP
      RUN
      POST_RUN
      SLEEP
      WAKE_SLEEP
      SHUTDOWN
  sender receiver interface EcuM_CurrentMode: is-service=true
    mode declaration group prototype currentMode: type=EcuM_Mode
package /AR_BODY_IO_ASC
  sensor actuator software component type IO_ASC
    11 x require port:
      rp_P_LED_SIGN_PUSH_FEU_DET: unqueued-receiver-com-spec{data-element=P_LED_SIGN_PUSH_FEU_DET, handle-invalid=KEEP, init-value=cst_Boolean_init/boolean_init, resync-time=0.0}, required-interface=sri_P_LED_SIGN_PUSH_FEU_DET
      rp_CMD_SERR_MOT_COMMUN: unqueued-receiver-com-spec{data-element=CMD_SERR_MOT_COMMUN, handle-invalid=KEEP, init-value=cst_Boolean_init/boolean_init, resync-time=0.0}, required-interface=sri_CMD_SERR_MOT_COMMUN
      rp_CDE_LOGIC_ECM_FRONT: unqueued-receiver-com-spec{data-element=sri_CDE_LOGIC_ECM_FRONT/CDE_LOGIC_ECM_FRONT, handle-invalid=KEEP, init-value=boolean_v1, resync-time=0.0}, required-interface=AR_BODY_MODE_MANAGER_SWC/sri_CDE_LOGIC_ECM_FRONT
      rp_S_CDE_CPC_BODY_RELAY: unqueued-receiver-com-spec{data-element=CDE_SMART_ECM, handle-invalid=KEEP, init-value=boolean_v1, resync-time=0.0}, required-interface=sri_S_CDE_CPC_BODY_RELAY
      rp_CDE_PLUS_CAN: unqueued-receiver-com-spec{data-element=sri_CDE_PLUS_CAN/CDE_PLUS_CAN, handle-invalid=KEEP, init-value=boolean_v2, resync-time=0.0}, required-interface=AR_BODY_MODE_MANAGER_SWC/sri_CDE_PLUS_CAN
      rp_P_LED_GAV_ETAT_SECU_ENF: unqueued-receiver-com-spec{data-element=P_LED_GAV_ETAT_SECU_ENF, handle-invalid=KEEP, init-value=cst_Boolean_init/boolean_init, resync-time=0.0}, required-interface=sri_P_LED_GAV_ETAT_SECU_ENF
      rp_P_LED_GAV_ETAT_VERR_CENT: unqueued-receiver-com-spec{data-element=P_LED_GAV_ETAT_VERR_CENT, handle-invalid=KEEP, init-value=cst_Boolean_init/boolean_init, resync-time=0.0}, required-interface=sri_P_LED_GAV_ETAT_VERR_CENT
      rp_CMD_CLIGNO_ARG: unqueued-receiver-com-spec{data-element=CMD_CLIGNO_ARG, handle-invalid=KEEP, init-value=cst_Boolean_init/boolean_init, resync-time=0.0}, required-interface=sri_CMD_CLIGNO_ARG
      rp_CMD_CLIGNO_ARD: unqueued-receiver-com-spec{data-element=CMD_CLIGNO_ARD, handle-invalid=KEEP, init-value=cst_Boolean_init/boolean_init, resync-time=0.0}, required-interface=sri_CMD_CLIGNO_ARD
      rp_PILOTAGE_CLIGNO_AVG: unqueued-receiver-com-spec{data-element=PILOTAGE_CLIGNO_AVG, handle-invalid=KEEP, init-value=cst_Boolean_init/boolean_init, resync-time=0.0}, required-interface=sri_PILOTAGE_CLIGNO_AVG
      rp_PILOTAGE_CLIGNO_AVD: unqueued-receiver-com-spec{data-element=PILOTAGE_CLIGNO_AVD, handle-invalid=KEEP, init-value=cst_Boolean_init/boolean_init, resync-time=0.0}, required-interface=sri_PILOTAGE_CLIGNO_AVD
    13 x provide port:
      pp_E_APC: unqueued-sender-com-spec{data-element=E_APC, transmission-acknowledge=timeout=0.0, init-value=cst_UInt8_init/uint8_init}, provided-interface=sri_E_APC
      pp_INFO_CPO_ARG: unqueued-sender-com-spec{data-element=INFO_CPO_ARG, transmission-acknowledge=timeout=0.0, init-value=cst_Boolean_init/boolean_init}, provided-interface=sri_INFO_CPO_ARG
      pp_INFO_CPO_AVG: unqueued-sender-com-spec{data-element=INFO_CPO_AVG, transmission-acknowledge=timeout=0.0, init-value=cst_Boolean_init/boolean_init}, provided-interface=sri_INFO_CPO_AVG
      pp_INFO_CAV_AVG: unqueued-sender-com-spec{data-element=INFO_CAV_AVG, transmission-acknowledge=timeout=0.0, init-value=cst_Boolean_init/boolean_init}, provided-interface=sri_INFO_CAV_AVG
      pp_DMPD_GAV_SECU_ENFANT: unqueued-sender-com-spec{data-element=DMDP_GAV_SECU_ENFANT, transmission-acknowledge=timeout=0.0, init-value=cst_Boolean_init/boolean_init}, provided-interface=sri_DMDP_GAV_SECU_ENFANT
      pp_DMDP_GAV_VERR_CENTRALISE: unqueued-sender-com-spec{data-element=DMDP_GAV_VERR_CENTRALISE, transmission-acknowledge=timeout=0.0, init-value=cst_Boolean_init/boolean_init}, provided-interface=sri_DMDP_GAV_VERR_CENTRALISE
      pp_APPUI_PEDALE_FREIN: unqueued-sender-com-spec{data-element=APPUI_PEDALE_FREIN, transmission-acknowledge=timeout=0.0, init-value=cst_Boolean_init/boolean_init}, provided-interface=sri_APPUI_PEDALE_FREIN
      pp_U_BAT: unqueued-sender-com-spec{data-element=U_BAT, transmission-acknowledge=timeout=0.0, init-value=cst_UInt16_init/uint16_init}, provided-interface=sri_U_BAT
      pp_DMD_FEUX_DETRESSE: unqueued-sender-com-spec{data-element=DMD_FEUX_DETRESSE, transmission-acknowledge=timeout=0.0, init-value=cst_Boolean_init/boolean_init}, provided-interface=sri_DMD_FEUX_DETRESSE
      pp_DIAG_CLIGNO_AVD: unqueued-sender-com-spec{data-element=DIAG_CLIGNO_AVD, transmission-acknowledge=timeout=0.0, init-value=cst_UInt8_init/uint8_init}, provided-interface=sri_DIAG_CLIGNO_AVD
      pp_DIAG_CLIGNO_ARD: unqueued-sender-com-spec{data-element=DIAG_CLIGNO_ARD, transmission-acknowledge=timeout=0.0, init-value=cst_UInt8_init/uint8_init}, provided-interface=sri_DIAG_CLIGNO_ARD
      pp_DIAG_CLIGNO_AVG: unqueued-sender-com-spec{data-element=DIAG_CLIGNO_AVG, transmission-acknowledge=timeout=0.0, init-value=cst_UInt8_init/uint8_init}, provided-interface=sri_DIAG_CLIGNO_AVG
      pp_DIAG_CLIGNO_ARG: unqueued-sender-com-spec{data-element=DIAG_CLIGNO_ARG, transmission-acknowledge=timeout=0.0, init-value=cst_UInt8_init/uint8_init}, provided-interface=sri_DIAG_CLIGNO_ARG
    require port rp_IOHWAB: required-interface=cs_IOHWAB
  internal behavior IO_ASC_IB: component=IO_ASC
    timing event event: start-on-event=R_IO_ASC, period=0.05
    runnable R_IO_ASC
      11 x data read access:
        dra_P_LED_SIGN_PUSH_FEU_DET: data-element=rp_P_LED_SIGN_PUSH_FEU_DET.P_LED_SIGN_PUSH_FEU_DET
        dra_CMD_SERR_MOT_COMMUN: data-element=rp_CMD_SERR_MOT_COMMUN.CMD_SERR_MOT_COMMUN
        dra_CDE_LOGIC_ECM_FRONT: data-element=rp_CDE_LOGIC_ECM_FRONT.CDE_LOGIC_ECM_FRONT
        dra_CDE_SMART_ECM: data-element=rp_S_CDE_CPC_BODY_RELAY.CDE_SMART_ECM
        dra_CDE_PLUS_CAN: data-element=rp_CDE_PLUS_CAN.CDE_PLUS_CAN
        dra_P_LED_GAV_ETAT_SECU_ENF: data-element=rp_P_LED_GAV_ETAT_SECU_ENF.P_LED_GAV_ETAT_SECU_ENF
        dra_P_LED_GAV_ETAT_VERR_CENT: data-element=rp_P_LED_GAV_ETAT_VERR_CENT.P_LED_GAV_ETAT_VERR_CENT
        dra_CMD_CLIGNO_ARG: data-element=rp_CMD_CLIGNO_ARG.CMD_CLIGNO_ARG
        dra_CMD_CLIGNO_ARD: data-element=rp_CMD_CLIGNO_ARD.CMD_CLIGNO_ARD
        dra_PILOTAGE_CLIGNO_AVG: data-element=rp_PILOTAGE_CLIGNO_AVG.PILOTAGE_CLIGNO_AVG
        dra_PILOTAGE_CLIGNO_AVD: data-element=rp_PILOTAGE_CLIGNO_AVD.PILOTAGE_CLIGNO_AVD
      13 x data write access:
        dwa_E_APC: data-element=pp_E_APC.E_APC
        dwa_INFO_CPO_ARG: data-element=pp_INFO_CPO_ARG.INFO_CPO_ARG
        dwa_INFO_CPO_AVG: data-element=pp_INFO_CPO_AVG.INFO_CPO_AVG
        dwa_INFO_CAV_AVG: data-element=pp_INFO_CAV_AVG.INFO_CAV_AVG
        dwa_DMDP_GAV_SECU_ENFANT: data-element=pp_DMPD_GAV_SECU_ENFANT.DMDP_GAV_SECU_ENFANT
        dwa_DMDP_GAV_VERR_CENTRALISE: data-element=pp_DMDP_GAV_VERR_CENTRALISE.DMDP_GAV_VERR_CENTRALISE
        dwa_APPUI_PEDALE_FREIN: data-element=pp_APPUI_PEDALE_FREIN.APPUI_PEDALE_FREIN
        dwa_U_BAT: data-element=pp_U_BAT.U_BAT
        dwa_DMD_FEUX_DETRESSE: data-element=pp_DMD_FEUX_DETRESSE.DMD_FEUX_DETRESSE
        dwa_DIAG_CLIGNO_AVD: data-element=pp_DIAG_CLIGNO_AVD.DIAG_CLIGNO_AVD
        dwa_DIAG_CLIGNO_ARD: data-element=pp_DIAG_CLIGNO_ARD.DIAG_CLIGNO_ARD
        dwa_DIAG_CLIGNO_AVG: data-element=pp_DIAG_CLIGNO_AVG.DIAG_CLIGNO_AVG
        dwa_DIAG_CLIGNO_ARG: data-element=pp_DIAG_CLIGNO_ARG.DIAG_CLIGNO_ARG
      24 x sync call, all with timeout=1.0:
        scp_IOHWAB_Op_Get_INFO_CPO_A: operation=rp_IOHWAB.IOHWAB_Op_Get_INFO_CPO_AVG
        scp_IOHWAB_Op_Get_INFO_CPO_A1: operation=rp_IOHWAB.IOHWAB_Op_Get_INFO_CPO_ARG
        scp_IOHWAB_Op_Get_INFO_CAV_A: operation=rp_IOHWAB.IOHWAB_Op_Get_INFO_CAV_AVG
        scp_IOHWAB_Op_Get_DMDP_GAV_S: operation=rp_IOHWAB.IOHWAB_Op_Get_DMDP_GAV_SECU_ENFANT
        scp_IOHWAB_Op_Get_DMDP_GAV_V: operation=rp_IOHWAB.IOHWAB_Op_Get_DMDP_GAV_VERR_CENTRALISE
        scp_IOHWAB_Op_Get_APPUI_PEDA: operation=rp_IOHWAB.IOHWAB_Op_Get_APPUI_PEDALE_FREIN
        scp_IOHWAB_Op_Get_U_BAT: operation=rp_IOHWAB.IOHWAB_Op_Get_U_BAT
        scp_IOHWAB_Op_Get_DMD_FEUX_D: operation=rp_IOHWAB.IOHWAB_Op_Get_DMD_FEUX_DETRESSE
        scp_IOHWAB_Op_Get_E_APC: operation=rp_IOHWAB.IOHWAB_Op_Get_E_APC
        scp_IOHWAB_Op_Set_P_LED_SIGN: operation=rp_IOHWAB.IOHWAB_Op_Set_P_LED_SIGN_PUSH_FEU_DET
        scp_IOHWAB_Op_Set_CDE_SERRUR: operation=rp_IOHWAB.IOHWAB_Op_Set_CDE_SERRURE_COMMUN
        scp_IOHWAB_Op_Set_CDE_LOGIC_: operation=rp_IOHWAB.IOHWAB_Op_Set_CDE_LOGIC_ECM_FRONT
        scp_IOHWAB_Op_Set_S_CDE_CPC_: operation=rp_IOHWAB.IOHWAB_Op_Set_S_CDE_CPC_BODY_RELAY
        scp_IOHWAB_Op_Set_S_CDE_PLUS: operation=rp_IOHWAB.IOHWAB_Op_Set_S_CDE_PLUS_CAN
        scp_IOHWAB_Op_Set_P_LED_GAV_: operation=rp_IOHWAB.IOHWAB_Op_Set_P_LED_GAV_ETAT_SECU_ENFANT
        scp_IOHWAB_Op_Set_P_LED_GAV_1: operation=rp_IOHWAB.IOHWAB_Op_Set_P_LED_GAV_ETAT_VERR_CENTRALISE
        scp_IOHWAB_Op_Set_CMD_CLIGNO: operation=rp_IOHWAB.IOHWAB_Op_Set_CMD_CLIGNO_ARD
        scp_IOHWAB_Op_Set_CMD_CLIGNO1: operation=rp_IOHWAB.IOHWAB_Op_Set_CMD_CLIGNO_ARG
        scp_IOHWAB_Op_Set_PILOTAGE_C: operation=rp_IOHWAB.IOHWAB_Op_Set_PILOTAGE_CLIGNO_AVD
        scp_IOHWAB_Op_Set_PILOTAGE_C1: operation=rp_IOHWAB.IOHWAB_Op_Set_PILOTAGE_CLIGNO_AVG
        scp_IOHWAB_Op_Diag_CMD_CLIGN: operation=rp_IOHWAB.IOHWAB_Op_Diag_CMD_CLIGNO_ARD
        scp_IOHWAB_Op_Diag_CMD_CLIGN1: operation=rp_IOHWAB.IOHWAB_Op_Diag_CMD_CLIGNO_ARG
        scp_IOHWAB_Op_Diag_PILOTAGE_: operation=rp_IOHWAB.IOHWAB_Op_Diag_PILOTAGE_CLIGNO_AVD
        scp_IOHWAB_Op_Diag_PILOTAGE_1: operation=rp_IOHWAB.IOHWAB_Op_Diag_PILOTAGE_CLIGNO_AVG
  constant specification boolean_v1
    value:
      boolean literal boolean_v1: type=AR_BODY_IO_ASC/boolean, value=false
  swc implementation IO_ASC_Impl: programming-language=C, behavior=IO_ASC_IB
    code-descriptors:
      code IO_ASC_Impl: type=SRC
        xfile R_IO_ASC.c: url=Src_C/R_IO_ASC(1).c
package /AR_BODY_MODE_MANAGER_SWC
  sender receiver interface sri_CDE_LOGIC_ECM_FRONT
    data CDE_LOGIC_ECM_FRONT: type=AR_BODY_IO_ASC/boolean
  sender receiver interface sri_S_CDE_CPC_BODY_RELAY
    data CDE_SMART_ECM: type=AR_BODY_IO_ASC/boolean
  sender receiver interface sri_CDE_PLUS_CAN
    data CDE_PLUS_CAN: type=AR_BODY_MODE_MANAGER_SWC/boolean
  constant specification boolean_v2
    value:
      boolean literal boolean_v2: type=AR_BODY_MODE_MANAGER_SWC/boolean, value=false
  application software component type MODE_MANAGER
    4 x require port:
      CAN_BODY_ACTIVITY: unqueued-receiver-com-spec{data-element=CAN_BODY_ACTIVITY, handle-invalid=KEEP, init-value=cst_Boolean_init/boolean_init, resync-time=0.0}, required-interface=sri_CAN_BODY_ACTIVITY
      CAN_BACKBONE_ACTIVITY: unqueued-receiver-com-spec{data-element=sri_CAN_BACKBONE_ACTIVITY/CAN_BACKBONE_ACTIVITY, handle-invalid=KEEP, init-value=cst_Boolean_init/boolean_init, resync-time=0.0}, required-interface=AR_LPM_SWC/sri_CAN_BACKBONE_ACTIVITY
      CAN_IS_ACTIVITY: unqueued-receiver-com-spec{data-element=CAN_IS_ACTIVITY, handle-invalid=KEEP, init-value=cst_Boolean_init/boolean_init, resync-time=0.0}, required-interface=sri_CAN_IS_ACTIVITY
      ECU_ACTIVITY: unqueued-receiver-com-spec{data-element=ECU_ACTIVITY, handle-invalid=KEEP, init-value=cst_Boolean_init/boolean_init, resync-time=0.0}, required-interface=sri_ECU_ACTIVITY
    provide port pp_CDE_PLUS_CAN: unqueued-sender-com-spec{data-element=sri_CDE_PLUS_CAN/CDE_PLUS_CAN, transmission-acknowledge=timeout=0.0, init-value=boolean_v2}, provided-interface=AR_BODY_MODE_MANAGER_SWC/sri_CDE_PLUS_CAN
    provide port pp_S_CDE_CPC_BODY_RELAY: unqueued-sender-com-spec{data-element=CDE_SMART_ECM, transmission-acknowledge=timeout=0.0, init-value=boolean_v1}, provided-interface=sri_S_CDE_CPC_BODY_RELAY
    provide port pp_CDE_LOGIC_ECM_FRONT: unqueued-sender-com-spec{data-element=sri_CDE_LOGIC_ECM_FRONT/CDE_LOGIC_ECM_FRONT, transmission-acknowledge=timeout=0.0, init-value=boolean_v1}, provided-interface=AR_BODY_MODE_MANAGER_SWC/sri_CDE_LOGIC_ECM_FRONT
    5 x require port:
      rp_EcuM_StateRequest: required-com-specs=[RequestRUN, ReleaseRUN, RequestPOSTRUN, ReleasePOSTRUN], required-interface=EcuM_StateRequest
      rp_ComMUserRequest0: required-com-specs=[RequestComMode, GetCurrentComMode, GetRequestedMode, GetMaxComMode], required-interface=ComM_UserRequest
      rp_ComMUserRequest1: required-com-specs=[RequestComMode, GetCurrentComMode, GetRequestedMode, GetMaxComMode], required-interface=ComM_UserRequest
      rp_EcM_CurrentMode: required-interface=EcuM_CurrentMode
      rp_ComM_CurrentMode: required-interface=ComM_CurrentMode
  internal behavior MODE_MANAGER_IB: component=MODE_MANAGER
    mode switch event E_STARTUP_COMMUNICATION: start-on-event=R_MODE_MANAGER, activation=ENTRY, mode=rp_EcM_CurrentMode.currentMode.RUN
    timing event TimingEvent: start-on-event=R_MODE_MANAGER, period=0.01
    runnable R_MODE_MANAGER
      4 x data read access:
        dra_CAN_BODY_ACTIVITY: data-element=CAN_BODY_ACTIVITY.CAN_BODY_ACTIVITY
        dra_CAN_BACKBONE_ACTIVITY: data-element=CAN_BACKBONE_ACTIVITY.CAN_BACKBONE_ACTIVITY
        dra_CAN_IS_ACTIVITY: data-element=CAN_IS_ACTIVITY.CAN_IS_ACTIVITY
        dra_ECU_ACTIVITY: data-element=ECU_ACTIVITY.ECU_ACTIVITY
      data write access dwa_CDE_PLUS_CAN: data-element=pp_CDE_PLUS_CAN.CDE_PLUS_CAN
      data write access dwa_CDE_SMART_ECM: data-element=pp_S_CDE_CPC_BODY_RELAY.CDE_SMART_ECM
      data write access dwa_CDE_LOGIC_ECM_FRONT: data-element=pp_CDE_LOGIC_ECM_FRONT.CDE_LOGIC_ECM_FRONT
      5 x sync call, all with timeout=1.0:
        scp_RequestRUN: operation=rp_EcuM_StateRequest.RequestRUN
        scp_RequestComMode: operation=rp_ComMUserRequest0.RequestComMode
        scp_GetCurrentComMode: operation=rp_ComMUserRequest0.GetCurrentComMode
        scp_ReleaseRUN: operation=rp_EcuM_StateRequest.ReleaseRUN
        scp_RequestComMode1: operation=rp_ComMUserRequest1.RequestComMode
  swc implementation MODE_MANAGER_Impl: programming-language=C, behavior=MODE_MANAGER_IB
    code-descriptors:
      code ECM_ModeManager_Code_Impl: type=SRC
        xfile R_MODE_MANAGER.c: url=Src_C/R_MODE_MANAGER(1).c
package /AR_BODY_IO
  client server interface cs_IOHWAB: is-service=true
    24 x operation:
      IOHWAB_Op_Get_INFO_CPO_AVG
        arg Level: type=Dio_LevelType, direction=OUT
      IOHWAB_Op_Get_INFO_CPO_ARG
        arg Level: type=Dio_LevelType, direction=OUT
      IOHWAB_Op_Get_INFO_CAV_AVG
        arg Level: type=Dio_LevelType, direction=OUT
      IOHWAB_Op_Get_DMDP_GAV_SECU_ENFANT
        arg Level: type=Dio_LevelType, direction=OUT
      IOHWAB_Op_Get_DMDP_GAV_VERR_CENTRALISE
        arg Level: type=Dio_LevelType, direction=OUT
      IOHWAB_Op_Get_APPUI_PEDALE_FREIN
        arg Level: type=Dio_LevelType, direction=OUT
      IOHWAB_Op_Get_U_BAT
        arg Level: type=Adc_ValueGroupType, direction=OUT
      IOHWAB_Op_Get_DMD_FEUX_DETRESSE
        arg Level: type=Dio_LevelType, direction=OUT
      IOHWAB_Op_Get_E_APC
        arg Level: type=Dio_LevelType, direction=OUT
      IOHWAB_Op_Set_P_LED_SIGN_PUSH_FEU_DET
        arg Level: type=Dio_LevelType, direction=IN
      IOHWAB_Op_Set_CDE_SERRURE_COMMUN
        arg Level: type=Dio_LevelType, direction=IN
      IOHWAB_Op_Set_CDE_LOGIC_ECM_FRONT
        arg Level: type=Dio_LevelType, direction=IN
      IOHWAB_Op_Set_S_CDE_CPC_BODY_RELAY
        arg Level: type=Dio_LevelType, direction=IN
      IOHWAB_Op_Set_S_CDE_PLUS_CAN
        arg Level: type=Dio_LevelType, direction=IN
      IOHWAB_Op_Set_P_LED_GAV_ETAT_SECU_ENFANT
        arg Level: type=Dio_LevelType, direction=IN
      IOHWAB_Op_Set_P_LED_GAV_ETAT_VERR_CENTRALISE
        arg Level: type=Dio_LevelType, direction=IN
      IOHWAB_Op_Set_CMD_CLIGNO_ARD
        arg Level: type=Dio_LevelType, direction=IN
      IOHWAB_Op_Set_CMD_CLIGNO_ARG
        arg Level: type=Dio_LevelType, direction=IN
      IOHWAB_Op_Set_PILOTAGE_CLIGNO_AVD
        arg Level: type=Dio_LevelType, direction=IN
      IOHWAB_Op_Set_PILOTAGE_CLIGNO_AVG
        arg Level: type=Dio_LevelType, direction=IN
      IOHWAB_Op_Diag_CMD_CLIGNO_ARD
        arg Level: type=IoHwAb_SignalDiagnosisType, direction=OUT
      IOHWAB_Op_Diag_CMD_CLIGNO_ARG
        arg Level: type=IoHwAb_SignalDiagnosisType, direction=OUT
      IOHWAB_Op_Diag_PILOTAGE_CLIGNO_AVD
        arg Level: type=IoHwAb_SignalDiagnosisType, direction=OUT
      IOHWAB_Op_Diag_PILOTAGE_CLIGNO_AVG
        arg Level: type=IoHwAb_SignalDiagnosisType, direction=OUT
  integer type Dio_LevelType: sw-calibration-access=READ-ONLY, sw-impl-policy=MEASUREMENT-POINT, sw-variable-access-impl-policy=OPTIMIZED, lower-limit=0, upper-limit=255
  integer type Adc_ValueGroupType: sw-calibration-access=READ-ONLY, sw-impl-policy=MEASUREMENT-POINT, sw-variable-access-impl-policy=OPTIMIZED, lower-limit=0, upper-limit=65535
  integer type IoHwAb_SignalDiagnosisType: sw-calibration-access=READ-ONLY, sw-impl-policy=MEASUREMENT-POINT, sw-variable-access-impl-policy=OPTIMIZED, lower-limit=0, upper-limit=255
  ecu abstraction component type IOHWAB
    provide port pp_IOHWAB: provided-interface=cs_IOHWAB
      provided-com-specs:
        operation=IOHWAB_Op_Get_INFO_CPO_AVG, queue-length=1
        operation=IOHWAB_Op_Get_INFO_CPO_ARG, queue-length=1
        operation=IOHWAB_Op_Get_INFO_CAV_AVG, queue-length=1
        operation=IOHWAB_Op_Get_DMDP_GAV_SECU_ENFANT, queue-length=1
        operation=IOHWAB_Op_Get_DMDP_GAV_VERR_CENTRALISE, queue-length=1
        operation=IOHWAB_Op_Get_APPUI_PEDALE_FREIN, queue-length=1
        operation=IOHWAB_Op_Get_U_BAT, queue-length=1
        operation=IOHWAB_Op_Get_DMD_FEUX_DETRESSE, queue-length=1
        operation=IOHWAB_Op_Get_E_APC, queue-length=1
        operation=IOHWAB_Op_Set_P_LED_SIGN_PUSH_FEU_DET, queue-length=1
        operation=IOHWAB_Op_Set_CDE_SERRURE_COMMUN, queue-length=1
        operation=IOHWAB_Op_Set_CDE_LOGIC_ECM_FRONT, queue-length=1
        operation=IOHWAB_Op_Set_S_CDE_CPC_BODY_RELAY, queue-length=1
        operation=IOHWAB_Op_Set_S_CDE_PLUS_CAN, queue-length=1
        operation=IOHWAB_Op_Set_P_LED_GAV_ETAT_SECU_ENFANT, queue-length=1
        operation=IOHWAB_Op_Set_P_LED_GAV_ETAT_VERR_CENTRALISE, queue-length=1
        operation=IOHWAB_Op_Set_CMD_CLIGNO_ARD, queue-length=1
        operation=IOHWAB_Op_Set_CMD_CLIGNO_ARG, queue-length=1
        operation=IOHWAB_Op_Set_PILOTAGE_CLIGNO_AVD, queue-length=1
        operation=IOHWAB_Op_Set_PILOTAGE_CLIGNO_AVG, queue-length=1
        operation=IOHWAB_Op_Diag_CMD_CLIGNO_ARD, queue-length=1
        operation=IOHWAB_Op_Diag_CMD_CLIGNO_ARG, queue-length=1
        operation=IOHWAB_Op_Diag_PILOTAGE_CLIGNO_AVD, queue-length=1
        operation=IOHWAB_Op_Diag_PILOTAGE_CLIGNO_AVG, queue-length=1
  internal behavior IOHWAB_IB: component=IOHWAB
    runnable R_IOHWAB
  swc implementation IOHWAB_Impl: programming-language=C, behavior=IOHWAB_IB
package /AR_IHM_SWC
  application software component type IHM_OUBLI_FEUX
    require port rp_P_SON_SIGN_OUBLI_FEUX: unqueued-receiver-com-spec{data-element=sri_P_SON_SIGN_OUBLI_FEUX/P_SON_SIGN_OUBLI_FEUX, handle-invalid=KEEP, init-value=cst_Boolean_init/boolean_init, resync-time=0.0}, required-interface=AR_IHM_SWC/sri_P_SON_SIGN_OUBLI_FEUX
    provide port pp_OUBLI_FEUX: unqueued-sender-com-spec{data-element=OUBLI_FEUX, init-value=cst_Boolean_init/boolean_init}, provided-interface=sri_OUBLI_FEUX
  composition type MDL_IHM
    4 x require port:
      rp_P_SON_SIGN_OUBLI_FEUX: unqueued-receiver-com-spec{data-element=sri_P_SON_SIGN_OUBLI_FEUX/P_SON_SIGN_OUBLI_FEUX, handle-invalid=KEEP, init-value=cst_Boolean_init/boolean_init, resync-time=0.0}, required-interface=AR_IHM_SWC/sri_P_SON_SIGN_OUBLI_FEUX
      rp_VITESSE_LONGITUDINALE: unqueued-receiver-com-spec{data-element=sri_VITESSE_LONGITUDINALE/VITESSE_LONGITUDINALE, handle-invalid=KEEP, init-value=cst_UInt16_init/uint16_init, resync-time=0.0}, required-interface=AR_IHM_SWC/sri_VITESSE_LONGITUDINALE
      rp_ETAT_CLIGNOTANT_G: unqueued-receiver-com-spec{data-element=sri_ETAT_CLIGNOTANT_G/ETAT_CLIGNOTANT_G, handle-invalid=KEEP, init-value=cst_Boolean_init/boolean_init, resync-time=0.0}, required-interface=AR_IHM_SWC/sri_ETAT_CLIGNOTANT_G
      rp_ETAT_CLIGNOTANT_D: unqueued-receiver-com-spec{data-element=sri_ETAT_CLIGNOTANT_D/ETAT_CLIGNOTANT_D, handle-invalid=KEEP, init-value=cst_Boolean_init/boolean_init, resync-time=0.0}, required-interface=AR_IHM_SWC/sri_ETAT_CLIGNOTANT_D
    provide port pp_EM_SON_CMD_BRT: unqueued-sender-com-spec{data-element=EM_SON_CMD_BRT, init-value=cst_UInt8_init/uint8_init}, provided-interface=sri_EM_SON_CMD_BRT
    provide port pp_NIV_SON_CMD_BRT: unqueued-sender-com-spec{data-element=NIV_SON_CMD_BRT, init-value=cst_UInt8_init/uint8_init}, provided-interface=sri_NIV_SON_CMD_BRT
    8 x require port:
      rp_P_SON_SIGN_FX_CLIGNO_CLIC: unqueued-receiver-com-spec{data-element=sri_P_SON_SIGN_FX_CLIGNO_CLIC/P_SON_SIGN_FX_CLIGNO_CLIC, handle-invalid=KEEP, init-value=cst_Boolean_init/boolean_init, resync-time=0.0}, required-interface=AR_IHM_SWC/sri_P_SON_SIGN_FX_CLIGNO_CLIC
      rp_P_SON_SIGN_FX_CLIGNO_CLAC: unqueued-receiver-com-spec{data-element=sri_P_SON_SIGN_FX_CLIGNO_CLAC/P_SON_SIGN_FX_CLIGNO_CLAC, handle-invalid=KEEP, init-value=cst_Boolean_init/boolean_init, resync-time=0.0}, required-interface=AR_IHM_SWC/sri_P_SON_SIGN_FX_CLIGNO_CLAC
      rp_P_SON_SIGN_FX_CLIGNO_CLIC_R: unqueued-receiver-com-spec{data-element=sri_P_SON_SIGN_FX_CLIGNO_CLIC_R/P_SON_SIGN_FX_CLIGNO_CLIC_R, handle-invalid=KEEP, init-value=cst_Boolean_init/boolean_init, resync-time=0.0}, required-interface=AR_IHM_SWC/sri_P_SON_SIGN_FX_CLIGNO_CLIC_R
      rp_P_SON_SIGN_FX_CLIGNO_CLAC_R: unqueued-receiver-com-spec{data-element=sri_P_SON_SIGN_FX_CLIGNO_CLAC_R/P_SON_SIGN_FX_CLIGNO_CLAC_R, handle-invalid=KEEP, init-value=cst_Boolean_init/boolean_init, resync-time=0.0}, required-interface=AR_IHM_SWC/sri_P_SON_SIGN_FX_CLIGNO_CLAC_R
      rp_P_SON_SIGN_FX_CLIGNO_CLIC_REL: unqueued-receiver-com-spec{data-element=sri_P_SON_SIGN_FX_CLIGNO_CLIC_REL/P_SON_SIGN_FX_CLIGNO_CLIC_REL, handle-invalid=KEEP, init-value=cst_Boolean_init/boolean_init, resync-time=0.0}, required-interface=AR_IHM_SWC/sri_P_SON_SIGN_FX_CLIGNO_CLIC_REL
      rp_P_SON_SIGN_FX_CLIGNO_CLAC_REL: unqueued-receiver-com-spec{data-element=sri_P_SON_SIGN_FX_CLIGNO_CLAC_REL/P_SON_SIGN_FX_CLIGNO_CLAC_REL, handle-invalid=KEEP, init-value=cst_Boolean_init/boolean_init, resync-time=0.0}, required-interface=AR_IHM_SWC/sri_P_SON_SIGN_FX_CLIGNO_CLAC_REL
      rp_P_SON_SIGN_FX_CLIGNO_CLIC_R_REL: unqueued-receiver-com-spec{data-element=sri_P_SON_SIGN_FX_CLIGNO_CLIC_R_REL/P_SON_SIGN_FX_CLIGNO_CLIC_R_REL, handle-invalid=KEEP, init-value=cst_Boolean_init/boolean_init, resync-time=0.0}, required-interface=AR_IHM_SWC/sri_P_SON_SIGN_FX_CLIGNO_CLIC_R_REL
      rp_P_SON_SIGN_FX_CLIGNO_CLAC_R_REL: unqueued-receiver-com-spec{data-element=sri_P_SON_SIGN_FX_CLIGNO_CLAC_R_REL/P_SON_SIGN_FX_CLIGNO_CLAC_R_REL, handle-invalid=KEEP, init-value=cst_Boolean_init/boolean_init, resync-time=0.0}, required-interface=AR_IHM_SWC/sri_P_SON_SIGN_FX_CLIGNO_CLAC_R_REL
    component IHM_OUBLI_FEUX: type=IHM_OUBLI_FEUX
    component IHM_TRAME_CMD_BRT: type=IHM_TRAME_CMD_BRT
    component IHM_CLIGNO: type=IHM_CLIGNO
    connect IHM_OUBLI_FEUX.pp_OUBLI_FEUX -> IHM_TRAME_CMD_BRT.rp_OUBLI_FEUX
    connect IHM_CLIGNO.pp_CLIGNO_CLIC -> IHM_TRAME_CMD_BRT.rp_CLIGNO_CLIC
    connect IHM_CLIGNO.pp_CLIGNO_CLAC -> IHM_TRAME_CMD_BRT.rp_CLIGNO_CLAC
    delegate IHM_OUBLI_FEUX.rp_P_SON_SIGN_OUBLI_FEUX <-> outer port MDL_IHM/rp_P_SON_SIGN_OUBLI_FEUX
    delegate IHM_TRAME_CMD_BRT.rp_VITESSE_LONGITUDINALE <-> outer port MDL_IHM/rp_VITESSE_LONGITUDINALE
    delegate IHM_TRAME_CMD_BRT.rp_ETAT_CLIGNOTANT_G <-> outer port MDL_IHM/rp_ETAT_CLIGNOTANT_G
    delegate IHM_TRAME_CMD_BRT.rp_ETAT_CLIGNOTANT_D <-> outer port MDL_IHM/rp_ETAT_CLIGNOTANT_D
    delegate IHM_TRAME_CMD_BRT.pp_EM_SON_CMD_BRT <-> outer port MDL_IHM/pp_EM_SON_CMD_BRT
    delegate IHM_TRAME_CMD_BRT.pp_NIV_SON_CMD_BRT <-> outer port MDL_IHM/pp_NIV_SON_CMD_BRT
    delegate IHM_CLIGNO.rp_P_SON_SIGN_FX_CLIGNO_CLIC <-> outer port MDL_IHM/rp_P_SON_SIGN_FX_CLIGNO_CLIC
    delegate IHM_CLIGNO.rp_P_SON_SIGN_FX_CLIGNO_CLAC <-> outer port MDL_IHM/rp_P_SON_SIGN_FX_CLIGNO_CLAC
    delegate IHM_CLIGNO.rp_P_SON_SIGN_FX_CLIGNO_CLIC_R <-> outer port MDL_IHM/rp_P_SON_SIGN_FX_CLIGNO_CLIC_R
    delegate IHM_CLIGNO.rp_P_SON_SIGN_FX_CLIGNO_CLAC_R <-> outer port MDL_IHM/rp_P_SON_SIGN_FX_CLIGNO_CLAC_R
    delegate IHM_CLIGNO.rp_P_SON_SIGN_FX_CLIGNO_CLIC_REL <-> outer port MDL_IHM/rp_P_SON_SIGN_FX_CLIGNO_CLIC_REL
    delegate IHM_CLIGNO.rp_P_SON_SIGN_FX_CLIGNO_CLAC_REL <-> outer port MDL_IHM/rp_P_SON_SIGN_FX_CLIGNO_CLAC_REL
    delegate IHM_CLIGNO.rp_P_SON_SIGN_FX_CLIGNO_CLIC_R_REL <-> outer port MDL_IHM/rp_P_SON_SIGN_FX_CLIGNO_CLIC_R_REL
    delegate IHM_CLIGNO.rp_P_SON_SIGN_FX_CLIGNO_CLAC_R_REL <-> outer port MDL_IHM/rp_P_SON_SIGN_FX_CLIGNO_CLAC_R_REL
  composition type IHM
    12 x require port:
      rp_ETAT_CLIGNOTANT_G: unqueued-receiver-com-spec{data-element=sri_ETAT_CLIGNOTANT_G/ETAT_CLIGNOTANT_G, handle-invalid=KEEP, init-value=cst_Boolean_init/boolean_init, resync-time=0.0}, required-interface=AR_IHM_SWC/sri_ETAT_CLIGNOTANT_G
      rp_ETAT_CLIGNOTANT_D: unqueued-receiver-com-spec{data-element=sri_ETAT_CLIGNOTANT_D/ETAT_CLIGNOTANT_D, handle-invalid=KEEP, init-value=cst_Boolean_init/boolean_init, resync-time=0.0}, required-interface=AR_IHM_SWC/sri_ETAT_CLIGNOTANT_D
      rp_P_SON_SIGN_FX_CLIGNO_CLIC: unqueued-receiver-com-spec{data-element=sri_P_SON_SIGN_FX_CLIGNO_CLIC/P_SON_SIGN_FX_CLIGNO_CLIC, handle-invalid=KEEP, init-value=cst_Boolean_init/boolean_init, resync-time=0.0}, required-interface=AR_IHM_SWC/sri_P_SON_SIGN_FX_CLIGNO_CLIC
      rp_P_SON_SIGN_FX_CLIGNO_CLAC: unqueued-receiver-com-spec{data-element=sri_P_SON_SIGN_FX_CLIGNO_CLAC/P_SON_SIGN_FX_CLIGNO_CLAC, handle-invalid=KEEP, init-value=cst_Boolean_init/boolean_init, resync-time=0.0}, required-interface=AR_IHM_SWC/sri_P_SON_SIGN_FX_CLIGNO_CLAC
      rp_P_SON_SIGN_FX_CLIGNO_CLIC_R: unqueued-receiver-com-spec{data-element=sri_P_SON_SIGN_FX_CLIGNO_CLIC_R/P_SON_SIGN_FX_CLIGNO_CLIC_R, handle-invalid=KEEP, init-value=cst_Boolean_init/boolean_init, resync-time=0.0}, required-interface=AR_IHM_SWC/sri_P_SON_SIGN_FX_CLIGNO_CLIC_R
      rp_P_SON_SIGN_FX_CLIGNO_CLAC_R: unqueued-receiver-com-spec{data-element=sri_P_SON_SIGN_FX_CLIGNO_CLAC_R/P_SON_SIGN_FX_CLIGNO_CLAC_R, handle-invalid=KEEP, init-value=cst_Boolean_init/boolean_init, resync-time=0.0}, required-interface=AR_IHM_SWC/sri_P_SON_SIGN_FX_CLIGNO_CLAC_R
      rp_P_SON_SIGN_FX_CLIGNO_CLIC_REL: unqueued-receiver-com-spec{data-element=sri_P_SON_SIGN_FX_CLIGNO_CLIC_REL/P_SON_SIGN_FX_CLIGNO_CLIC_REL, handle-invalid=KEEP, init-value=cst_Boolean_init/boolean_init, resync-time=0.0}, required-interface=AR_IHM_SWC/sri_P_SON_SIGN_FX_CLIGNO_CLIC_REL
      rp_P_SON_SIGN_FX_CLIGNO_CLAC_REL: unqueued-receiver-com-spec{data-element=sri_P_SON_SIGN_FX_CLIGNO_CLAC_REL/P_SON_SIGN_FX_CLIGNO_CLAC_REL, handle-invalid=KEEP, init-value=cst_Boolean_init/boolean_init, resync-time=0.0}, required-interface=AR_IHM_SWC/sri_P_SON_SIGN_FX_CLIGNO_CLAC_REL
      rp_P_SON_SIGN_FX_CLIGNO_CLIC_R_REL: unqueued-receiver-com-spec{data-element=sri_P_SON_SIGN_FX_CLIGNO_CLIC_R_REL/P_SON_SIGN_FX_CLIGNO_CLIC_R_REL, handle-invalid=KEEP, init-value=cst_Boolean_init/boolean_init, resync-time=0.0}, required-interface=AR_IHM_SWC/sri_P_SON_SIGN_FX_CLIGNO_CLIC_R_REL
      rp_P_SON_SIGN_FX_CLIGNO_CLAC_R_REL: unqueued-receiver-com-spec{data-element=sri_P_SON_SIGN_FX_CLIGNO_CLAC_R_REL/P_SON_SIGN_FX_CLIGNO_CLAC_R_REL, handle-invalid=KEEP, init-value=cst_Boolean_init/boolean_init, resync-time=0.0}, required-interface=AR_IHM_SWC/sri_P_SON_SIGN_FX_CLIGNO_CLAC_R_REL
      rp_P_SON_SIGN_OUBLI_FEUX: unqueued-receiver-com-spec{data-element=sri_P_SON_SIGN_OUBLI_FEUX/P_SON_SIGN_OUBLI_FEUX, handle-invalid=KEEP, init-value=cst_Boolean_init/boolean_init, resync-time=0.0}, required-interface=AR_IHM_SWC/sri_P_SON_SIGN_OUBLI_FEUX
      rp_VITESSE_LONGITUDINALE: unqueued-receiver-com-spec{data-element=sri_VITESSE_LONGITUDINALE/VITESSE_LONGITUDINALE, handle-invalid=KEEP, init-value=cst_UInt16_init/uint16_init, resync-time=0.0}, required-interface=AR_IHM_SWC/sri_VITESSE_LONGITUDINALE
    provide port pp_EM_SON_CMD_BRT: unqueued-sender-com-spec{data-element=EM_SON_CMD_BRT, init-value=cst_UInt8_init/uint8_init}, provided-interface=sri_EM_SON_CMD_BRT
    provide port pp_NIV_SON_CMD_BRT: unqueued-sender-com-spec{data-element=NIV_SON_CMD_BRT, init-value=cst_UInt8_init/uint8_init}, provided-interface=sri_NIV_SON_CMD_BRT
    component MDL_IHM: type=MDL_IHM
    delegate MDL_IHM.rp_P_SON_SIGN_OUBLI_FEUX <-> outer port IHM/rp_P_SON_SIGN_OUBLI_FEUX
    delegate MDL_IHM.rp_VITESSE_LONGITUDINALE <-> outer port IHM/rp_VITESSE_LONGITUDINALE
    delegate MDL_IHM.rp_ETAT_CLIGNOTANT_G <-> outer port IHM/rp_ETAT_CLIGNOTANT_G
    delegate MDL_IHM.rp_ETAT_CLIGNOTANT_D <-> outer port IHM/rp_ETAT_CLIGNOTANT_D
    delegate MDL_IHM.pp_EM_SON_CMD_BRT <-> outer port IHM/pp_EM_SON_CMD_BRT
    delegate MDL_IHM.pp_NIV_SON_CMD_BRT <-> outer port IHM/pp_NIV_SON_CMD_BRT
    delegate MDL_IHM.rp_P_SON_SIGN_FX_CLIGNO_CLIC <-> outer port IHM/rp_P_SON_SIGN_FX_CLIGNO_CLIC
    delegate MDL_IHM.rp_P_SON_SIGN_FX_CLIGNO_CLAC <-> outer port IHM/rp_P_SON_SIGN_FX_CLIGNO_CLAC
    delegate MDL_IHM.rp_P_SON_SIGN_FX_CLIGNO_CLIC_R <-> outer port IHM/rp_P_SON_SIGN_FX_CLIGNO_CLIC_R
    delegate MDL_IHM.rp_P_SON_SIGN_FX_CLIGNO_CLAC_R <-> outer port IHM/rp_P_SON_SIGN_FX_CLIGNO_CLAC_R
    delegate MDL_IHM.rp_P_SON_SIGN_FX_CLIGNO_CLIC_REL <-> outer port IHM/rp_P_SON_SIGN_FX_CLIGNO_CLIC_REL
    delegate MDL_IHM.rp_P_SON_SIGN_FX_CLIGNO_CLAC_REL <-> outer port IHM/rp_P_SON_SIGN_FX_CLIGNO_CLAC_REL
    delegate MDL_IHM.rp_P_SON_SIGN_FX_CLIGNO_CLIC_R_REL <-> outer port IHM/rp_P_SON_SIGN_FX_CLIGNO_CLIC_R_REL
    delegate MDL_IHM.rp_P_SON_SIGN_FX_CLIGNO_CLAC_R_REL <-> outer port IHM/rp_P_SON_SIGN_FX_CLIGNO_CLAC_R_REL
  internal behavior ib_IHM_OUBLI_FEUX: component=IHM_OUBLI_FEUX
    timing event evt_IHM_OUBLI_FEUX: start-on-event=IHM_OUBLI_FEUX, period=0.1
    runnable IHM_OUBLI_FEUX
      data read access dra_P_SON_SIGN_OUBLI_FEUX: data-element=rp_P_SON_SIGN_OUBLI_FEUX.P_SON_SIGN_OUBLI_FEUX
      data write access dwa_OUBLI_FEUX: data-element=pp_OUBLI_FEUX.OUBLI_FEUX
  sender receiver interface sri_P_SON_SIGN_OUBLI_FEUX
    data P_SON_SIGN_OUBLI_FEUX: type=AR_IHM_SWC/Boolean
  constant specification cst_Boolean_init
    value:
      boolean literal boolean_init: type=AR_IHM_SWC/Boolean, value=false
  sender receiver interface sri_OUBLI_FEUX
    data OUBLI_FEUX: type=AR_IHM_SWC/Boolean
  swc implementation implem_IHM_OUBLI_FEUX: programming-language=C, behavior=ib_IHM_OUBLI_FEUX
    code-descriptors:
      code implem_IHM_OUBLI_FEUX: type=SRC
        xfile IHM_OUBLI_FEUX.c: url=Src_C/IHM_OUBLI_FEUX.c
  application software component type IHM_TRAME_CMD_BRT
    6 x require port:
      rp_VITESSE_LONGITUDINALE: unqueued-receiver-com-spec{data-element=sri_VITESSE_LONGITUDINALE/VITESSE_LONGITUDINALE, handle-invalid=KEEP, init-value=cst_UInt16_init/uint16_init, resync-time=0.0}, required-interface=AR_IHM_SWC/sri_VITESSE_LONGITUDINALE
      rp_CLIGNO_CLIC: unqueued-receiver-com-spec{data-element=CLIGNO_CLIC, handle-invalid=KEEP, init-value=cst_Boolean_init/boolean_init, resync-time=0.0}, required-interface=sri_CLIGNO_CLIC
      rp_CLIGNO_CLAC: unqueued-receiver-com-spec{data-element=CLIGNO_CLAC, handle-invalid=KEEP, init-value=cst_Boolean_init/boolean_init, resync-time=0.0}, required-interface=sri_CLIGNO_CLAC
      rp_OUBLI_FEUX: unqueued-receiver-com-spec{data-element=OUBLI_FEUX, handle-invalid=KEEP, init-value=cst_Boolean_init/boolean_init, resync-time=0.0}, required-interface=sri_OUBLI_FEUX
      rp_ETAT_CLIGNOTANT_G: unqueued-receiver-com-spec{data-element=sri_ETAT_CLIGNOTANT_G/ETAT_CLIGNOTANT_G, handle-invalid=KEEP, init-value=cst_Boolean_init/boolean_init, resync-time=0.0}, required-interface=AR_IHM_SWC/sri_ETAT_CLIGNOTANT_G
      rp_ETAT_CLIGNOTANT_D: unqueued-receiver-com-spec{data-element=sri_ETAT_CLIGNOTANT_D/ETAT_CLIGNOTANT_D, handle-invalid=KEEP, init-value=cst_Boolean_init/boolean_init, resync-time=0.0}, required-interface=AR_IHM_SWC/sri_ETAT_CLIGNOTANT_D
    provide port pp_EM_SON_CMD_BRT: unqueued-sender-com-spec{data-element=EM_SON_CMD_BRT, init-value=cst_UInt8_init/uint8_init}, provided-interface=sri_EM_SON_CMD_BRT
    provide port pp_NIV_SON_CMD_BRT: unqueued-sender-com-spec{data-element=NIV_SON_CMD_BRT, init-value=cst_UInt8_init/uint8_init}, provided-interface=sri_NIV_SON_CMD_BRT
  internal behavior ib_IHM_TRAME_CMD_BRT: component=IHM_TRAME_CMD_BRT
    timing event evt_IHM_TRAME_CMD_BRT: start-on-event=IHM_TRAME_CMD_BRT, period=0.1
    runnable IHM_TRAME_CMD_BRT
      6 x data read access:
        dra_VITESSE_LONGITUDINALE: data-element=rp_VITESSE_LONGITUDINALE.VITESSE_LONGITUDINALE
        dra_CLIGNO_CLIC: data-element=rp_CLIGNO_CLIC.CLIGNO_CLIC
        dra_CLIGNO_CLAC: data-element=rp_CLIGNO_CLAC.CLIGNO_CLAC
        dra_OUBLI_FEUX: data-element=rp_OUBLI_FEUX.OUBLI_FEUX
        dra_ETAT_CLIGNOTANT_G: data-element=rp_ETAT_CLIGNOTANT_G.ETAT_CLIGNOTANT_G
        dra_ETAT_CLIGNOTANT_D: data-element=rp_ETAT_CLIGNOTANT_D.ETAT_CLIGNOTANT_D
      data write access dwa_EM_SON_CMD_BRT: data-element=pp_EM_SON_CMD_BRT.EM_SON_CMD_BRT
      data write access dwa_NIV_SON_CMD_BRT: data-element=pp_NIV_SON_CMD_BRT.NIV_SON_CMD_BRT
  sender receiver interface sri_VITESSE_LONGITUDINALE
    data VITESSE_LONGITUDINALE: type=AR_IHM_SWC/UInt16
  constant specification cst_UInt16_init
    value:
      integer literal uint16_init: type=AR_IHM_SWC/UInt16, value=0
  5 x sender receiver interface:
    sri_CLIGNO_CLIC
      data CLIGNO_CLIC: type=AR_IHM_SWC/Boolean
    sri_CLIGNO_CLAC
      data CLIGNO_CLAC: type=AR_IHM_SWC/Boolean
    sri_ETAT_CLIGNOTANT_G
      data ETAT_CLIGNOTANT_G: type=AR_IHM_SWC/Boolean
    sri_ETAT_CLIGNOTANT_D
      data ETAT_CLIGNOTANT_D: type=AR_IHM_SWC/Boolean
    sri_EM_SON_CMD_BRT
      data EM_SON_CMD_BRT: type=AR_IHM_SWC/UInt8
  constant specification cst_UInt8_init
    value:
      integer literal uint8_init: type=AR_IHM_SWC/UInt8, value=0
  sender receiver interface sri_NIV_SON_CMD_BRT
    data NIV_SON_CMD_BRT: type=AR_IHM_SWC/UInt8
  swc implementation implem_IHM_TRAME_CMD_BRT: programming-language=C, behavior=ib_IHM_TRAME_CMD_BRT
    code-descriptors:
      code implem_IHM_TRAME_CMD_BRT: type=SRC
        xfile IHM_TRAME_CMD_BRT.c: url=Src_C/IHM_TRAME_CMD_BRT.c
  application software component type IHM_CLIGNO
    8 x require port:
      rp_P_SON_SIGN_FX_CLIGNO_CLIC: unqueued-receiver-com-spec{data-element=sri_P_SON_SIGN_FX_CLIGNO_CLIC/P_SON_SIGN_FX_CLIGNO_CLIC, handle-invalid=KEEP, init-value=cst_Boolean_init/boolean_init, resync-time=0.0}, required-interface=AR_IHM_SWC/sri_P_SON_SIGN_FX_CLIGNO_CLIC
      rp_P_SON_SIGN_FX_CLIGNO_CLIC_R: unqueued-receiver-com-spec{data-element=sri_P_SON_SIGN_FX_CLIGNO_CLIC_R/P_SON_SIGN_FX_CLIGNO_CLIC_R, handle-invalid=KEEP, init-value=cst_Boolean_init/boolean_init, resync-time=0.0}, required-interface=AR_IHM_SWC/sri_P_SON_SIGN_FX_CLIGNO_CLIC_R
      rp_P_SON_SIGN_FX_CLIGNO_CLIC_REL: unqueued-receiver-com-spec{data-element=sri_P_SON_SIGN_FX_CLIGNO_CLIC_REL/P_SON_SIGN_FX_CLIGNO_CLIC_REL, handle-invalid=KEEP, init-value=cst_Boolean_init/boolean_init, resync-time=0.0}, required-interface=AR_IHM_SWC/sri_P_SON_SIGN_FX_CLIGNO_CLIC_REL
      rp_P_SON_SIGN_FX_CLIGNO_CLIC_R_REL: unqueued-receiver-com-spec{data-element=sri_P_SON_SIGN_FX_CLIGNO_CLIC_R_REL/P_SON_SIGN_FX_CLIGNO_CLIC_R_REL, handle-invalid=KEEP, init-value=cst_Boolean_init/boolean_init, resync-time=0.0}, required-interface=AR_IHM_SWC/sri_P_SON_SIGN_FX_CLIGNO_CLIC_R_REL
      rp_P_SON_SIGN_FX_CLIGNO_CLAC: unqueued-receiver-com-spec{data-element=sri_P_SON_SIGN_FX_CLIGNO_CLAC/P_SON_SIGN_FX_CLIGNO_CLAC, handle-invalid=KEEP, init-value=cst_Boolean_init/boolean_init, resync-time=0.0}, required-interface=AR_IHM_SWC/sri_P_SON_SIGN_FX_CLIGNO_CLAC
      rp_P_SON_SIGN_FX_CLIGNO_CLAC_R: unqueued-receiver-com-spec{data-element=sri_P_SON_SIGN_FX_CLIGNO_CLAC_R/P_SON_SIGN_FX_CLIGNO_CLAC_R, handle-invalid=KEEP, init-value=cst_Boolean_init/boolean_init, resync-time=0.0}, required-interface=AR_IHM_SWC/sri_P_SON_SIGN_FX_CLIGNO_CLAC_R
      rp_P_SON_SIGN_FX_CLIGNO_CLAC_REL: unqueued-receiver-com-spec{data-element=sri_P_SON_SIGN_FX_CLIGNO_CLAC_REL/P_SON_SIGN_FX_CLIGNO_CLAC_REL, handle-invalid=KEEP, init-value=cst_Boolean_init/boolean_init, resync-time=0.0}, required-interface=AR_IHM_SWC/sri_P_SON_SIGN_FX_CLIGNO_CLAC_REL
      rp_P_SON_SIGN_FX_CLIGNO_CLAC_R_REL: unqueued-receiver-com-spec{data-element=sri_P_SON_SIGN_FX_CLIGNO_CLAC_R_REL/P_SON_SIGN_FX_CLIGNO_CLAC_R_REL, handle-invalid=KEEP, init-value=cst_Boolean_init/boolean_init, resync-time=0.0}, required-interface=AR_IHM_SWC/sri_P_SON_SIGN_FX_CLIGNO_CLAC_R_REL
    provide port pp_CLIGNO_CLIC: unqueued-sender-com-spec{data-element=CLIGNO_CLIC, init-value=cst_Boolean_init/boolean_init}, provided-interface=sri_CLIGNO_CLIC
    provide port pp_CLIGNO_CLAC: unqueued-sender-com-spec{data-element=CLIGNO_CLAC, init-value=cst_Boolean_init/boolean_init}, provided-interface=sri_CLIGNO_CLAC
  internal behavior ib_IHM_CLIGNO: component=IHM_CLIGNO
    timing event evt_IHM_CLIGNO: start-on-event=IHM_CLIGNO, period=0.1
    runnable IHM_CLIGNO
      8 x data read access:
        dra_P_SON_SIGN_FX_CLIGNO_CLIC: data-element=rp_P_SON_SIGN_FX_CLIGNO_CLIC.P_SON_SIGN_FX_CLIGNO_CLIC
        dra_P_SON_SIGN_FX_CLIGNO_CLIC__3: data-element=rp_P_SON_SIGN_FX_CLIGNO_CLIC_R.P_SON_SIGN_FX_CLIGNO_CLIC_R
        dra_P_SON_SIGN_FX_CLIGNO_CLIC__2: data-element=rp_P_SON_SIGN_FX_CLIGNO_CLIC_REL.P_SON_SIGN_FX_CLIGNO_CLIC_REL
        dra_P_SON_SIGN_FX_CLIGNO_CLIC_R: data-element=rp_P_SON_SIGN_FX_CLIGNO_CLIC_R_REL.P_SON_SIGN_FX_CLIGNO_CLIC_R_REL
        dra_P_SON_SIGN_FX_CLIGNO_CLAC: data-element=rp_P_SON_SIGN_FX_CLIGNO_CLAC.P_SON_SIGN_FX_CLIGNO_CLAC
        dra_P_SON_SIGN_FX_CLIGNO_CLAC__3: data-element=rp_P_SON_SIGN_FX_CLIGNO_CLAC_R.P_SON_SIGN_FX_CLIGNO_CLAC_R
        dra_P_SON_SIGN_FX_CLIGNO_CLAC__2: data-element=rp_P_SON_SIGN_FX_CLIGNO_CLAC_REL.P_SON_SIGN_FX_CLIGNO_CLAC_REL
        dra_P_SON_SIGN_FX_CLIGNO_CLAC_R: data-element=rp_P_SON_SIGN_FX_CLIGNO_CLAC_R_REL.P_SON_SIGN_FX_CLIGNO_CLAC_R_REL
      data write access dwa_CLIGNO_CLIC: data-element=pp_CLIGNO_CLIC.CLIGNO_CLIC
      data write access dwa_CLIGNO_CLAC: data-element=pp_CLIGNO_CLAC.CLIGNO_CLAC
  8 x sender receiver interface:
    sri_P_SON_SIGN_FX_CLIGNO_CLIC
      data P_SON_SIGN_FX_CLIGNO_CLIC: type=AR_IHM_SWC/Boolean
    sri_P_SON_SIGN_FX_CLIGNO_CLIC_R
      data P_SON_SIGN_FX_CLIGNO_CLIC_R: type=AR_IHM_SWC/Boolean
    sri_P_SON_SIGN_FX_CLIGNO_CLIC_REL
      data P_SON_SIGN_FX_CLIGNO_CLIC_REL: type=AR_IHM_SWC/Boolean
    sri_P_SON_SIGN_FX_CLIGNO_CLIC_R_REL
      data P_SON_SIGN_FX_CLIGNO_CLIC_R_REL: type=AR_IHM_SWC/Boolean
    sri_P_SON_SIGN_FX_CLIGNO_CLAC
      data P_SON_SIGN_FX_CLIGNO_CLAC: type=AR_IHM_SWC/Boolean
    sri_P_SON_SIGN_FX_CLIGNO_CLAC_R
      data P_SON_SIGN_FX_CLIGNO_CLAC_R: type=AR_IHM_SWC/Boolean
    sri_P_SON_SIGN_FX_CLIGNO_CLAC_REL
      data P_SON_SIGN_FX_CLIGNO_CLAC_REL: type=AR_IHM_SWC/Boolean
    sri_P_SON_SIGN_FX_CLIGNO_CLAC_R_REL
      data P_SON_SIGN_FX_CLIGNO_CLAC_R_REL: type=AR_IHM_SWC/Boolean
  swc implementation implem_IHM_CLIGNO: programming-language=C, behavior=ib_IHM_CLIGNO
    code-descriptors:
      code implem_IHM_CLIGNO: type=SRC
        xfile IHM_CLIGNO.c: url=Src_C/IHM_CLIGNO.c
